VERSION ""

NS_ :

BS_:

BU_: ACM APIM APIM_CDC APIM_CIM APIM_CISM ARM DSP ESPM FCIMB GENERIC GWM HUD_ADV IPC MRCMB_RDAPM_HS3 RACM_RCIM TRM_ITRM TSTR WCM WCMB WCMC

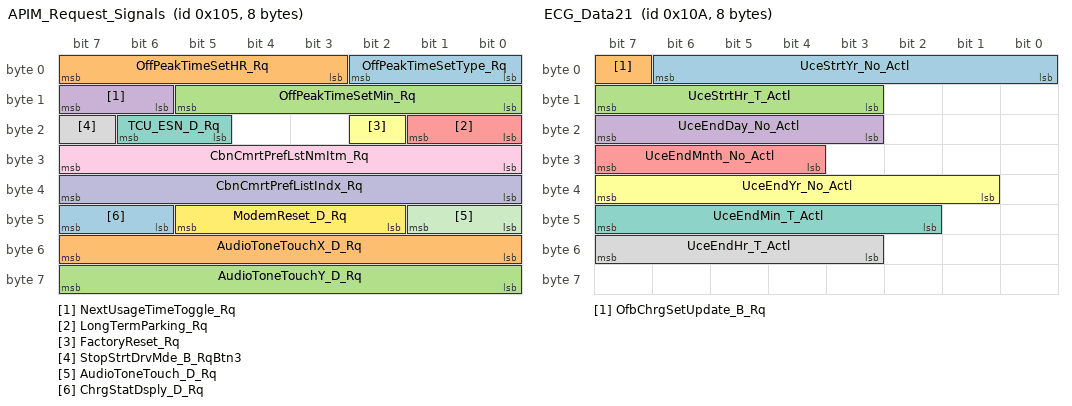
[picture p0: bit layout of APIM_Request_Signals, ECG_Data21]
BO_ 261 APIM_Request_Signals: 8 APIM_CDC
 SG_ OffPeakTimeSetType_Rq : 2|3@0+ (1,0) [0|7] "SED"  GWM
 SG_ OffPeakTimeSetHR_Rq : 7|5@0+ (1,0) [0|31] "unitless"  GWM
 SG_ OffPeakTimeSetMin_Rq : 13|6@0+ (1,0) [0|63] "unitless"  GWM
 SG_ NextUsageTimeToggle_Rq : 15|2@0+ (1,0) [0|3] "SED"  GWM
 SG_ LongTermParking_Rq : 17|2@0+ (1,0) [0|3] "SED"  GWM
 SG_ FactoryReset_Rq : 18|1@0+ (1,0) [0|1] "SED"  GWM
 SG_ TCU_ESN_D_Rq : 22|2@0+ (1,0) [0|3] "SED"  GWM
 SG_ StopStrtDrvMde_B_RqBtn3 : 23|1@0+ (1,0) [0|1] "SED"  GWM
 SG_ CbnCmrtPrefLstNmItm_Rq : 31|8@0+ (1,0) [0|255] "unitless"  GWM
 SG_ CbnCmrtPrefListIndx_Rq : 39|8@0+ (1,0) [0|255] "unitless"  GWM
 SG_ AudioToneTouch_D_Rq : 41|2@0+ (1,0) [0|3] "SED"  DSP,GWM
 SG_ ModemReset_D_Rq : 45|4@0+ (1,0) [0|15] "SED"  GWM
 SG_ ChrgStatDsply_D_Rq : 47|2@0+ (1,0) [0|3] "SED"  GWM
 SG_ AudioToneTouchX_D_Rq : 55|8@0+ (1,0) [0|255] "SED"  DSP,GWM
 SG_ AudioToneTouchY_D_Rq : 63|8@0+ (1,0) [0|255] "SED"  DSP,GWM

BO_ 262 APIM_Send_Signals_23: 8 APIM
 SG_ OnbChrgGlblAcMx_I_Rq : 7|8@0+ (1,0) [0|255] "ampere"  GWM
 SG_ OnbChrgSetUpdate_B_Rq : 8|1@0+ (1,0) [0|1] "SED"  GWM
 SG_ OnbChrgGlblDcMx_Pw_Rq : 15|7@0+ (5,0) [0|635] "kilowatt"  GWM
 SG_ OnbChrgSocAcMx_Pc_Rq : 23|7@0+ (1,0) [0|127] "percent"  GWM
 SG_ OnbChrgSocDcMx_Pc_Rq : 31|7@0+ (1,0) [0|127] "percent"  GWM

BO_ 266 ECG_Data21: 8 GWM
 SG_ UceStrtYr_No_Actl : 6|7@0+ (1,2017) [2017|2144] "year"  APIM
 SG_ OfbChrgSetUpdate_B_Rq : 7|1@0+ (1,0) [0|1] "SED"  APIM
 SG_ UceStrtHr_T_Actl : 15|5@0+ (1,0) [0|31] "hour"  APIM
 SG_ UceEndDay_No_Actl : 23|5@0+ (1,1) [1|32] "day"  APIM
 SG_ UceEndMnth_No_Actl : 31|4@0+ (1,1) [1|16] "month"  APIM
 SG_ UceEndYr_No_Actl : 39|7@0+ (1,2017) [2017|2144] "year"  APIM
 SG_ UceEndMin_T_Actl : 47|6@0+ (1,0) [0|63] "minute"  APIM
 SG_ UceEndHr_T_Actl : 55|5@0+ (1,0) [0|31] "hour"  APIM

BO_ 267 IntelPwrData2_HS3: 8 GWM
 SG_ BattChrgIn_E_Actl : 7|12@0+ (50,0) [0|204750] "watt*hour" Vector__XXX
 SG_ BattChrgOut_E_Actl : 11|12@0+ (50,0) [0|204750] "watt*hour" Vector__XXX
 SG_ UceDchrg_E_Actl : 31|12@0+ (50,0) [0|204750] "watt*hour" Vector__XXX
 SG_ GridSrvc02_D_Stat : 35|4@0+ (1,0) [0|15] "SED"  APIM
 SG_ IpwEnbl_B_Stat : 40|1@0+ (1,0) [0|1] "SED"  APIM
 SG_ IpwSocMn_Pc_Actl : 47|7@0+ (1,0) [0|127] "percent" Vector__XXX

BO_ 270 ECG_IntelPwrData6: 8 GWM
 SG_ UceStrtDay_No_Actl : 7|5@0+ (1,1) [1|32] "day"  APIM
 SG_ UceStrtMin_T_Actl : 15|6@0+ (1,0) [0|63] "minute"  APIM
 SG_ UceStrtMnth_No_Actl : 23|4@0+ (1,1) [1|16] "month"  APIM

BO_ 282 ECG_Data15_HS3: 8 GWM
 SG_ HudPersFeat_No_Rq : 7|16@0+ (1,0) [0|65535] "unitless"  HUD_ADV
 SG_ HudPersFeatVal_No_Rq : 23|16@0+ (1,0) [0|65535] "unitless"  HUD_ADV
 SG_ HudPersSrvc_D_Rq : 36|3@0+ (1,0) [0|7] "SED"  HUD_ADV
 SG_ HudPersIndx_No_Rq : 39|3@0+ (1,0) [0|7] "SED"  HUD_ADV
 SG_ HudPersSrvcId_No_Rq : 47|3@0+ (1,0) [0|7] "unitless"  HUD_ADV

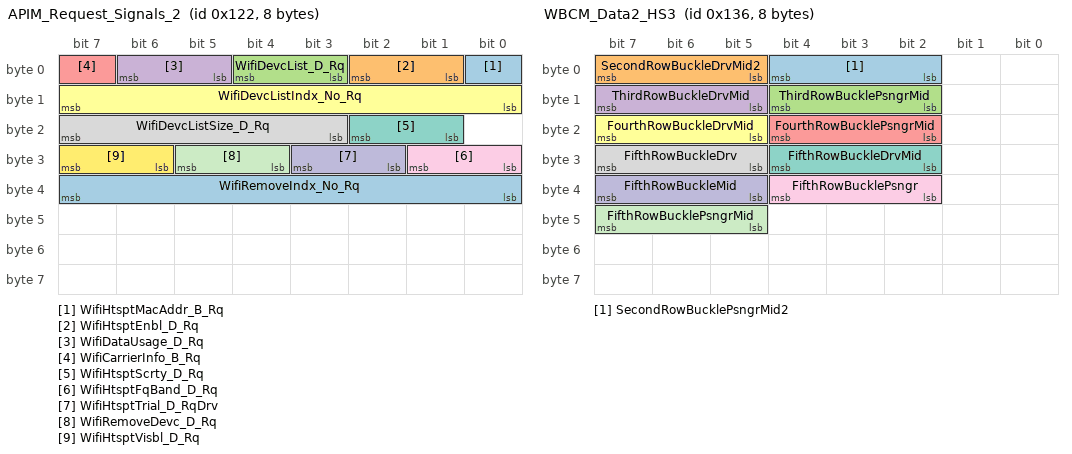
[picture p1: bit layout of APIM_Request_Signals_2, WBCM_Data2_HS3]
BO_ 290 APIM_Request_Signals_2: 8 APIM_CDC
 SG_ WifiHtsptMacAddr_B_Rq : 0|1@0+ (1,0) [0|1] "SED"  GWM
 SG_ WifiHtsptEnbl_D_Rq : 2|2@0+ (1,0) [0|3] "SED"  GWM
 SG_ WifiDevcList_D_Rq : 4|2@0+ (1,0) [0|3] "SED"  GWM
 SG_ WifiDataUsage_D_Rq : 6|2@0+ (1,0) [0|3] "SED"  GWM
 SG_ WifiCarrierInfo_B_Rq : 7|1@0+ (1,0) [0|1] "SED"  GWM
 SG_ WifiDevcListIndx_No_Rq : 15|8@0+ (1,0) [0|255] "unitless"  GWM
 SG_ WifiHtsptScrty_D_Rq : 18|2@0+ (1,0) [0|3] "SED"  GWM
 SG_ WifiDevcListSize_D_Rq : 23|5@0+ (1,0) [0|31] "unitless"  GWM
 SG_ WifiHtsptFqBand_D_Rq : 25|2@0+ (1,0) [0|3] "SED"  GWM
 SG_ WifiHtsptTrial_D_RqDrv : 27|2@0+ (1,0) [0|3] "SED"  GWM
 SG_ WifiRemoveDevc_D_Rq : 29|2@0+ (1,0) [0|3] "SED"  GWM
 SG_ WifiHtsptVisbl_D_Rq : 31|2@0+ (1,0) [0|3] "SED"  GWM
 SG_ WifiRemoveIndx_No_Rq : 39|8@0+ (1,0) [0|255] "unitless"  GWM

BO_ 291 HEC_Response_Signals: 8 IPC
 SG_ LangUpdate_Rsp : 7|2@0+ (1,0) [0|3] "SED"  APIM,APIM_CISM

BO_ 293 ClmtCtrlSeatSet_Stat_v2_HS3: 8 GWM
 SG_ ClmtCtrlSeat_SetStat_Dvr : 7|8@0+ (1,0) [0|254] "SED" Vector__XXX
 SG_ ClmtCtrlSeat_SetStat_Psgr : 15|8@0+ (1,0) [0|254] "SED" Vector__XXX
 SG_ PdlAutoSav_D_Stat : 19|2@0+ (1,0) [0|3] "SED"  APIM_CDC,APIM_CIM
 SG_ SeatAutoSavDrv_D_Stat : 21|2@0+ (1,0) [0|3] "SED"  APIM_CDC,APIM_CIM
 SG_ SteAutoSav_D_Stat : 23|2@0+ (1,0) [0|3] "SED"  APIM_CDC,APIM_CIM

BO_ 298 SDARS_Status_Msg_3: 8 APIM_CDC
 SG_ SdarsSrvcId_No2_Actl2 : 7|16@0+ (1,0) [0|65535] "Unitless"  ACM,IPC,RACM_RCIM

BO_ 300 Av_VdsPrimData_HS3: 8 GWM
 SG_ VdsSftyDrv_D_Rq : 15|2@0+ (1,0) [0|3] "SED"  APIM_CDC
 SG_ PwTest_B_Rdy : 63|1@0+ (1,0) [0|1] "SED" Vector__XXX

BO_ 303 Body_Info_16_HS3: 8 GWM
 SG_ CanMsg12F_No_Crc : 7|8@0+ (1,0) [0|255] "Unitless"  APIM_CDC,APIM_CIM,IPC
 SG_ CanMsg12F_No_Cnt : 11|4@0+ (1,0) [0|15] "Unitless"  APIM_CDC,APIM_CIM,IPC
 SG_ CanMsg12F_UNUSED_1bit_1 : 12|1@0+ (1,0) [1|1] "unitless"  APIM_CDC,APIM_CIM,IPC
 SG_ DrStatHood_D2_Actl : 15|3@0+ (1,0) [0|7] "SED"  APIM_CDC,APIM_CIM,IPC
 SG_ CanMsg12F_UNUSED_2bit_1 : 17|2@0+ (1,0) [3|3] "unitless"  APIM_CDC,APIM_CIM,IPC
 SG_ CanMsg12F_UNUSED_3bit_1 : 20|3@0+ (1,0) [7|7] "unitless"  APIM_CDC,APIM_CIM,IPC
 SG_ DrChildLckPw_No_Actl : 23|3@0+ (1,0) [0|7] "unitless"  APIM_CDC,APIM_CIM,IPC
 SG_ DrTgateAjar_D_Stat : 25|2@0+ (1,0) [0|3] "SED"  IPC
 SG_ DrSwtchExtFr_No_Actl : 28|3@0+ (1,0) [0|7] "unitless" Vector__XXX
 SG_ DrSwtchExtFl_No_Actl : 31|3@0+ (1,0) [0|7] "unitless" Vector__XXX
 SG_ CanMsg12F_UNUSED_2bit_2 : 33|2@0+ (1,0) [3|3] "unitless"  APIM_CDC,APIM_CIM,IPC
 SG_ DrSwtchExtRr_No_Actl : 36|3@0+ (1,0) [0|7] "unitless" Vector__XXX
 SG_ DrSwtchExtRl_No_Actl : 39|3@0+ (1,0) [0|7] "unitless" Vector__XXX
 SG_ CanMsg12F_UNUSED_2bit_3 : 41|2@0+ (1,0) [3|3] "unitless"  APIM_CDC,APIM_CIM,IPC
 SG_ DrSwtchInnrFr_No_Actl : 44|3@0+ (1,0) [0|7] "unitless" Vector__XXX
 SG_ DrSwtchInnrFl_No_Actl : 47|3@0+ (1,0) [0|7] "unitless" Vector__XXX
 SG_ CanMsg12F_UNUSED_2bit_4 : 49|2@0+ (1,0) [3|3] "unitless"  APIM_CDC,APIM_CIM,IPC
 SG_ DrSwtchInnrRr_No_Actl : 52|3@0+ (1,0) [0|7] "unitless" Vector__XXX
 SG_ DrSwtchInnrRl_No_Actl : 55|3@0+ (1,0) [0|7] "unitless" Vector__XXX
 SG_ CanMsg12F_UNUSED_8bit_1 : 63|8@0+ (1,0) [255|255] "unitless"  APIM_CDC,APIM_CIM,IPC

BO_ 307 Av_BrkPrimData_01_HS3: 8 GWM
 SG_ BrkVlePrim_No_Cs : 7|8@0+ (1,0) [0|255] "unitless" Vector__XXX
 SG_ BrkVlePrim_No_Cnt : 11|4@0+ (1,0) [0|15] "unitless" Vector__XXX
 SG_ BrkAbsPrim_B_Falt : 16|1@0+ (1,0) [0|1] "SED" Vector__XXX
 SG_ BrkDfaltPrim_B_Stat : 17|1@0+ (1,0) [0|1] "SED" Vector__XXX
 SG_ BrkEbdPrim_B_Falt : 18|1@0+ (1,0) [0|1] "SED" Vector__XXX
 SG_ BrkEpbPrim_B_Falt : 19|1@0+ (1,0) [0|1] "SED" Vector__XXX
 SG_ BrkRedndncyPrim_B_Falt : 20|1@0+ (1,0) [0|1] "SED" Vector__XXX
 SG_ BrkStabCtlPrim_B_Falt : 21|1@0+ (1,0) [0|1] "SED" Vector__XXX
 SG_ BrkTracCtlPrim_B_Falt : 22|1@0+ (1,0) [0|1] "SED" Vector__XXX
 SG_ AvmcPrim_No_Cs : 31|8@0+ (1,0) [0|255] "unitless" Vector__XXX
 SG_ AvmcPrim_No_Cnt : 35|4@0+ (1,0) [0|15] "unitless" Vector__XXX
 SG_ AvMtnCtlPrim_D_Stat : 38|3@0+ (1,0) [0|7] "SED"  APIM_CDC
 SG_ PrkPrim_B_Stat : 40|1@0+ (1,0) [0|1] "SED"  APIM_CDC
 SG_ MobcVLimPrim_D_Stat : 42|2@0+ (1,0) [0|3] "SED"  APIM_CDC
 SG_ LongCtlSrcPrim_D_Actl : 44|2@0+ (1,0) [0|3] "SED" Vector__XXX
 SG_ GearLvrPrim_D_Rq : 47|3@0+ (1,0) [0|7] "SED" Vector__XXX
 SG_ PrplWhlTotPrim1_Tq_Rq : 55|16@0+ (4,-131072) [-131072|131068] "Nm" Vector__XXX

BO_ 310 WBCM_Data2_HS3: 8 GWM
 SG_ SecondRowBucklePsngrMid2 : 4|3@0+ (1,0) [0|7] "SED"  APIM_CDC,APIM_CIM,IPC
 SG_ SecondRowBuckleDrvMid2 : 7|3@0+ (1,0) [0|7] "SED"  APIM_CDC,APIM_CIM,IPC
 SG_ ThirdRowBucklePsngrMid : 12|3@0+ (1,0) [0|7] "SED"  APIM_CDC,APIM_CIM,IPC
 SG_ ThirdRowBuckleDrvMid : 15|3@0+ (1,0) [0|7] "SED"  APIM_CDC,APIM_CIM,IPC
 SG_ FourthRowBucklePsngrMid : 20|3@0+ (1,0) [0|7] "SED"  APIM_CDC,APIM_CIM,IPC
 SG_ FourthRowBuckleDrvMid : 23|3@0+ (1,0) [0|7] "SED"  APIM_CDC,APIM_CIM,IPC
 SG_ FifthRowBuckleDrvMid : 28|3@0+ (1,0) [0|7] "SED"  APIM_CDC,APIM_CIM,IPC
 SG_ FifthRowBuckleDrv : 31|3@0+ (1,0) [0|7] "SED"  APIM_CDC,APIM_CIM,IPC
 SG_ FifthRowBucklePsngr : 36|3@0+ (1,0) [0|7] "SED"  APIM_CDC,APIM_CIM,IPC
 SG_ FifthRowBuckleMid : 39|3@0+ (1,0) [0|7] "SED"  APIM_CDC,APIM_CIM,IPC
 SG_ FifthRowBucklePsngrMid : 47|3@0+ (1,0) [0|7] "SED"  APIM_CDC,APIM_CIM,IPC

BO_ 317 APIM_Send_Signals_22: 8 APIM_CIM
 SG_ VehPtch_An_Actl : 7|8@0+ (1,-90) [-90|165] "degrees"  GWM

BO_ 330 TransData_3_HS3: 8 GWM
 SG_ TrnFaltOpenClu_B_Stat : 5|1@0+ (1,0) [0|1] "SED" Vector__XXX
 SG_ TrnAout_W_ActlUnfilt : 22|15@0+ (0.1,0) [0|3276.7] "rad/s"  ACM,APIM_CDC,APIM_CIM,APIM_CISM

BO_ 331 HEV_Powertrain_Data5_HS3: 8 GWM
 SG_ TrnAout2ActlUflt_No_Cs : 7|8@0+ (1,0) [0|255] "unitless" Vector__XXX
 SG_ TrnAout2ActUflt_No_Cnt : 15|4@0+ (1,0) [0|15] "unitless" Vector__XXX
 SG_ TrnAout2_W_ActlUnfilt : 23|16@0+ (0.1,-3276.5) [-3276.5|3277] "rad/s"  ACM,APIM_CDC,APIM_CIM,APIM_CISM
 SG_ HtrnAin_N_RqMnPrtct : 36|13@0+ (2,0) [0|16382] "RPM" Vector__XXX
 SG_ CmbbEngTqMn_B_ActlHtrn : 37|1@0+ (1,0) [0|1] "SED" Vector__XXX
 SG_ CmbbDeny_B_ActlHtrn : 38|1@0+ (1,0) [0|1] "SED" Vector__XXX

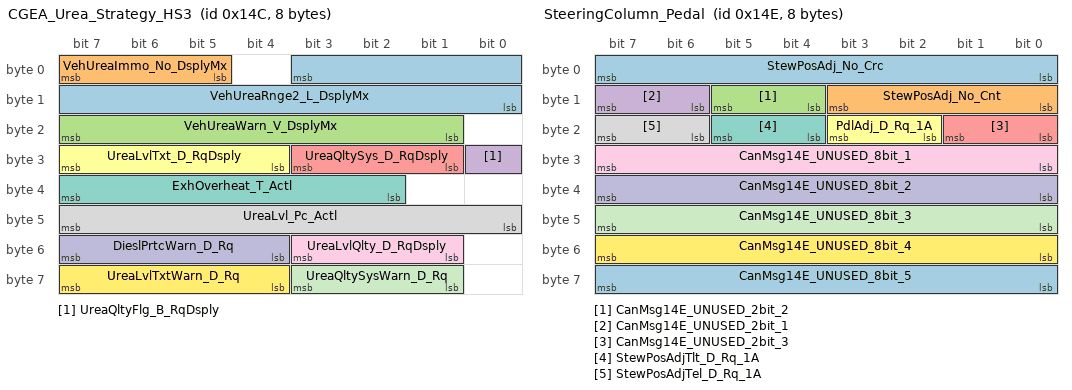
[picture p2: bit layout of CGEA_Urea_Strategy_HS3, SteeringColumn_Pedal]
BO_ 332 CGEA_Urea_Strategy_HS3: 8 GWM
 SG_ VehUreaRnge2_L_DsplyMx : 3|12@0+ (1,0) [0|4095] "kilometer"  APIM_CDC,APIM_CIM,APIM_CISM,IPC
 SG_ VehUreaImmo_No_DsplyMx : 7|3@0+ (1,0) [0|7] "Counts"  APIM_CDC,APIM_CIM,IPC
 SG_ VehUreaWarn_V_DsplyMx : 23|7@0+ (1,0) [0|127] "km/h"  APIM_CDC,APIM_CIM,APIM_CISM,IPC
 SG_ UreaQltyFlg_B_RqDsply : 24|1@0+ (1,0) [0|1] "SED"  APIM_CDC,APIM_CIM,APIM_CISM,IPC
 SG_ UreaQltySys_D_RqDsply : 27|3@0+ (1,0) [0|7] "SED"  APIM_CDC,APIM_CIM,APIM_CISM,IPC
 SG_ UreaLvlTxt_D_RqDsply : 31|4@0+ (1,0) [0|15] "SED"  APIM_CDC,APIM_CIM,APIM_CISM,IPC
 SG_ ExhOverheat_T_Actl : 39|6@0+ (1,0) [0|63] "minute"  APIM_CDC,APIM_CIM,IPC
 SG_ UreaLvl_Pc_Actl : 47|8@0+ (0.4,0) [0|102] "percent"  APIM_CDC,APIM_CIM,APIM_CISM,IPC
 SG_ UreaLvlQlty_D_RqDsply : 51|3@0+ (1,0) [0|7] "SED"  APIM_CDC,APIM_CIM,APIM_CISM,IPC
 SG_ DieslPrtcWarn_D_Rq : 55|4@0+ (1,0) [0|15] "SED"  APIM_CDC,APIM_CIM,IPC
 SG_ UreaQltySysWarn_D_Rq : 59|3@0+ (1,0) [0|7] "SED"  APIM_CDC,APIM_CIM,APIM_CISM,IPC
 SG_ UreaLvlTxtWarn_D_Rq : 63|4@0+ (1,0) [0|15] "SED"  APIM_CDC,APIM_CIM,APIM_CISM,IPC

BO_ 333 HEV_Powertrain_Data11_HS3: 8 GWM
 SG_ VehElAvgTrip1_Eff2_Dsply : 7|11@0+ (1,-200) [-200|1847] "watt*hour/km"  APIM,IPC
 SG_ VehElAvgTrip2_Eff2_Dsply : 12|11@0+ (1,-200) [-200|1847] "watt*hour/km"  APIM,IPC
 SG_ VehElEffTrip_No2_Dsply : 17|11@0+ (1,-200) [-200|1847] "watt*hour/km"  APIM,IPC
 SG_ VehElEffAvg_No2_Dsply : 38|11@0+ (1,-200) [-200|1847] "watt*hour/km"  APIM,IPC

BO_ 334 SteeringColumn_Pedal: 8 APIM_CDC
 SG_ StewPosAdj_No_Crc : 7|8@0+ (1,0) [0|255] "unitless"  GWM
 SG_ StewPosAdj_No_Cnt : 11|4@0+ (1,0) [0|15] "unitless"  GWM
 SG_ CanMsg14E_UNUSED_2bit_2 : 13|2@0+ (1,0) [3|3] "unitless"  GWM
 SG_ CanMsg14E_UNUSED_2bit_1 : 15|2@0+ (1,0) [3|3] "unitless"  GWM
 SG_ CanMsg14E_UNUSED_2bit_3 : 17|2@0+ (1,0) [3|3] "unitless"  GWM
 SG_ PdlAdj_D_Rq_1A : 19|2@0+ (1,0) [0|3] "SED"  GWM
 SG_ StewPosAdjTlt_D_Rq_1A : 21|2@0+ (1,0) [0|3] "SED"  GWM
 SG_ StewPosAdjTel_D_Rq_1A : 23|2@0+ (1,0) [0|3] "SED"  GWM
 SG_ CanMsg14E_UNUSED_8bit_1 : 31|8@0+ (1,0) [255|255] "unitless"  GWM
 SG_ CanMsg14E_UNUSED_8bit_2 : 39|8@0+ (1,0) [255|255] "unitless"  GWM
 SG_ CanMsg14E_UNUSED_8bit_3 : 47|8@0+ (1,0) [255|255] "unitless"  GWM
 SG_ CanMsg14E_UNUSED_8bit_4 : 55|8@0+ (1,0) [255|255] "unitless"  GWM
 SG_ CanMsg14E_UNUSED_8bit_5 : 63|8@0+ (1,0) [255|255] "unitless"  GWM

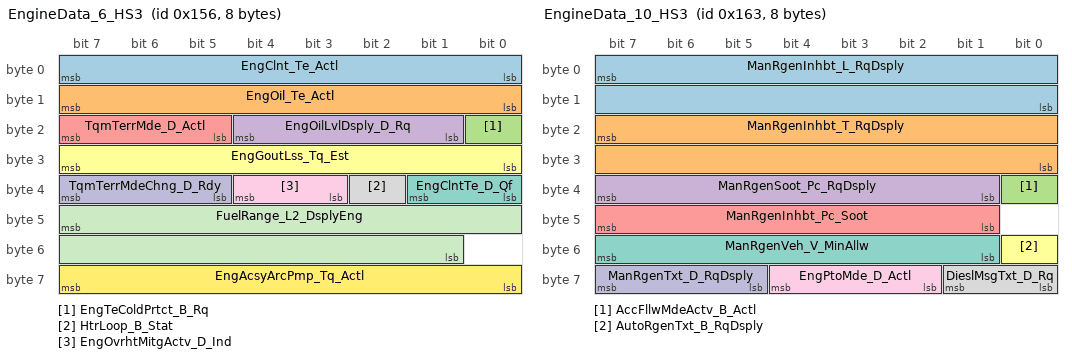
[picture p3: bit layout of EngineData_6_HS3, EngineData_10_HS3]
BO_ 342 EngineData_6_HS3: 8 GWM
 SG_ EngClnt_Te_Actl : 7|8@0+ (1,-60) [-60|195] "degC"  APIM,APIM_CDC,APIM_CIM,APIM_CISM,IPC
 SG_ EngOil_Te_Actl : 15|8@0+ (1,-60) [-60|195] "degC"  APIM,APIM_CDC,APIM_CIM,APIM_CISM,IPC
 SG_ EngTeColdPrtct_B_Rq : 16|1@0+ (1,0) [0|1] "SED"  APIM_CDC,APIM_CIM,IPC
 SG_ EngOilLvlDsply_D_Rq : 20|4@0+ (1,0) [0|15] "SED"  APIM_CDC,APIM_CIM,IPC
 SG_ TqmTerrMde_D_Actl : 23|3@0+ (1,0) [0|7] "SED"  IPC
 SG_ EngGoutLss_Tq_Est : 31|8@0+ (1,0) [0|255] "Nm"  IPC
 SG_ EngClntTe_D_Qf : 33|2@0+ (1,0) [0|3] "SED"  APIM_CDC,APIM_CIM,IPC
 SG_ HtrLoop_B_Stat : 34|1@0+ (1,0) [0|1] "SED"  IPC
 SG_ EngOvrhtMitgActv_D_Ind : 36|2@0+ (1,0) [0|3] "SED"  APIM_CDC,APIM_CIM,IPC
 SG_ TqmTerrMdeChng_D_Rdy : 39|3@0+ (1,0) [0|7] "SED"  IPC
 SG_ FuelRange_L2_DsplyEng : 47|15@0+ (0.1,0) [0|3276.7] "kilometer"  APIM_CDC,APIM_CIM,IPC
 SG_ EngAcsyArcPmp_Tq_Actl : 63|8@0+ (0.5,0) [0|127.5] "Nm"  IPC

BO_ 355 EngineData_10_HS3: 8 GWM
 SG_ ManRgenInhbt_L_RqDsply : 7|16@0+ (1,0) [0|65535] "kilometer"  APIM_CDC,APIM_CIM,APIM_CISM,IPC
 SG_ ManRgenInhbt_T_RqDsply : 23|16@0+ (1,0) [0|65535] "minute"  APIM_CDC,APIM_CIM,APIM_CISM,IPC
 SG_ AccFllwMdeActv_B_Actl : 32|1@0+ (1,0) [0|1] "SED"  GENERIC
 SG_ ManRgenSoot_Pc_RqDsply : 39|7@0+ (1,0) [0|127] "%"  APIM_CDC,APIM_CIM,APIM_CISM,IPC
 SG_ ManRgenInhbt_Pc_Soot : 47|7@0+ (1,0) [0|127] "%"  APIM_CDC,APIM_CIM,APIM_CISM,IPC
 SG_ AutoRgenTxt_B_RqDsply : 48|1@0+ (1,0) [0|1] "SED"  APIM_CDC,APIM_CIM,IPC
 SG_ ManRgenVeh_V_MinAllw : 55|7@0+ (1,0) [0|127] "kilometer/hour"  APIM_CDC,APIM_CIM,APIM_CISM,IPC
 SG_ DieslMsgTxt_D_Rq : 57|2@0+ (1,0) [0|3] "SED"  APIM_CDC,APIM_CIM,IPC
 SG_ EngPtoMde_D_Actl : 60|3@0+ (1,0) [0|7] "SED"  IPC
 SG_ ManRgenTxt_D_RqDsply : 63|3@0+ (1,0) [0|7] "SED"  APIM_CDC,APIM_CIM,APIM_CISM,IPC

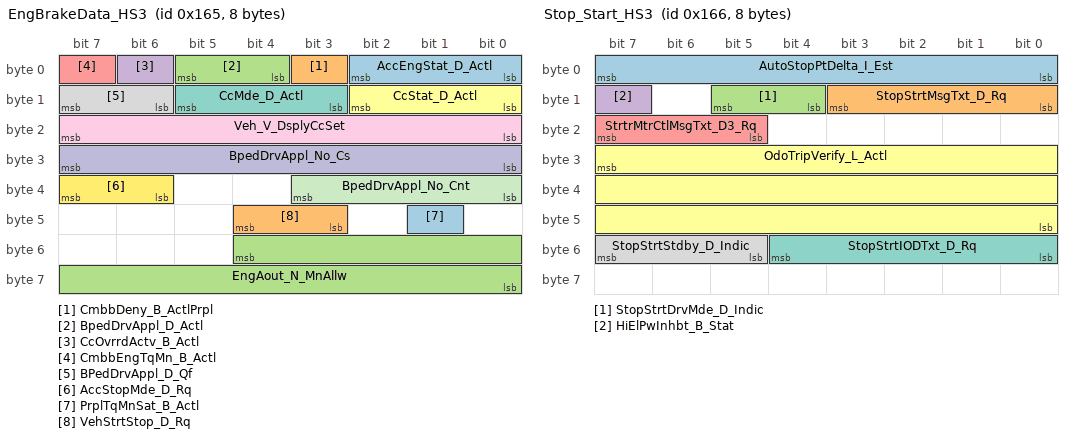
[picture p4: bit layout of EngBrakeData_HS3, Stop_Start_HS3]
BO_ 357 EngBrakeData_HS3: 8 GWM
 SG_ AccEngStat_D_Actl : 2|3@0+ (1,0) [0|7] "SED" Vector__XXX
 SG_ CmbbDeny_B_ActlPrpl : 3|1@0+ (1,0) [0|1] "SED" Vector__XXX
 SG_ BpedDrvAppl_D_Actl : 5|2@0+ (1,0) [0|3] "SED"  APIM,APIM_CDC,APIM_CIM,APIM_CISM,IPC,TRM_ITRM
 SG_ CcOvrrdActv_B_Actl : 6|1@0+ (1,0) [0|1] "SED"  APIM_CDC,APIM_CIM,HUD_ADV,IPC
 SG_ CmbbEngTqMn_B_Actl : 7|1@0+ (1,0) [0|1] "SED" Vector__XXX
 SG_ CcStat_D_Actl : 10|3@0+ (1,0) [0|7] "SED"  APIM_CDC,APIM_CIM,HUD_ADV,IPC
 SG_ CcMde_D_Actl : 13|3@0+ (1,0) [0|7] "SED" Vector__XXX
 SG_ BPedDrvAppl_D_Qf : 15|2@0+ (1,0) [0|3] "SED" Vector__XXX
 SG_ Veh_V_DsplyCcSet : 23|8@0+ (1,0) [0|255] "unitless"  APIM_CDC,APIM_CIM,HUD_ADV,IPC
 SG_ BpedDrvAppl_No_Cs : 31|8@0+ (1,0) [0|255] "unitless" Vector__XXX
 SG_ BpedDrvAppl_No_Cnt : 35|4@0+ (1,0) [0|15] "unitless" Vector__XXX
 SG_ AccStopMde_D_Rq : 39|2@0+ (1,0) [0|3] "SED" Vector__XXX
 SG_ PrplTqMnSat_B_Actl : 41|1@0+ (1,0) [0|1] "SED" Vector__XXX
 SG_ VehStrtStop_D_Rq : 44|2@0+ (1,0) [0|3] "SED" Vector__XXX
 SG_ EngAout_N_MnAllw : 52|13@0+ (2,0) [0|16382] "rpm" Vector__XXX

BO_ 358 Stop_Start_HS3: 8 GWM
 SG_ AutoStopPtDelta_I_Est : 7|8@0+ (1,-127) [-127|128] "Amps"  GENERIC
 SG_ StopStrtMsgTxt_D_Rq : 11|4@0+ (1,0) [0|15] "SED"  APIM_CDC,APIM_CIM,IPC
 SG_ StopStrtDrvMde_D_Indic : 13|2@0+ (1,0) [0|3] "SED"  APIM,APIM_CDC,APIM_CIM,APIM_CISM,IPC
 SG_ HiElPwInhbt_B_Stat : 15|1@0+ (1,0) [0|1] "SED"  GENERIC
 SG_ StrtrMtrCtlMsgTxt_D3_Rq : 23|3@0+ (1,0) [0|7] "SED"  APIM,APIM_CDC,APIM_CIM
 SG_ OdoTripVerify_L_Actl : 31|24@0+ (0.1,0) [0|1677721.5] "km"  APIM_CDC,APIM_CIM,IPC
 SG_ StopStrtIODTxt_D_Rq : 52|5@0+ (1,0) [0|31] "SED"  APIM_CDC,APIM_CIM,APIM_CISM,IPC
 SG_ StopStrtStdby_D_Indic : 55|3@0+ (1,0) [0|7] "SED"  APIM_CDC,APIM_CIM,APIM_CISM,IPC

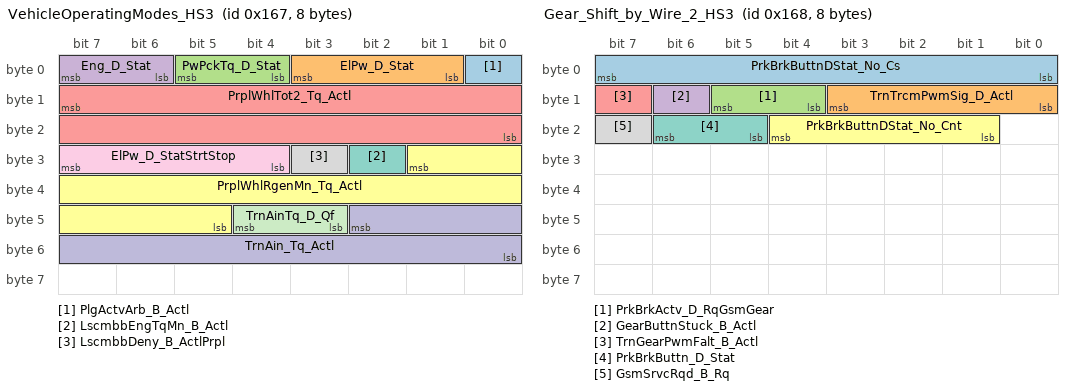
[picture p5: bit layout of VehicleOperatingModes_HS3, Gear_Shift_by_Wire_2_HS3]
BO_ 359 VehicleOperatingModes_HS3: 8 GWM
 SG_ PlgActvArb_B_Actl : 0|1@0+ (1,0) [0|1] "SED"  APIM_CDC,IPC
 SG_ ElPw_D_Stat : 3|3@0+ (1,0) [0|7] "SED"  ACM,APIM,APIM_CDC,APIM_CIM,APIM_CISM,DSP,IPC,RACM_RCIM,TRM_ITRM
 SG_ PwPckTq_D_Stat : 5|2@0+ (1,0) [0|3] "SED"  ACM,APIM,APIM_CDC,APIM_CIM,APIM_CISM,DSP,IPC,RACM_RCIM,TRM_ITRM,WCM,WCMB,WCMC
 SG_ Eng_D_Stat : 7|2@0+ (1,0) [0|3] "SED"  ACM,APIM,APIM_CDC,APIM_CIM,APIM_CISM,DSP,RACM_RCIM,TRM_ITRM,WCM,WCMB,WCMC
 SG_ PrplWhlTot2_Tq_Actl : 15|16@0+ (4,-131072) [-131072|131068] "Nm"  APIM,APIM_CDC,APIM_CIM,APIM_CISM,IPC
 SG_ PrplWhlRgenMn_Tq_Actl : 25|13@0+ (4,-16380) [-16380|16384] "Nm"  GENERIC
 SG_ LscmbbEngTqMn_B_Actl : 26|1@0+ (1,0) [0|1] "SED"  GENERIC
 SG_ LscmbbDeny_B_ActlPrpl : 27|1@0+ (1,0) [0|1] "SED"  GENERIC
 SG_ ElPw_D_StatStrtStop : 31|4@0+ (1,0) [0|15] "SED"  GENERIC
 SG_ TrnAin_Tq_Actl : 42|11@0+ (1,-500) [-500|1547] "Nm"  ACM,APIM,APIM_CDC,APIM_CIM,APIM_CISM,IPC
 SG_ TrnAinTq_D_Qf : 44|2@0+ (1,0) [0|3] "SED"  APIM_CIM,ACM,APIM_CDC,APIM_CISM

BO_ 360 Gear_Shift_by_Wire_2_HS3: 8 GWM
 SG_ PrkBrkButtnDStat_No_Cs : 7|8@0+ (1,0) [0|255] "unitless" Vector__XXX
 SG_ TrnTrcmPwmSig_D_Actl : 11|4@0+ (1,0) [0|15] "SED"  GENERIC
 SG_ PrkBrkActv_D_RqGsmGear : 13|2@0+ (1,0) [0|3] "SED" Vector__XXX
 SG_ GearButtnStuck_B_Actl : 14|1@0+ (1,0) [0|1] "SED"  GENERIC
 SG_ TrnGearPwmFalt_B_Actl : 15|1@0+ (1,0) [0|1] "SED"  GENERIC
 SG_ PrkBrkButtnDStat_No_Cnt : 20|4@0+ (1,0) [0|15] "unitless" Vector__XXX
 SG_ PrkBrkButtn_D_Stat : 22|2@0+ (1,0) [0|3] "SED" Vector__XXX
 SG_ GsmSrvcRqd_B_Rq : 23|1@0+ (1,0) [0|1] "SED"  APIM_CDC,APIM_CIM,IPC

BO_ 366 Av_RDAPM_Data4: 8 MRCMB_RDAPM_HS3
 SG_ AprTvfTripId1_No_Actl : 7|64@0+ (1,0) [0|1.84467440737096E+019] "unitless"  GWM

BO_ 367 Av_ECGtoDAP_HS3: 8 GWM
 SG_ AuthctnInfoId_No_Actl : 7|32@0+ (1,0) [0|4294967295] "unitless"  MRCMB_RDAPM_HS3
 SG_ AuthctnInfo_D_Stat : 33|2@0+ (1,0) [0|3] "SED"  MRCMB_RDAPM_HS3
 SG_ AuthctnInfoIndx_No_Actl : 39|6@0+ (1,0) [0|63] "unitless"  MRCMB_RDAPM_HS3
 SG_ AuthctnStat_D_Stat : 44|2@0+ (1,0) [0|3] "SED"  MRCMB_RDAPM_HS3
 SG_ AuthctnInfoLoc_D_Stat : 47|3@0+ (1,0) [0|7] "SED"  MRCMB_RDAPM_HS3
 SG_ AuthctnStatChnl_D_Stat : 51|4@0+ (1,0) [0|15] "SED"  MRCMB_RDAPM_HS3
 SG_ AuthctnStatRtry_No_Actl : 55|4@0+ (1,0) [0|15] "unitless"  MRCMB_RDAPM_HS3
 SG_ AuthctnStatId_No_Actl : 63|32@0+ (1,0) [0|4294967295] "unitless"  MRCMB_RDAPM_HS3
 SG_ ApnlPsswrdId_No_Actl : 95|32@0+ (1,0) [0|4294967295] "unitless"  MRCMB_RDAPM_HS3
 SG_ ApnlPsswrdType_D_Stat : 121|4@0+ (1,0) [0|15] "SED"  MRCMB_RDAPM_HS3
 SG_ AuthctnStatIndx_No_Actl : 127|6@0+ (1,0) [0|63] "unitless"  MRCMB_RDAPM_HS3
 SG_ ApnlPsswrdIndx_No_Actl : 133|6@0+ (1,0) [0|63] "unitless"  MRCMB_RDAPM_HS3
 SG_ HashId_No_Actl : 143|32@0+ (1,0) [0|4294967295] "unitless"  MRCMB_RDAPM_HS3
 SG_ HashIndx_D_Stat : 169|2@0+ (1,0) [0|3] "SED"  MRCMB_RDAPM_HS3
 SG_ HashIndx_No_Actl : 175|6@0+ (1,0) [0|63] "unitless"  MRCMB_RDAPM_HS3
 SG_ HashSalt1_No_Res : 183|64@0+ (1,0) [0|1.84467440737096E+019] "unitless"  MRCMB_RDAPM_HS3
 SG_ HashSalt2_No_Res : 247|64@0+ (1,0) [0|1.84467440737096E+019] "unitless"  MRCMB_RDAPM_HS3
 SG_ HashNonce1_No_Res : 311|64@0+ (1,0) [0|1.84467440737096E+019] "unitless"  MRCMB_RDAPM_HS3
 SG_ HashNonce2_No_Res : 375|64@0+ (1,0) [0|1.84467440737096E+019] "unitless"  MRCMB_RDAPM_HS3

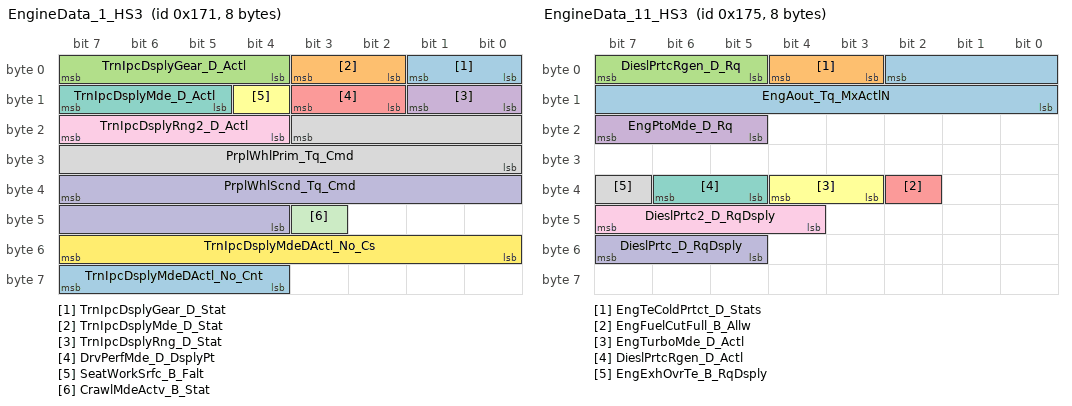
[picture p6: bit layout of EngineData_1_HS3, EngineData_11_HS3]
BO_ 369 EngineData_1_HS3: 8 GWM
 SG_ TrnIpcDsplyGear_D_Stat : 1|2@0+ (1,0) [0|3] "SED"  APIM_CDC,APIM_CIM,HUD_ADV,IPC
 SG_ TrnIpcDsplyMde_D_Stat : 3|2@0+ (1,0) [0|3] "SED"  APIM_CDC,APIM_CIM,HUD_ADV,IPC
 SG_ TrnIpcDsplyGear_D_Actl : 7|4@0+ (1,0) [0|15] "SED"  APIM,APIM_CDC,APIM_CIM,APIM_CISM,HUD_ADV,IPC
 SG_ TrnIpcDsplyRng_D_Stat : 9|2@0+ (1,0) [0|3] "SED"  APIM_CDC,APIM_CIM,IPC
 SG_ DrvPerfMde_D_DsplyPt : 11|2@0+ (1,0) [0|3] "SED"  GENERIC
 SG_ SeatWorkSrfc_B_Falt : 12|1@0+ (1,0) [0|1] "SED"  APIM_CDC,APIM_CIM,IPC
 SG_ TrnIpcDsplyMde_D_Actl : 15|3@0+ (1,0) [0|7] "SED"  APIM_CDC,APIM_CIM,APIM_CISM,HUD_ADV,IPC
 SG_ PrplWhlPrim_Tq_Cmd : 19|12@0+ (8,-16380) [-16380|16380] "Nm"  GENERIC
 SG_ TrnIpcDsplyRng2_D_Actl : 23|4@0+ (1,0) [0|15] "SED"  APIM_CDC,APIM_CIM,IPC
 SG_ PrplWhlScnd_Tq_Cmd : 39|12@0+ (8,-16380) [-16380|16380] "Nm"  GENERIC
 SG_ CrawlMdeActv_B_Stat : 43|1@0+ (1,0) [0|1] "SED"  APIM_CDC,APIM_CIM,IPC
 SG_ TrnIpcDsplyMdeDActl_No_Cs : 55|8@0+ (1,0) [0|255] "Unitless"  APIM_CDC,APIM_CIM,IPC
 SG_ TrnIpcDsplyMdeDActl_No_Cnt : 63|4@0+ (1,0) [0|15] "Unitless"  APIM_CDC,APIM_CIM,IPC

BO_ 373 EngineData_11_HS3: 8 GWM
 SG_ EngAout_Tq_MxActlN : 2|11@0+ (1,-500) [-500|1547] "Nm" Vector__XXX
 SG_ EngTeColdPrtct_D_Stats : 4|2@0+ (1,0) [0|3] "SED"  APIM_CDC,APIM_CIM,IPC
 SG_ DieslPrtcRgen_D_Rq : 7|3@0+ (1,0) [0|7] "SED"  APIM_CDC,APIM_CIM,APIM_CISM,IPC
 SG_ EngPtoMde_D_Rq : 23|3@0+ (1,0) [0|7] "SED"  IPC
 SG_ EngFuelCutFull_B_Allw : 34|1@0+ (1,0) [0|1] "SED"  GENERIC
 SG_ EngTurboMde_D_Actl : 36|2@0+ (1,0) [0|3] "SED"  IPC
 SG_ DieslPrtcRgen_D_Actl : 38|2@0+ (1,0) [0|3] "SED"  IPC
 SG_ EngExhOvrTe_B_RqDsply : 39|1@0+ (1,0) [0|1] "SED"  APIM_CDC,APIM_CIM,IPC
 SG_ DieslPrtc2_D_RqDsply : 47|4@0+ (1,0) [0|15] "SED"  APIM_CDC,APIM_CIM,APIM_CISM,IPC
 SG_ DieslPrtc_D_RqDsply : 55|3@0+ (1,0) [0|7] "SED"  APIM_CDC,APIM_CIM,APIM_CISM,IPC

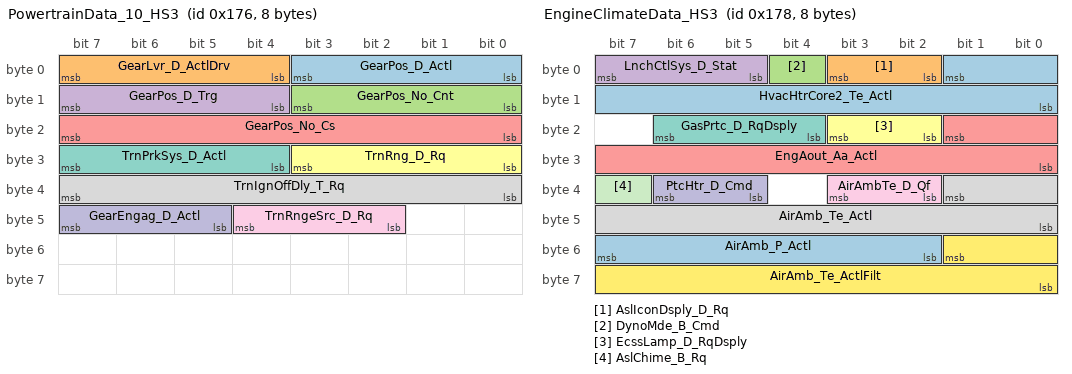
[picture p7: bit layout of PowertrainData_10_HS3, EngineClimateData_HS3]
BO_ 374 PowertrainData_10_HS3: 8 GWM
 SG_ GearPos_D_Actl : 3|4@0+ (1,0) [0|15] "SED"  APIM,APIM_CDC,APIM_CIM,APIM_CISM
 SG_ GearLvr_D_ActlDrv : 7|4@0+ (1,0) [0|15] "SED" Vector__XXX
 SG_ GearPos_No_Cnt : 11|4@0+ (1,0) [0|15] "unitless" Vector__XXX
 SG_ GearPos_D_Trg : 15|4@0+ (1,0) [0|15] "SED"  APIM,APIM_CDC,APIM_CIM,APIM_CISM
 SG_ GearPos_No_Cs : 23|8@0+ (1,0) [0|255] "unitless" Vector__XXX
 SG_ TrnRng_D_Rq : 27|4@0+ (1,0) [0|15] "SED"  APIM,APIM_CDC,APIM_CIM,APIM_CISM
 SG_ TrnPrkSys_D_Actl : 31|4@0+ (1,0) [0|15] "SED"  APIM,APIM_CDC
 SG_ TrnIgnOffDly_T_Rq : 39|8@0+ (4,0) [0|1020] "ms" Vector__XXX
 SG_ TrnRngeSrc_D_Rq : 44|3@0+ (1,0) [0|7] "SED" Vector__XXX
 SG_ GearEngag_D_Actl : 47|3@0+ (1,0) [0|7] "SED"  APIM_CDC,APIM_CIM,IPC

BO_ 376 EngineClimateData_HS3: 8 GWM
 SG_ HvacHtrCore2_Te_Actl : 1|10@0+ (0.25,-50) [-50|205.75] "degC"  APIM_CDC,APIM_CIM,IPC
 SG_ AslIconDsply_D_Rq : 3|2@0+ (1,0) [0|3] "SED"  APIM,APIM_CDC,APIM_CIM,APIM_CISM,IPC
 SG_ DynoMde_B_Cmd : 4|1@0+ (1,0) [0|1] "SED"  GENERIC
 SG_ LnchCtlSys_D_Stat : 7|3@0+ (1,0) [0|7] "SED"  APIM_CDC,APIM_CIM,IPC
 SG_ EngAout_Aa_Actl : 17|10@0+ (0.05,-25.6) [-25.6|25.55] "rpm/ms"  GENERIC
 SG_ EcssLamp_D_RqDsply : 19|2@0+ (1,0) [0|3] "SED"  APIM_CDC,APIM_CIM,IPC
 SG_ GasPrtc_D_RqDsply : 22|3@0+ (1,0) [0|7] "SED"  APIM_CDC,APIM_CIM,IPC
 SG_ AirAmb_Te_Actl : 33|10@0+ (0.25,-128) [-128|127.75] "degC"  APIM_CDC,APIM_CIM,IPC
 SG_ AirAmbTe_D_Qf : 35|2@0+ (1,0) [0|3] "SED"  APIM_CDC,APIM_CIM,IPC
 SG_ PtcHtr_D_Cmd : 38|2@0+ (1,0) [0|3] "SED"  GENERIC
 SG_ AslChime_B_Rq : 39|1@0+ (1,0) [0|1] "SED"  APIM_CDC,APIM_CIM,IPC
 SG_ AirAmb_Te_ActlFilt : 49|10@0+ (0.25,-128) [-128|127.75] "degC"  IPC
 SG_ AirAmb_P_Actl : 55|6@0+ (10,500) [500|1130] "mbar"  APIM,APIM_CDC,APIM_CIM,APIM_CISM,IPC

BO_ 377 EngineData_7_HS3: 8 GWM
 SG_ EngAout_Tq_Actl : 2|11@0+ (1,-500) [-500|1547] "Nm"  ACM,APIM,APIM_CDC,APIM_CIM,APIM_CISM
 SG_ EngAoutTqActl_D_Qf : 4|2@0+ (1,0) [0|3] "SED" Vector__XXX
 SG_ TrnManShif_D_IndDrv : 7|3@0+ (1,0) [0|7] "unitless"  APIM_CDC,APIM_CIM,HUD_ADV,IPC
 SG_ EngTqSlwDly_T_Est : 18|11@0+ (1,0) [0|2047] "ms"  IPC
 SG_ EngSrvcRqd_B_Rq : 19|1@0+ (1,0) [0|1] "SED"  APIM_CDC,APIM_CIM,IPC
 SG_ TrnKickDown_B_RqDrv : 20|1@0+ (1,0) [0|1] "SED"  IPC
 SG_ EngDecelFuelCut_B_Allw : 21|1@0+ (1,0) [0|1] "SED"  IPC
 SG_ EngFuelCutFull_B_Inhbt : 22|1@0+ (1,0) [0|1] "SED"  IPC
 SG_ HvacAirFullOut_B_Rq : 23|1@0+ (1,0) [0|1] "SED"  GENERIC
 SG_ FuelFillInlet_B_Dsply : 32|1@0+ (1,0) [0|1] "SED"  APIM_CDC,APIM_CIM,IPC
 SG_ EngOilLife_Pc_Actl : 39|7@0+ (1,0) [0|100] "percent"  APIM,APIM_CDC,APIM_CIM,APIM_CISM,IPC
 SG_ OdoCount : 47|8@0+ (0.2,0) [0|51] "Meters"  APIM,APIM_CDC,APIM_CIM,APIM_CISM,IPC
 SG_ FuelFlw_Vl_Dsply : 49|10@0+ (25,0) [0|25575] "Micro_Liter"  APIM,APIM_CDC,APIM_CIM,APIM_CISM,IPC
 SG_ FuelFilterLamp_B_Dsply : 50|1@0+ (1,0) [0|1] "SED"  APIM_CDC,APIM_CIM,IPC
 SG_ AirCondClutch_B_Stats : 51|1@0+ (1,0) [0|1] "SED"  IPC,WCM,WCMB,WCMC
 SG_ TrnManShifGear_D_IndDrv : 54|3@0+ (1,0) [0|7] "SED"  APIM_CDC,APIM_CIM,HUD_ADV,IPC
 SG_ AirCondRec_B_Rq : 55|1@0+ (1,0) [0|1] "SED"  IPC

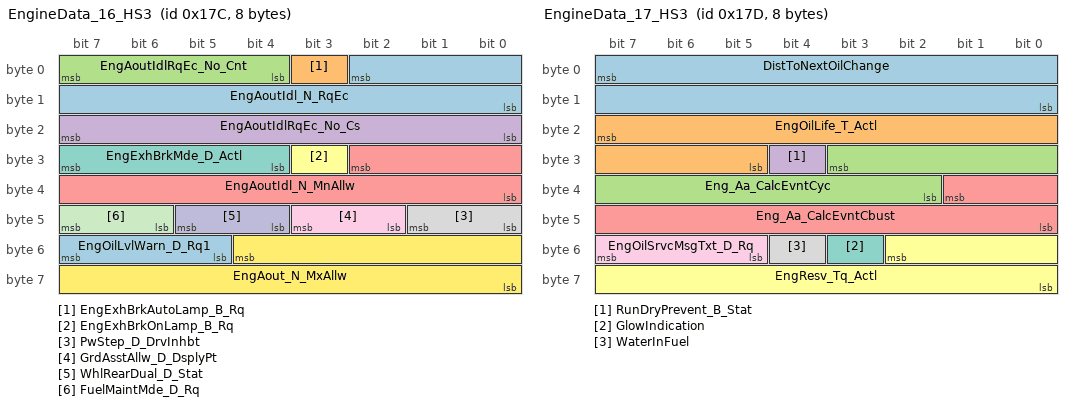
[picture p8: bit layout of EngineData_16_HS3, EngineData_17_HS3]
BO_ 380 EngineData_16_HS3: 8 GWM
 SG_ EngAoutIdl_N_RqEc : 2|11@0+ (2,0) [0|4094] "rpm"  IPC
 SG_ EngExhBrkAutoLamp_B_Rq : 3|1@0+ (1,0) [0|1] "SED"  APIM_CDC,APIM_CIM,IPC
 SG_ EngAoutIdlRqEc_No_Cnt : 7|4@0+ (1,0) [0|15] "Unitless"  GENERIC
 SG_ EngAoutIdlRqEc_No_Cs : 23|8@0+ (1,0) [0|255] "Unitless"  GENERIC
 SG_ EngAoutIdl_N_MnAllw : 26|11@0+ (2,0) [0|4094] "rpm"  IPC
 SG_ EngExhBrkOnLamp_B_Rq : 27|1@0+ (1,0) [0|1] "SED"  APIM_CDC,APIM_CIM,IPC
 SG_ EngExhBrkMde_D_Actl : 31|4@0+ (1,0) [0|15] "SED"  APIM_CDC,APIM_CIM,IPC
 SG_ PwStep_D_DrvInhbt : 41|2@0+ (1,0) [0|3] "SED" Vector__XXX
 SG_ GrdAsstAllw_D_DsplyPt : 43|2@0+ (1,0) [0|3] "SED"  APIM_CDC,APIM_CIM,IPC
 SG_ WhlRearDual_D_Stat : 45|2@0+ (1,0) [0|3] "SED"  GENERIC
 SG_ FuelMaintMde_D_Rq : 47|2@0+ (1,0) [0|3] "SED"  GENERIC
 SG_ EngAout_N_MxAllw : 52|13@0+ (2,0) [0|16382] "rpm"  IPC
 SG_ EngOilLvlWarn_D_Rq1 : 55|3@0+ (1,0) [0|7] "SED"  APIM_CDC,APIM_CIM,IPC

BO_ 381 EngineData_17_HS3: 8 GWM
 SG_ DistToNextOilChange : 7|16@0+ (1,0) [0|65535] "unitless"  APIM_CDC,APIM_CIM,IPC
 SG_ EngOilLife_T_Actl : 23|11@0+ (1,0) [0|2047] "day"  APIM_CDC,APIM_CIM,IPC
 SG_ Eng_Aa_CalcEvntCyc : 27|10@0+ (0.05,-25.6) [-25.6|25.55] "rpm/ms"  IPC
 SG_ RunDryPrevent_B_Stat : 28|1@0+ (1,0) [0|1] "SED"  APIM_CDC,APIM_CIM,APIM_CISM,IPC
 SG_ Eng_Aa_CalcEvntCbust : 33|10@0+ (0.05,-25.6) [-25.6|25.55] "rpm/ms"  IPC
 SG_ EngResv_Tq_Actl : 50|11@0+ (1,-500) [-500|1547] "Nm"  IPC
 SG_ GlowIndication : 51|1@0+ (1,0) [0|1] "SED"  APIM_CDC,APIM_CIM,IPC
 SG_ WaterInFuel : 52|1@0+ (1,0) [0|1] "SED"  APIM_CDC,APIM_CIM,IPC
 SG_ EngOilSrvcMsgTxt_D_Rq : 55|3@0+ (1,0) [0|7] "SED"  APIM_CDC,APIM_CIM,APIM_CISM,IPC

BO_ 382 EngineData_Gas_HS3: 8 GWM
 SG_ EngInnrClnt_Te_Actl : 7|7@0+ (1,50) [50|177] "degC"  APIM,APIM_CDC,APIM_CIM,IPC
 SG_ EngMnfldChrg_Te_Actl : 15|7@0+ (1,-20) [-20|107] "degC"  APIM,APIM_CDC,APIM_CIM,IPC
 SG_ DcacOut1_Pw2_Dsply : 23|13@0+ (1,0) [0|8191] "watts"  APIM,APIM_CDC,APIM_CIM,APIM_CISM
 SG_ EngIdlShutDown_D2_Type : 26|2@0+ (1,0) [0|3] "SED"  APIM,APIM_CDC,APIM_CIM,APIM_CISM,IPC
 SG_ DcacOut2_Pw2_Dsply : 39|13@0+ (1,0) [0|8191] "watts"  APIM,APIM_CDC,APIM_CIM,APIM_CISM
 SG_ DcacOut_E_Tot : 55|16@0+ (20,0) [0|1310700] "watt*hour"  APIM,APIM_CDC,APIM_CIM,APIM_CISM

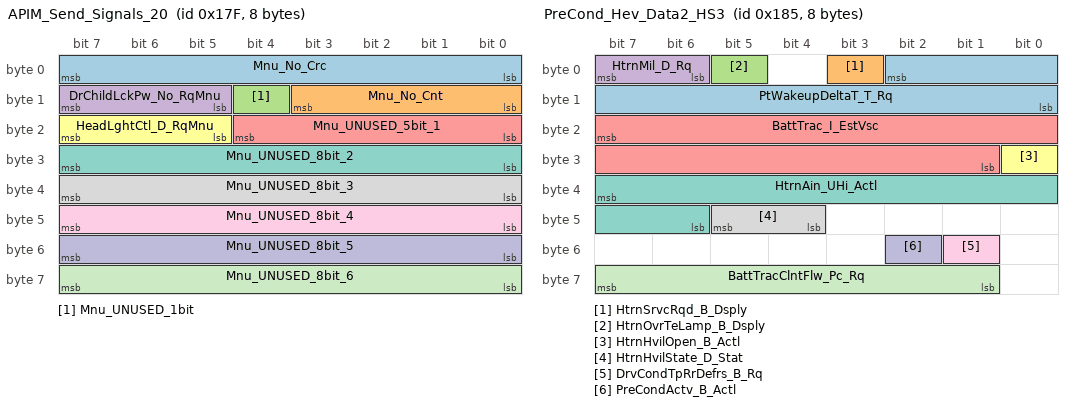
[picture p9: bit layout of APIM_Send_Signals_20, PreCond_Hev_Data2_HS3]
BO_ 383 APIM_Send_Signals_20: 8 APIM_CIM
 SG_ Mnu_No_Crc : 7|8@0+ (1,0) [0|255] "unitless"  GWM
 SG_ Mnu_No_Cnt : 11|4@0+ (1,0) [0|15] "unitless"  GWM
 SG_ Mnu_UNUSED_1bit : 12|1@0+ (1,0) [1|1] "unitless"  GWM
 SG_ DrChildLckPw_No_RqMnu : 15|3@0+ (1,0) [0|7] "unitless"  GWM
 SG_ Mnu_UNUSED_5bit_1 : 20|5@0+ (1,0) [31|31] "unitless"  GWM
 SG_ HeadLghtCtl_D_RqMnu : 23|3@0+ (1,0) [0|7] "SED"  GWM
 SG_ Mnu_UNUSED_8bit_2 : 31|8@0+ (1,0) [255|255] "unitless"  GWM
 SG_ Mnu_UNUSED_8bit_3 : 39|8@0+ (1,0) [255|255] "unitless"  GWM
 SG_ Mnu_UNUSED_8bit_4 : 47|8@0+ (1,0) [255|255] "unitless"  GWM
 SG_ Mnu_UNUSED_8bit_5 : 55|8@0+ (1,0) [255|255] "unitless"  GWM
 SG_ Mnu_UNUSED_8bit_6 : 63|8@0+ (1,0) [255|255] "unitless"  GWM

BO_ 385 ChargeSettings_3_HS3: 8 GWM
 SG_ ChrgGlblAc_I_Mx : 7|8@0+ (1,0) [0|255] "ampere"  APIM,IPC
 SG_ ChrgGlblDc_Pw_Mx : 15|7@0+ (5,0) [0|635] "kilowatt"  APIM,IPC
 SG_ ChrgGlblSocAc_Pc_Mx : 23|7@0+ (1,0) [0|127] "percent"  APIM,IPC
 SG_ ChrgGlblSocDc_Pc_Mx : 31|7@0+ (1,0) [0|127] "percent"  APIM,IPC
 SG_ ChrgrInMx_Pw_Rq : 39|13@0+ (50,0) [0|409550] "watt" Vector__XXX

BO_ 386 HEV_Powertrain_Data12_HS3: 8 GWM
 SG_ Chrg_I_Dsply : 7|9@0+ (1,0) [0|511] "ampere"  APIM,APIM_CDC,APIM_CIM,IPC
 SG_ Chrg_Pw_Dsply : 14|13@0+ (50,0) [0|409550] "watts"  APIM,APIM_CDC,APIM_CIM,IPC
 SG_ Chrg_U_Dsply : 17|10@0+ (1,0) [0|1023] "volt"  APIM,APIM_CDC,APIM_CIM,IPC
 SG_ Chrg_V_Dsply : 39|18@0+ (0.01,0) [0|2621.43] "kilometers/hour"  APIM,APIM_CDC,IPC

BO_ 387 ChargeSettings_2_HS3: 8 GWM
 SG_ ChrgGlblRcmd_I_Dsply : 7|8@0+ (1,0) [0|255] "ampere"  APIM
 SG_ AcMx_I_Dsply : 15|8@0+ (1,0) [0|255] "ampere"  APIM
 SG_ ChrgGlblAcRcmd_Pc_Dspl : 23|7@0+ (1,0) [0|127] "percent"  APIM,IPC
 SG_ ChrgGlblDcRcmd_Pc_Dspl : 31|7@0+ (1,0) [0|127] "percent"  APIM
 SG_ ChrgGlblRcmd_Pw_Dsply : 39|7@0+ (5,0) [0|635] "kilowatt"  APIM
 SG_ DcMx_Pw_Dsply : 47|7@0+ (5,0) [0|635] "kilowatt"  APIM
 SG_ ChrgGlblId_No_Actl : 55|3@0+ (1,0) [0|7] "unitless"  APIM

BO_ 389 PreCond_Hev_Data2_HS3: 8 GWM
 SG_ PtWakeupDeltaT_T_Rq : 2|11@0+ (1,0) [0|2047] "minute" Vector__XXX
 SG_ HtrnSrvcRqd_B_Dsply : 3|1@0+ (1,0) [0|1] "SED"  APIM_CDC,APIM_CIM,APIM_CISM,IPC
 SG_ HtrnOvrTeLamp_B_Dsply : 5|1@0+ (1,0) [0|1] "SED"  APIM_CDC,APIM_CIM,APIM_CISM,IPC
 SG_ HtrnMil_D_Rq : 7|2@0+ (1,0) [0|3] "SED" Vector__XXX
 SG_ BattTrac_I_EstVsc : 23|15@0+ (0.05,-750) [-750|888.35] "Amps" Vector__XXX
 SG_ HtrnHvilOpen_B_Actl : 24|1@0+ (1,0) [0|1] "SED" Vector__XXX
 SG_ HtrnAin_UHi_Actl : 39|10@0+ (0.5,0) [0|511.5] "volt" Vector__XXX
 SG_ HtrnHvilState_D_Stat : 45|2@0+ (1,0) [0|3] "SED" Vector__XXX
 SG_ DrvCondTpRrDefrs_B_Rq : 49|1@0+ (1,0) [0|1] "SED" Vector__XXX
 SG_ PreCondActv_B_Actl : 50|1@0+ (1,0) [0|1] "SED" Vector__XXX
 SG_ BattTracClntFlw_Pc_Rq : 63|7@0+ (1,0) [0|127] "percent" Vector__XXX

BO_ 391 ACU_Request_Signals_3: 8 APIM_CIM
 SG_ ACU_CtrlChimeChan_Rq : 7|2@0+ (1,0) [0|3] "SED"  DSP

BO_ 394 ACCDATA_3_HS3: 8 GWM
 SG_ AccStopMde_B_Dsply : 0|1@0+ (1,0) [0|1] "SED"  APIM_CDC,APIM_CIM,HUD_ADV,IPC
 SG_ HaDsply_No_Cnt : 4|4@0+ (1,0) [0|15] "unitless"  APIM_CDC,APIM_CIM,IPC
 SG_ FcwMsgTxt_D_Rq : 7|3@0+ (1,0) [0|7] "SED"  APIM_CDC,APIM_CIM,IPC
 SG_ FcwAudioWarn_B_Rq : 8|1@0+ (1,0) [0|1] "SED"  APIM_CDC,APIM_CIM,IPC
 SG_ CmbbPostEvntRl_B_Dsply : 9|1@0+ (1,0) [0|1] "SED"  IPC
 SG_ FcwDeny_B_Dsply : 10|1@0+ (1,0) [0|1] "SED"  APIM_CDC,APIM_CIM,IPC
 SG_ CadsAlignIncplt_B_Actl : 11|1@0+ (1,0) [0|1] "SED"  APIM_CDC,APIM_CIM,IPC
 SG_ PcaVisblWarnRr_B_Rq : 12|1@0+ (1,0) [0|1] "SED"  IPC
 SG_ FcwMemStat_B_Actl : 13|1@0+ (1,0) [0|1] "SED"  APIM_CDC,APIM_CIM,IPC
 SG_ PcaVisblWarnRl_B_Rq : 14|1@0+ (1,0) [0|1] "SED"  IPC
 SG_ CmbbPostEvnt_B_Dsply : 15|1@0+ (1,0) [0|1] "SED"  APIM_CDC,APIM_CIM,IPC
 SG_ AccFllwMde_B_Dsply : 17|1@0+ (1,0) [0|1] "SED"  APIM_CDC,APIM_CIM,HUD_ADV,IPC
 SG_ FcwMemSens_D_Actl : 20|2@0+ (1,0) [0|3] "SED"  APIM_CDC,APIM_CIM,IPC
 SG_ PcaAudioWarnRear_B_Rq : 21|1@0+ (1,0) [0|1] "SED"  IPC
 SG_ CadsRadrBlck_B_Actl : 22|1@0+ (1,0) [0|1] "SED"  APIM_CDC,APIM_CIM,IPC
 SG_ CmbbPostEvntRr_B_Dsply : 23|1@0+ (1,0) [0|1] "SED"  IPC
 SG_ AccTrgDist2_D_Dsply : 27|4@0+ (1,0) [0|15] "SED"  APIM_CDC,APIM_CIM,HUD_ADV,IPC
 SG_ AccMsgTxt_D2_Rq : 31|4@0+ (1,0) [0|15] "SED"  APIM_CDC,APIM_CIM,HUD_ADV,IPC
 SG_ AccTGap_D_Dsply : 34|3@0+ (1,0) [0|7] "SED"  APIM_CDC,APIM_CIM,HUD_ADV,IPC
 SG_ AccTGap_B_Dsply : 35|1@0+ (1,0) [0|1] "SED"  APIM_CDC,APIM_CIM,HUD_ADV,IPC
 SG_ AccMemEnbl_B_RqDrv : 36|1@0+ (1,0) [0|1] "SED"  APIM_CDC,APIM_CIM,HUD_ADV,IPC
 SG_ AccWarn_D_Dsply : 39|2@0+ (1,0) [0|3] "SED"  APIM_CDC,APIM_CIM,HUD_ADV,IPC
 SG_ AccStopStat_D_Dsply : 41|2@0+ (1,0) [0|3] "SED"  APIM_CDC,APIM_CIM,HUD_ADV,IPC
 SG_ Tja_D_Stat : 44|3@0+ (1,0) [0|7] "SED"  APIM,APIM_CDC,APIM_CIM,HUD_ADV,IPC
 SG_ IaccLamp_D_Rq : 46|2@0+ (1,0) [0|3] "SED"  APIM,APIM_CDC,APIM_CIM,APIM_CISM,HUD_ADV,IPC
 SG_ FcwVisblWarn_B_Rq : 47|1@0+ (1,0) [0|1] "SED"  APIM_CDC,APIM_CIM,HUD_ADV,IPC
 SG_ TjaWarn_D_Rq : 50|3@0+ (1,0) [0|7] "SED"  APIM_CDC,APIM_CIM,HUD_ADV,IPC
 SG_ TjaMsgTxt_D_Dsply : 53|3@0+ (1,0) [0|7] "SED"  APIM_CDC,APIM_CIM,HUD_ADV,IPC
 SG_ AccStopRes_B_Dsply : 54|1@0+ (1,0) [0|1] "SED"  APIM_CDC,APIM_CIM,HUD_ADV,IPC
 SG_ HaDsply_No_Cs : 63|8@0+ (1,0) [0|255] "unitless"  APIM_CDC,APIM_CIM,IPC

BO_ 395 HeadUpDisplayReq: 8 APIM_CDC
 SG_ HudLed8On_B_Rq : 0|1@0+ (1,0) [0|1] "SED"  GWM
 SG_ HudLed7On_B_Rq : 1|1@0+ (1,0) [0|1] "SED"  GWM
 SG_ HudLed6On_B_Rq : 2|1@0+ (1,0) [0|1] "SED"  GWM
 SG_ HudLed5On_B_Rq : 3|1@0+ (1,0) [0|1] "SED"  GWM
 SG_ HudLed4On_B_Rq : 4|1@0+ (1,0) [0|1] "SED"  GWM
 SG_ HudLed3On_B_Rq : 5|1@0+ (1,0) [0|1] "SED"  GWM
 SG_ HudLed2On_B_Rq : 6|1@0+ (1,0) [0|1] "SED"  GWM
 SG_ HudLed1On_B_Rq : 7|1@0+ (1,0) [0|1] "SED"  GWM
 SG_ HudLed16On_B_Rq : 8|1@0+ (1,0) [0|1] "SED"  GWM
 SG_ HudLed15On_B_Rq : 9|1@0+ (1,0) [0|1] "SED"  GWM
 SG_ HudLed14On_B_Rq : 10|1@0+ (1,0) [0|1] "SED"  GWM
 SG_ HudLed13On_B_Rq : 11|1@0+ (1,0) [0|1] "SED"  GWM
 SG_ HudLed12On_B_Rq : 12|1@0+ (1,0) [0|1] "SED"  GWM
 SG_ HudLed11On_B_Rq : 13|1@0+ (1,0) [0|1] "SED"  GWM
 SG_ HudLed10On_B_Rq : 14|1@0+ (1,0) [0|1] "SED"  GWM
 SG_ HudLed9On_B_Rq : 15|1@0+ (1,0) [0|1] "SED"  GWM
 SG_ HudLedIntns_Pc_Rq : 22|7@0+ (1,0) [0|127] "percent"  GWM
 SG_ HudLed17On_B_Rq : 23|1@0+ (1,0) [0|1] "SED"  GWM
 SG_ HudShifPoint_N_Rq : 29|6@0+ (100,2000) [2000|8300] "rpm"  GWM,HUD_ADV
 SG_ HudLedMde_D_Rq : 31|2@0+ (1,0) [0|3] "SED"  GWM
 SG_ SelDrvMdeCnfm_D_Stat : 35|2@0+ (1,0) [0|3] "SED"  GWM
 SG_ HudMde_D_Rq : 38|3@0+ (1,0) [0|7] "SED"  GWM,HUD_ADV
 SG_ HudLed18On_B_Rq : 39|1@0+ (1,0) [0|1] "SED"  GWM

BO_ 400 HEC_Request_Signals: 8 APIM_CDC
 SG_ Mc_PerTUPresetArea_Rq : 7|4@0+ (1,0) [0|15] "SED"  ACM,APIM,APIM_CISM,GWM
 SG_ Mc_PerTUStartIndex2_Rq : 15|8@0+ (1,0) [0|255] "unitless"  ACM,APIM,APIM_CISM,GWM
 SG_ Mc_PerTUNbrOfPresets_Rq : 31|5@0+ (1,0) [0|31] "SED"  ACM,APIM,APIM_CISM,GWM
 SG_ Mc_SetCurrntStatFreq_Rq : 42|11@0+ (1,0) [0|1557] "unitless"  ACM,APIM_CISM,GWM
 SG_ Mc_SetCurrStatMCCh_Rq : 45|3@0+ (1,0) [0|7] "SED"  ACM,APIM_CISM,GWM
 SG_ Mc_SetCurrentStatOp_Rq : 47|2@0+ (1,0) [0|3] "SED"  ACM,APIM_CISM,GWM

BO_ 401 MFD_Request_Signals4: 8 APIM_CDC
 SG_ Disp_VehUntTripCoUsrSel : 3|2@0+ (1,0) [0|3] "SED"  GWM,IPC
 SG_ Disp_VehUnitTempUsrSel : 5|2@0+ (1,0) [0|3] "SED"  GWM,IPC
 SG_ Bezel_Beeps_Rq : 7|2@0+ (1,0) [0|3] "SED"  FCIMB,GWM
 SG_ Disp_LangSel_Rq : 15|5@0+ (1,0) [0|31] "SED"  GWM,IPC
 SG_ Disp_LangSel2_Rq : 23|7@0+ (1,0) [0|127] "SED"  IPC

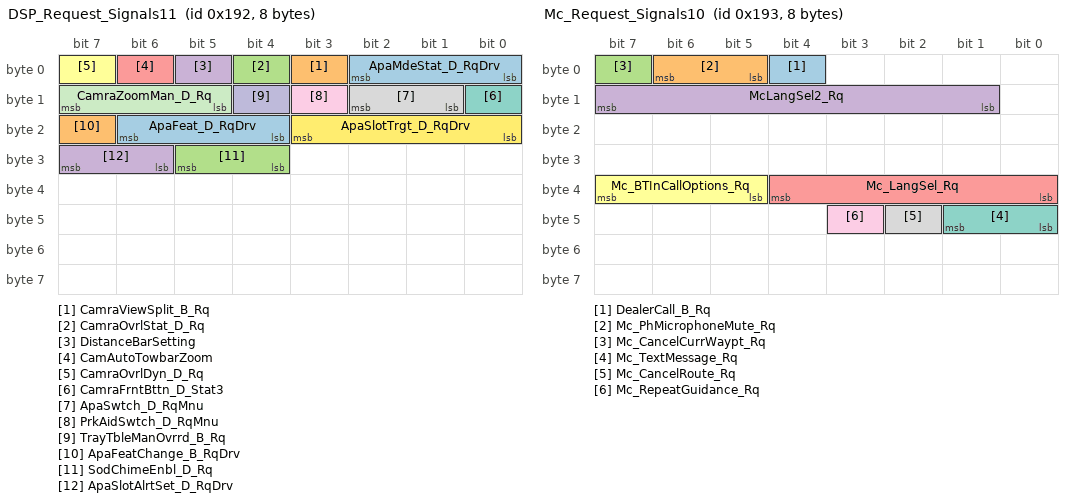
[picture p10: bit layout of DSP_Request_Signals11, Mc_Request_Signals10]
BO_ 402 DSP_Request_Signals11: 8 APIM_CDC
 SG_ ApaMdeStat_D_RqDrv : 2|3@0+ (1,0) [0|7] "SED"  GWM
 SG_ CamraViewSplit_B_Rq : 3|1@0+ (1,0) [0|1] "SED"  GWM
 SG_ CamraOvrlStat_D_Rq : 4|1@0+ (1,0) [0|1] "SED"  GWM,IPC
 SG_ DistanceBarSetting : 5|1@0+ (1,0) [0|1] "SED"  GWM
 SG_ CamAutoTowbarZoom : 6|1@0+ (1,0) [0|1] "SED"  GWM,IPC
 SG_ CamraOvrlDyn_D_Rq : 7|1@0+ (1,0) [0|1] "SED"  GWM,IPC
 SG_ CamraFrntBttn_D_Stat3 : 8|1@0+ (1,0) [0|1] "SED"  GWM
 SG_ ApaSwtch_D_RqMnu : 10|2@0+ (1,0) [0|3] "SED"  GWM
 SG_ PrkAidSwtch_D_RqMnu : 11|1@0+ (1,0) [0|1] "SED"  GWM
 SG_ TrayTbleManOvrrd_B_Rq : 12|1@0+ (1,0) [0|1] "SED"  GWM
 SG_ CamraZoomMan_D_Rq : 15|3@0+ (1,0) [0|7] "SED"  GWM
 SG_ ApaSlotTrgt_D_RqDrv : 19|4@0+ (1,0) [0|15] "SED"  GWM
 SG_ ApaFeat_D_RqDrv : 22|3@0+ (1,0) [0|7] "SED"  GWM
 SG_ ApaFeatChange_B_RqDrv : 23|1@0+ (1,0) [0|1] "SED"  GWM
 SG_ SodChimeEnbl_D_Rq : 29|2@0+ (1,0) [0|3] "SED"  GWM
 SG_ ApaSlotAlrtSet_D_RqDrv : 31|2@0+ (1,0) [0|3] "SED"  GWM

BO_ 403 Mc_Request_Signals10: 8 APIM_CDC
 SG_ DealerCall_B_Rq : 4|1@0+ (1,0) [0|1] "SED"  APIM,APIM_CISM,GWM
 SG_ Mc_PhMicrophoneMute_Rq : 6|2@0+ (1,0) [0|3] "SED"  APIM,APIM_CISM,GWM
 SG_ Mc_CancelCurrWaypt_Rq : 7|1@0+ (1,0) [0|1] "SED"  APIM,APIM_CISM,GWM
 SG_ McLangSel2_Rq : 15|7@0+ (1,0) [0|127] "SED"  APIM,APIM_CISM,GWM
 SG_ Mc_LangSel_Rq : 36|5@0+ (1,0) [0|31] "SED"  APIM,APIM_CISM,GWM
 SG_ Mc_BTInCallOptions_Rq : 39|3@0+ (1,0) [0|7] "SED"  APIM,APIM_CISM,GWM
 SG_ Mc_TextMessage_Rq : 41|2@0+ (1,0) [0|3] "SED"  APIM,APIM_CISM,GWM
 SG_ Mc_CancelRoute_Rq : 42|1@0+ (1,0) [0|1] "SED"  APIM,APIM_CISM,GWM
 SG_ Mc_RepeatGuidance_Rq : 43|1@0+ (1,0) [0|1] "SED"  APIM,APIM_CISM,GWM

BO_ 404 Dsp_Response_Signals: 8 APIM_CIM
 SG_ Dsp_LangUpdate_Rsp : 7|2@0+ (1,0) [0|3] "SED"  GWM,IPC

BO_ 405 LBClient1_Request_Signals: 8 APIM_CDC
 SG_ LBC1_ActiveListID : 7|16@0+ (1,0) [0|65535] "unitless"  ACM,APIM,APIM_CISM,GWM
 SG_ LBC1_ItemIndex : 23|16@0+ (1,0) [0|65535] "unitless"  ACM,APIM,APIM_CISM,GWM
 SG_ LBC1_NbrOfItems : 37|6@0+ (1,0) [0|63] "unitless"  ACM,APIM,APIM_CISM,GWM
 SG_ LBC1_Opcode : 39|2@0+ (1,0) [0|3] "SED"  ACM,APIM,APIM_CISM,GWM
 SG_ LBC1_SetListServ : 47|8@0+ (1,0) [0|255] "unitless"  ACM,APIM,APIM_CISM,GWM
 SG_ LBC1_StartItemInd : 55|16@0+ (1,0) [0|65535] "unitless"  ACM,APIM,APIM_CISM,GWM

BO_ 410 Mc_Send_Signals_3: 8 APIM_CDC
 SG_ DoNotDisturbOveride_St : 26|2@0+ (1,0) [0|3] "SED"  APIM,APIM_CISM,GWM
 SG_ MyKey_e911Override_St : 39|2@0+ (1,0) [0|3] "SED"  APIM,APIM_CISM,GWM

BO_ 412 LBClient2_Request_Signals: 8 APIM_CDC
 SG_ LBC2_ActiveListID : 7|16@0+ (1,0) [0|65535] "unitless"  ACM
 SG_ LBC2_ItemIndex : 23|16@0+ (1,0) [0|65535] "unitless"  ACM
 SG_ LBC2_NbrOfItems : 37|6@0+ (1,0) [0|63] "unitless"  ACM
 SG_ LBC2_Opcode : 39|2@0+ (1,0) [0|3] "SED"  ACM
 SG_ LBC2_SetListServ : 47|8@0+ (1,0) [0|255] "unitless"  ACM
 SG_ LBC2_StartItemInd : 55|16@0+ (1,0) [0|65535] "unitless"  ACM

BO_ 413 LBS1_Indication_Signals: 8 APIM_CDC
 SG_ LBS1_ListServer : 7|8@0+ (1,0) [0|255] "unitless"  IPC,RACM_RCIM
 SG_ LBS1_ListID : 15|16@0+ (1,0) [0|65535] "unitless"  IPC,RACM_RCIM
 SG_ LBS1_ParentID : 31|16@0+ (1,0) [0|65535] "unitless"  IPC,RACM_RCIM
 SG_ LBS1_EntryIndex : 47|16@0+ (1,0) [0|65535] "unitless"  IPC,RACM_RCIM
 SG_ LBS1_ListStatus : 57|2@0+ (1,0) [0|3] "SED"  IPC,RACM_RCIM

BO_ 414 LBS2_Indication_Signals: 8 APIM_CIM
 SG_ LBS2_ListServer : 7|8@0+ (1,0) [0|255] "unitless"  APIM,APIM_CDC,IPC,RACM_RCIM
 SG_ LBS2_ListID : 15|16@0+ (1,0) [0|65535] "unitless"  APIM,APIM_CDC,IPC,RACM_RCIM
 SG_ LBS2_ParentID : 31|16@0+ (1,0) [0|65535] "unitless"  APIM,APIM_CDC,IPC,RACM_RCIM
 SG_ LBS2_EntryIndex : 47|16@0+ (1,0) [0|65535] "unitless"  APIM,APIM_CDC,IPC,RACM_RCIM
 SG_ LBS2_ListStatus : 57|2@0+ (1,0) [0|3] "SED"  APIM,APIM_CDC,IPC,RACM_RCIM

BO_ 415 LBClient3_Request_Signals: 8 RACM_RCIM
 SG_ LBC3_ActiveListID : 7|16@0+ (1,0) [0|65535] "unitless"  ACM,APIM,APIM_CDC,APIM_CIM,APIM_CISM
 SG_ LBC3_ItemIndex : 23|16@0+ (1,0) [0|65535] "unitless"  ACM,APIM,APIM_CDC,APIM_CIM,APIM_CISM
 SG_ LBC3_NbrOfItems : 37|6@0+ (1,0) [0|63] "unitless"  ACM,APIM,APIM_CDC,APIM_CIM,APIM_CISM
 SG_ LBC3_Opcode : 39|2@0+ (1,0) [0|3] "SED"  ACM,APIM,APIM_CDC,APIM_CIM,APIM_CISM
 SG_ LBC3_SetListServ : 47|8@0+ (1,0) [0|255] "unitless"  ACM,APIM,APIM_CDC,APIM_CIM,APIM_CISM
 SG_ LBC3_StartItemInd : 55|16@0+ (1,0) [0|65535] "unitless"  ACM,APIM,APIM_CDC,APIM_CIM,APIM_CISM

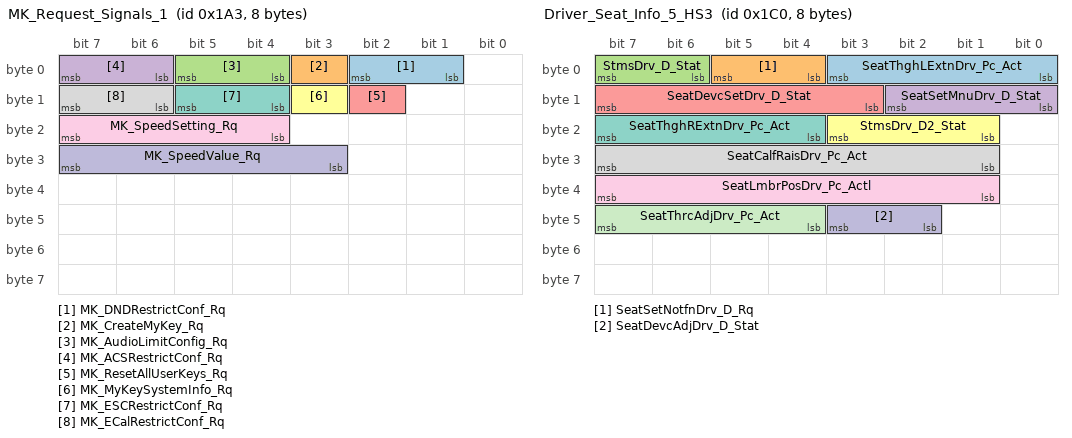
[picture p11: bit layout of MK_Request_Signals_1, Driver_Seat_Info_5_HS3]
BO_ 419 MK_Request_Signals_1: 8 APIM
 SG_ MK_DNDRestrictConf_Rq : 2|2@0+ (1,0) [0|3] "SED"  IPC
 SG_ MK_CreateMyKey_Rq : 3|1@0+ (1,0) [0|1] "SED"  IPC
 SG_ MK_AudioLimitConfig_Rq : 5|2@0+ (1,0) [0|3] "SED"  IPC
 SG_ MK_ACSRestrictConf_Rq : 7|2@0+ (1,0) [0|3] "SED"  IPC
 SG_ MK_ResetAllUserKeys_Rq : 10|1@0+ (1,0) [0|1] "SED"  IPC
 SG_ MK_MyKeySystemInfo_Rq : 11|1@0+ (1,0) [0|1] "SED"  IPC
 SG_ MK_ESCRestrictConf_Rq : 13|2@0+ (1,0) [0|3] "SED"  IPC
 SG_ MK_ECalRestrictConf_Rq : 15|2@0+ (1,0) [0|3] "SED"  IPC
 SG_ MK_SpeedSetting_Rq : 23|4@0+ (1,0) [0|15] "SED"  IPC
 SG_ MK_SpeedValue_Rq : 31|5@0+ (1,0) [0|31] "SED"  IPC

BO_ 422 MK_Response_Signals_1: 8 IPC
 SG_ MK_UserMyKeyCount_Rsp : 4|4@0+ (1,0) [0|15] "SED"  APIM,APIM_CISM,GWM
 SG_ MK_CreateMyKey_Rsp : 7|3@0+ (1,0) [0|7] "SED"  APIM,APIM_CISM,GWM
 SG_ MK_AdminMyKeyCount_Rsp : 15|4@0+ (1,0) [0|15] "SED"  APIM,APIM_CISM,GWM
 SG_ MK_MyKeyDrivenKm_Rsp : 43|20@0+ (1,0) [0|1048575] "km"  APIM,APIM_CISM,GWM

BO_ 436 Av_RDAPM_Data3_1: 8 MRCMB_RDAPM_HS3
 SG_ AprReas_No_Actl : 7|64@0+ (1,0) [0|1.84467440737096E+019] "unitless"  GWM

BO_ 437 Av_RDAPM_Data4_1: 8 MRCMB_RDAPM_HS3
 SG_ AprTvfTripId2_No_Actl : 7|64@0+ (1,0) [0|1.84467440737096E+019] "unitless"  GWM

BO_ 438 Av_RDAPMtoECG_1: 8 MRCMB_RDAPM_HS3
 SG_ AprPsswrd1_No_Rq : 7|64@0+ (1,0) [0|1.84467440737096E+019] "unitless"  GWM

BO_ 439 Av_RDAPMtoECG_2: 8 MRCMB_RDAPM_HS3
 SG_ AprPsswrd2_No_Rq : 7|64@0+ (1,0) [0|1.84467440737096E+019] "unitless"  GWM

BO_ 440 Av_RDAPMtoECG_3: 8 MRCMB_RDAPM_HS3
 SG_ AprPsswrd3_No_Rq : 7|64@0+ (1,0) [0|1.84467440737096E+019] "unitless"  GWM

BO_ 441 Av_RDAPMtoECG_4: 8 MRCMB_RDAPM_HS3
 SG_ AprPsswrd4_No_Rq : 7|64@0+ (1,0) [0|1.84467440737096E+019] "unitless"  GWM

BO_ 448 Driver_Seat_Info_5_HS3: 8 GWM
 SG_ SeatThghLExtnDrv_Pc_Act : 3|4@0+ (10,0) [0|150] "percent"  APIM,APIM_CDC,APIM_CIM
 SG_ SeatSetNotfnDrv_D_Rq : 5|2@0+ (1,0) [0|3] "SED"  APIM_CDC,APIM_CIM
 SG_ StmsDrv_D_Stat : 7|2@0+ (1,0) [0|3] "SED"  APIM,APIM_CDC,APIM_CIM
 SG_ SeatSetMnuDrv_D_Stat : 10|3@0+ (1,0) [0|7] "SED"  APIM_CDC,APIM_CIM
 SG_ SeatDevcSetDrv_D_Stat : 15|5@0+ (1,0) [0|31] "SED"  APIM_CDC,APIM_CIM
 SG_ StmsDrv_D2_Stat : 19|3@0+ (1,0) [0|7] "SED"  APIM_CDC,APIM_CIM
 SG_ SeatThghRExtnDrv_Pc_Act : 23|4@0+ (10,0) [0|150] "percent"  APIM,APIM_CDC,APIM_CIM
 SG_ SeatCalfRaisDrv_Pc_Act : 31|7@0+ (1,0) [0|127] "percent"  APIM,APIM_CDC,APIM_CIM
 SG_ SeatLmbrPosDrv_Pc_Actl : 39|7@0+ (1,0) [0|127] "percent"  APIM,APIM_CDC,APIM_CIM
 SG_ SeatDevcAdjDrv_D_Stat : 43|2@0+ (1,0) [0|3] "SED"  APIM_CDC,APIM_CIM
 SG_ SeatThrcAdjDrv_Pc_Act : 47|4@0+ (10,0) [0|150] "percent"  APIM,APIM_CDC,APIM_CIM

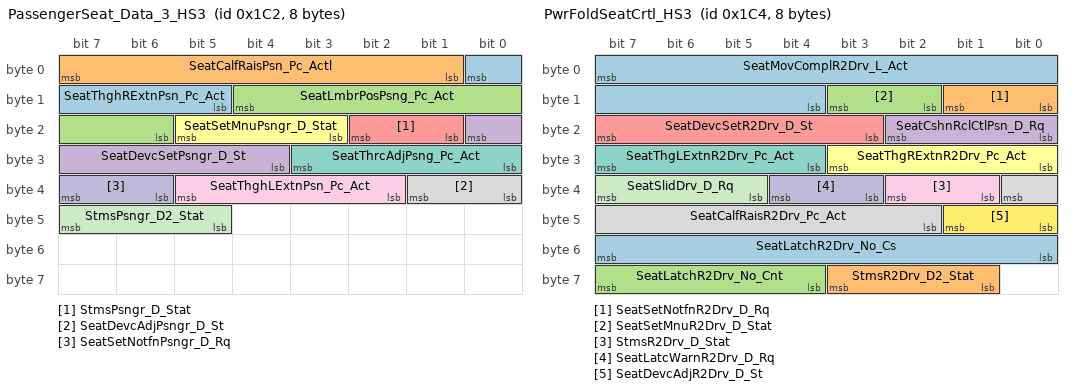
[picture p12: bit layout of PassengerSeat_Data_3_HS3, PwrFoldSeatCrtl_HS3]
BO_ 450 PassengerSeat_Data_3_HS3: 8 GWM
 SG_ SeatThghRExtnPsn_Pc_Act : 0|4@0+ (10,0) [0|150] "%"  APIM,APIM_CDC,APIM_CIM
 SG_ SeatCalfRaisPsn_Pc_Actl : 7|7@0+ (1,0) [0|127] "%"  APIM,APIM_CDC,APIM_CIM
 SG_ SeatLmbrPosPsng_Pc_Act : 12|7@0+ (1,0) [0|127] "%"  APIM,APIM_CDC,APIM_CIM
 SG_ SeatDevcSetPsngr_D_St : 16|5@0+ (1,0) [0|31] "Unitless"  APIM_CDC,APIM_CIM
 SG_ StmsPsngr_D_Stat : 18|2@0+ (1,0) [0|3] "Unitless"  APIM,APIM_CDC,APIM_CIM
 SG_ SeatSetMnuPsngr_D_Stat : 21|3@0+ (1,0) [0|7] "Unitless"  APIM_CDC,APIM_CIM
 SG_ SeatThrcAdjPsng_Pc_Act : 27|4@0+ (10,0) [0|150] "%"  APIM,APIM_CDC,APIM_CIM
 SG_ SeatDevcAdjPsngr_D_St : 33|2@0+ (1,0) [0|3] "SED"  APIM_CDC,APIM_CIM
 SG_ SeatThghLExtnPsn_Pc_Act : 37|4@0+ (10,0) [0|150] "%"  APIM,APIM_CDC,APIM_CIM
 SG_ SeatSetNotfnPsngr_D_Rq : 39|2@0+ (1,0) [0|3] "Unitless"  APIM_CDC,APIM_CIM
 SG_ StmsPsngr_D2_Stat : 47|3@0+ (1,0) [0|7] "SED"  APIM_CDC,APIM_CIM

BO_ 452 PwrFoldSeatCrtl_HS3: 8 GWM
 SG_ SeatMovComplR2Drv_L_Act : 7|12@0+ (1,0) [0|4095] "millimeter" Vector__XXX
 SG_ SeatSetNotfnR2Drv_D_Rq : 9|2@0+ (1,0) [0|3] "SED"  RACM_RCIM
 SG_ SeatSetMnuR2Drv_D_Stat : 11|2@0+ (1,0) [0|3] "SED"  RACM_RCIM
 SG_ SeatCshnRclCtlPsn_D_Rq : 18|3@0+ (1,0) [0|7] "SED"  GWM
 SG_ SeatDevcSetR2Drv_D_St : 23|5@0+ (1,0) [0|31] "SED"  RACM_RCIM
 SG_ SeatThgRExtnR2Drv_Pc_Act : 27|4@0+ (10,0) [0|140] "percent"  RACM_RCIM
 SG_ SeatThgLExtnR2Drv_Pc_Act : 31|4@0+ (10,0) [0|140] "percent"  RACM_RCIM
 SG_ SeatCalfRaisR2Drv_Pc_Act : 32|7@0+ (1,0) [0|125] "percent"  RACM_RCIM
 SG_ StmsR2Drv_D_Stat : 34|2@0+ (1,0) [0|7] "SED"  RACM_RCIM
 SG_ SeatLatcWarnR2Drv_D_Rq : 36|2@0+ (1,0) [0|3] "SED"  APIM_CDC,APIM_CIM,IPC
 SG_ SeatSlidDrv_D_Rq : 39|3@0+ (1,0) [0|7] "SED"  APIM_CDC,APIM_CIM,GWM
 SG_ SeatDevcAdjR2Drv_D_St : 41|2@0+ (1,0) [0|3] "SED"  RACM_RCIM
 SG_ SeatLatchR2Drv_No_Cs : 55|8@0+ (1,0) [0|255] "unitless"  APIM_CDC,APIM_CIM,IPC
 SG_ StmsR2Drv_D2_Stat : 59|3@0+ (1,0) [0|7] "SED"  RACM_RCIM
 SG_ SeatLatchR2Drv_No_Cnt : 63|4@0+ (1,0) [0|15] "unitless"  APIM_CDC,APIM_CIM,IPC

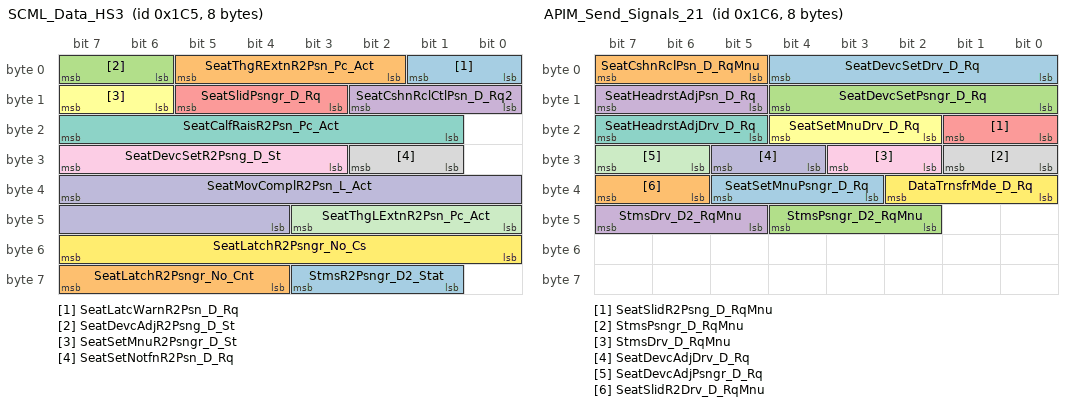
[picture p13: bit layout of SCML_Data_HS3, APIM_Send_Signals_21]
BO_ 453 SCML_Data_HS3: 8 GWM
 SG_ SeatLatcWarnR2Psn_D_Rq : 1|2@0+ (1,0) [0|3] "SED"  APIM_CDC,APIM_CIM,IPC
 SG_ SeatThgRExtnR2Psn_Pc_Act : 5|4@0+ (10,0) [0|150] "percent"  RACM_RCIM
 SG_ SeatDevcAdjR2Psng_D_St : 7|2@0+ (1,0) [0|3] "SED"  RACM_RCIM
 SG_ SeatCshnRclCtlPsn_D_Rq2 : 10|3@0+ (1,0) [0|7] "SED" Vector__XXX
 SG_ SeatSlidPsngr_D_Rq : 13|3@0+ (1,0) [0|7] "SED"  APIM_CDC,APIM_CIM
 SG_ SeatSetMnuR2Psngr_D_St : 15|2@0+ (1,0) [0|3] "SED"  RACM_RCIM
 SG_ SeatCalfRaisR2Psn_Pc_Act : 23|7@0+ (1,0) [0|127] "percent"  RACM_RCIM
 SG_ SeatSetNotfnR2Psn_D_Rq : 26|2@0+ (1,0) [0|3] "SED"  RACM_RCIM
 SG_ SeatDevcSetR2Psng_D_St : 31|5@0+ (1,0) [0|31] "SED"  RACM_RCIM
 SG_ SeatMovComplR2Psn_L_Act : 39|12@0+ (1,0) [0|4095] "millimeter" Vector__XXX
 SG_ SeatThgLExtnR2Psn_Pc_Act : 43|4@0+ (10,0) [0|150] "percent"  RACM_RCIM
 SG_ SeatLatchR2Psngr_No_Cs : 55|8@0+ (1,0) [0|255] "unitless"  APIM_CDC,APIM_CIM,IPC
 SG_ StmsR2Psngr_D2_Stat : 59|3@0+ (1,0) [0|7] "SED"  RACM_RCIM
 SG_ SeatLatchR2Psngr_No_Cnt : 63|4@0+ (1,0) [0|15] "unitless"  APIM_CDC,APIM_CIM,IPC

BO_ 454 APIM_Send_Signals_21: 8 APIM_CDC
 SG_ SeatDevcSetDrv_D_Rq : 4|5@0+ (1,0) [0|31] "SED"  GWM
 SG_ SeatCshnRclPsn_D_RqMnu : 7|3@0+ (1,0) [0|7] "SED"  GWM
 SG_ SeatDevcSetPsngr_D_Rq : 12|5@0+ (1,0) [0|31] "SED"  GWM
 SG_ SeatHeadrstAdjPsn_D_Rq : 15|3@0+ (1,0) [0|7] "SED"  GWM
 SG_ SeatSlidR2Psng_D_RqMnu : 17|2@0+ (1,0) [0|3] "SED"  GWM
 SG_ SeatSetMnuDrv_D_Rq : 20|3@0+ (1,0) [0|7] "SED"  GWM
 SG_ SeatHeadrstAdjDrv_D_Rq : 23|3@0+ (1,0) [0|7] "SED"  GWM
 SG_ StmsPsngr_D_RqMnu : 25|2@0+ (1,0) [0|3] "SED"  GWM
 SG_ StmsDrv_D_RqMnu : 27|2@0+ (1,0) [0|3] "SED"  GWM
 SG_ SeatDevcAdjDrv_D_Rq : 29|2@0+ (1,0) [0|3] "SED"  GWM
 SG_ SeatDevcAdjPsngr_D_Rq : 31|2@0+ (1,0) [0|3] "SED"  GWM
 SG_ DataTrnsfrMde_D_Rq : 34|3@0+ (1,0) [0|7] "SED"  GWM
 SG_ SeatSetMnuPsngr_D_Rq : 37|3@0+ (1,0) [0|7] "SED"  GWM
 SG_ SeatSlidR2Drv_D_RqMnu : 39|2@0+ (1,0) [0|3] "SED"  GWM
 SG_ StmsPsngr_D2_RqMnu : 44|3@0+ (1,0) [0|7] "SED"  GWM
 SG_ StmsDrv_D2_RqMnu : 47|3@0+ (1,0) [0|7] "SED"  GWM

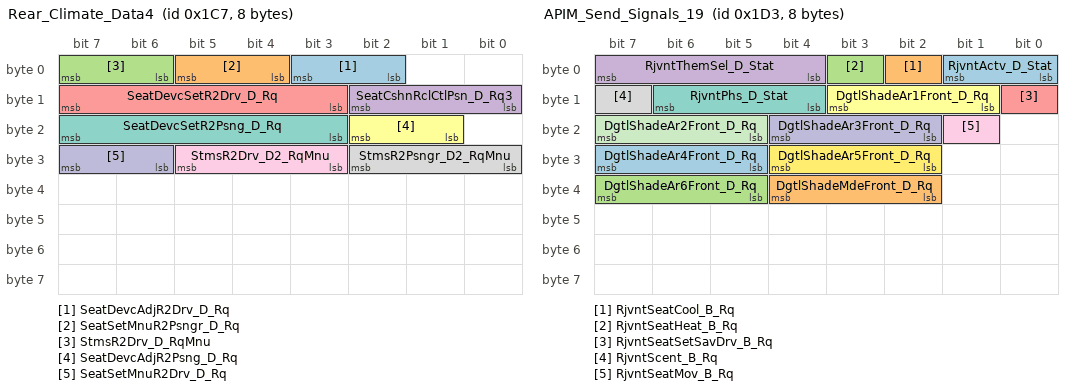
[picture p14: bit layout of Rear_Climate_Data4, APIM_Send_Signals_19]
BO_ 455 Rear_Climate_Data4: 8 RACM_RCIM
 SG_ SeatDevcAdjR2Drv_D_Rq : 3|2@0+ (1,0) [0|3] "SED"  GWM
 SG_ SeatSetMnuR2Psngr_D_Rq : 5|2@0+ (1,0) [0|3] "SED"  GWM
 SG_ StmsR2Drv_D_RqMnu : 7|2@0+ (1,0) [0|3] "SED"  GWM
 SG_ SeatCshnRclCtlPsn_D_Rq3 : 10|3@0+ (1,0) [0|7] "SED"  GWM
 SG_ SeatDevcSetR2Drv_D_Rq : 15|5@0+ (1,0) [0|31] "SED"  GWM
 SG_ SeatDevcAdjR2Psng_D_Rq : 18|2@0+ (1,0) [0|3] "SED"  GWM
 SG_ SeatDevcSetR2Psng_D_Rq : 23|5@0+ (1,0) [0|31] "SED"  GWM
 SG_ StmsR2Psngr_D2_RqMnu : 26|3@0+ (1,0) [0|7] "SED"  GWM
 SG_ StmsR2Drv_D2_RqMnu : 29|3@0+ (1,0) [0|7] "SED"  GWM
 SG_ SeatSetMnuR2Drv_D_Rq : 31|2@0+ (1,0) [0|3] "SED"  GWM

BO_ 462 Av_RDAPMtoECG: 8 MRCMB_RDAPM_HS3
 SG_ AprIndx_No_Rq : 5|6@0+ (1,0) [0|63] "unitless"  GWM
 SG_ AprIdUnlck_B_Stat : 6|1@0+ (1,0) [0|1] "SED"  GWM
 SG_ AprAuthntctn_B_Rq : 7|1@0+ (1,0) [0|1] "SED"  GWM
 SG_ AprPsswrdBackup_B_Rq : 14|4@0+ (1,0) [0|15] "SED"  GWM
 SG_ AprInfo_B_Rq : 15|1@0+ (1,0) [0|1] "SED"  GWM

BO_ 464 ACU_Request_Signals_2: 8 ACM
 SG_ SDARS_DirectChannel_Rq : 9|10@0+ (1,0) [0|1023] "unitless"  APIM,APIM_CDC
 SG_ SdarsSampleRate_D_Rq : 31|2@0+ (1,0) [0|3] "SED"  APIM,APIM_CDC
 SG_ SdarsDirctChnl_No2_Rq : 39|16@0+ (1,0) [0|65535] "Unitless"  APIM

BO_ 467 APIM_Send_Signals_19: 8 APIM_CDC
 SG_ RjvntActv_D_Stat : 1|2@0+ (1,0) [0|3] "SED"  GWM
 SG_ RjvntSeatCool_B_Rq : 2|1@0+ (1,0) [0|1] "SED"  GWM
 SG_ RjvntSeatHeat_B_Rq : 3|1@0+ (1,0) [0|1] "SED"  GWM
 SG_ RjvntThemSel_D_Stat : 7|4@0+ (1,0) [0|15] "SED"  GWM
 SG_ RjvntSeatSetSavDrv_B_Rq : 8|1@0+ (1,0) [0|1] "SED"  GWM
 SG_ DgtlShadeAr1Front_D_Rq : 11|3@0+ (1,0) [0|7] "SED"  GWM
 SG_ RjvntPhs_D_Stat : 14|3@0+ (1,0) [0|7] "SED"  GWM
 SG_ RjvntScent_B_Rq : 15|1@0+ (1,0) [0|1] "SED"  GWM
 SG_ RjvntSeatMov_B_Rq : 17|1@0+ (1,0) [0|1] "SED"  GWM
 SG_ DgtlShadeAr3Front_D_Rq : 20|3@0+ (1,0) [0|7] "SED"  GWM
 SG_ DgtlShadeAr2Front_D_Rq : 23|3@0+ (1,0) [0|7] "SED"  GWM
 SG_ DgtlShadeAr5Front_D_Rq : 28|3@0+ (1,0) [0|7] "SED"  GWM
 SG_ DgtlShadeAr4Front_D_Rq : 31|3@0+ (1,0) [0|7] "SED"  GWM
 SG_ DgtlShadeMdeFront_D_Rq : 36|3@0+ (1,0) [0|7] "SED"  GWM
 SG_ DgtlShadeAr6Front_D_Rq : 39|3@0+ (1,0) [0|7] "SED"  GWM

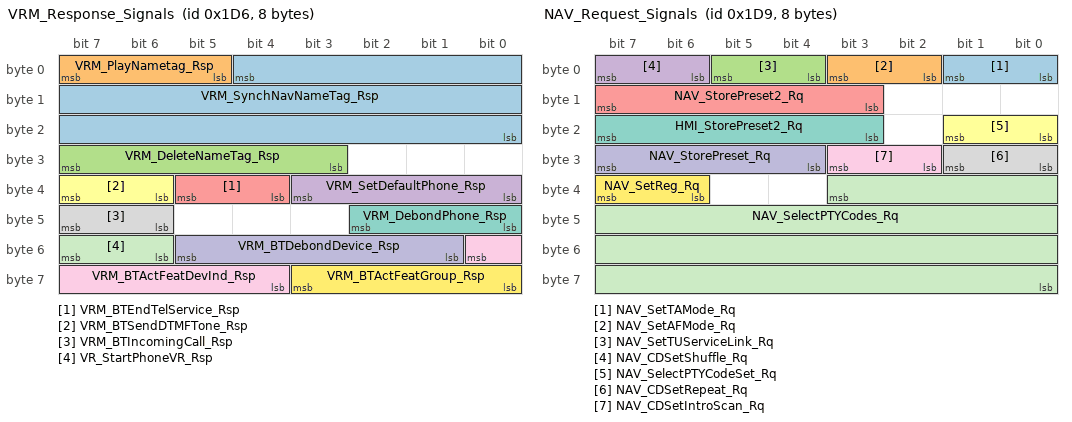
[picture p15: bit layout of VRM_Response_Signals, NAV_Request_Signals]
BO_ 470 VRM_Response_Signals: 8 APIM_CDC
 SG_ VRM_SynchNavNameTag_Rsp : 4|21@0+ (1,0) [0|2097151] "unitless" Vector__XXX
 SG_ VRM_PlayNametag_Rsp : 7|3@0+ (1,0) [0|7] "SED" Vector__XXX
 SG_ VRM_DeleteNameTag_Rsp : 31|5@0+ (1,0) [0|31] "SED" Vector__XXX
 SG_ VRM_SetDefaultPhone_Rsp : 35|4@0+ (1,0) [0|15] "SED" Vector__XXX
 SG_ VRM_BTEndTelService_Rsp : 37|2@0+ (1,0) [0|3] "SED"  HUD_ADV,IPC
 SG_ VRM_BTSendDTMFTone_Rsp : 39|2@0+ (1,0) [0|3] "SED" Vector__XXX
 SG_ VRM_DebondPhone_Rsp : 42|3@0+ (1,0) [0|7] "SED" Vector__XXX
 SG_ VRM_BTIncomingCall_Rsp : 47|2@0+ (1,0) [0|3] "SED"  HUD_ADV,IPC
 SG_ VRM_BTActFeatDevInd_Rsp : 48|5@0+ (1,0) [0|31] "SED" Vector__XXX
 SG_ VRM_BTDebondDevice_Rsp : 53|5@0+ (1,0) [0|31] "SED" Vector__XXX
 SG_ VR_StartPhoneVR_Rsp : 55|2@0+ (1,0) [0|3] "SED" Vector__XXX
 SG_ VRM_BTActFeatGroup_Rsp : 59|4@0+ (1,0) [0|15] "SED" Vector__XXX

BO_ 471 Av_PartName_1: 8 GWM
 SG_ ApnlNameTxt09_No_Actl : 7|8@0+ (1,0) [0|255] "unitless"  MRCMB_RDAPM_HS3
 SG_ ApnlNameTxt10_No_Actl : 15|8@0+ (1,0) [0|255] "unitless"  MRCMB_RDAPM_HS3
 SG_ ApnlNameTxt11_No_Actl : 23|8@0+ (1,0) [0|255] "unitless"  MRCMB_RDAPM_HS3
 SG_ ApnlNameTxt12_No_Actl : 31|8@0+ (1,0) [0|255] "unitless"  MRCMB_RDAPM_HS3
 SG_ ApnlNameTxt13_No_Actl : 39|8@0+ (1,0) [0|255] "unitless"  MRCMB_RDAPM_HS3
 SG_ ApnlNameTxt14_No_Actl : 47|8@0+ (1,0) [0|255] "unitless"  MRCMB_RDAPM_HS3
 SG_ ApnlNameTxt15_No_Actl : 55|8@0+ (1,0) [0|255] "unitless"  MRCMB_RDAPM_HS3
 SG_ ApnlNameTxt16_No_Actl : 63|8@0+ (1,0) [0|255] "unitless"  MRCMB_RDAPM_HS3

BO_ 472 Av_PartName_2: 8 GWM
 SG_ ApnlNameTxt17_No_Actl : 7|8@0+ (1,0) [0|255] "unitless"  MRCMB_RDAPM_HS3
 SG_ ApnlNameTxt18_No_Actl : 15|8@0+ (1,0) [0|255] "unitless"  MRCMB_RDAPM_HS3

BO_ 473 NAV_Request_Signals: 8 APIM_CDC
 SG_ NAV_SetTAMode_Rq : 1|2@0+ (1,0) [0|3] "SED"  ACM
 SG_ NAV_SetAFMode_Rq : 3|2@0+ (1,0) [0|3] "SED"  ACM,GENERIC
 SG_ NAV_SetTUServiceLink_Rq : 5|2@0+ (1,0) [0|3] "SED"  ACM
 SG_ NAV_CDSetShuffle_Rq : 7|2@0+ (1,0) [0|3] "SED"  ACM
 SG_ NAV_StorePreset2_Rq : 15|5@0+ (1,0) [0|31] "SED"  ACM
 SG_ NAV_SelectPTYCodeSet_Rq : 17|2@0+ (1,0) [0|3] "SED"  ACM
 SG_ HMI_StorePreset2_Rq : 23|5@0+ (1,0) [0|31] "SED"  ACM
 SG_ NAV_CDSetRepeat_Rq : 25|2@0+ (1,0) [0|3] "SED"  ACM
 SG_ NAV_CDSetIntroScan_Rq : 27|2@0+ (1,0) [0|3] "SED"  ACM
 SG_ NAV_StorePreset_Rq : 31|4@0+ (1,0) [0|15] "SED"  ACM,GENERIC
 SG_ NAV_SelectPTYCodes_Rq : 35|28@0+ (1,0) [0|268435455] "unitless"  ACM
 SG_ NAV_SetReg_Rq : 39|2@0+ (1,0) [0|3] "SED"  ACM

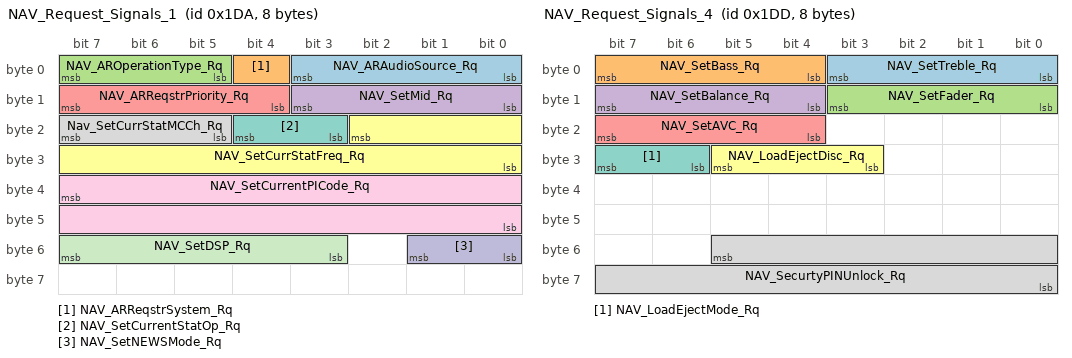
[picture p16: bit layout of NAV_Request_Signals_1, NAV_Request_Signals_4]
BO_ 474 NAV_Request_Signals_1: 8 APIM_CDC
 SG_ NAV_ARAudioSource_Rq : 3|4@0+ (1,0) [0|15] "SED"  ACM,DSP
 SG_ NAV_ARReqstrSystem_Rq : 4|1@0+ (1,0) [0|1] "SED"  ACM,DSP
 SG_ NAV_AROperationType_Rq : 7|3@0+ (1,0) [0|7] "SED"  ACM,DSP
 SG_ NAV_SetMid_Rq : 11|4@0+ (1,-7) [-7|8] "SED"  ACM,DSP
 SG_ NAV_ARReqstrPriority_Rq : 15|4@0+ (1,0) [0|15] "SED"  ACM,DSP
 SG_ NAV_SetCurrStatFreq_Rq : 18|11@0+ (1,0) [0|1557] "unitless"  ACM
 SG_ NAV_SetCurrentStatOp_Rq : 20|2@0+ (1,0) [0|3] "SED"  ACM
 SG_ Nav_SetCurrStatMCCh_Rq : 23|3@0+ (1,0) [0|7] "SED"  ACM
 SG_ NAV_SetCurrentPICode_Rq : 39|16@0+ (1,0) [0|65535] "unitless"  ACM
 SG_ NAV_SetNEWSMode_Rq : 49|2@0+ (1,0) [0|3] "SED"  ACM
 SG_ NAV_SetDSP_Rq : 55|5@0+ (1,0) [0|31] "SED"  ACM,DSP

BO_ 476 NAV_Request_Signals_3: 8 APIM_CDC
 SG_ NAV_SkipCatalouge_Rq : 7|2@0+ (1,0) [0|3] "SED"  ACM
 SG_ NAV_SetDSPProgram_Rq : 13|3@0+ (1,0) [0|7] "SED"  ACM
 SG_ NAV_SetOperationMode_Rq : 26|3@0+ (1,0) [0|7] "SED"  ACM
 SG_ Nav_SetAudioMixRatio_Rq : 31|5@0+ (1,0) [0|31] "decibel"  ACM

BO_ 477 NAV_Request_Signals_4: 8 APIM_CDC
 SG_ NAV_SetTreble_Rq : 3|4@0+ (1,-7) [-7|8] "SED"  ACM,DSP
 SG_ NAV_SetBass_Rq : 7|4@0+ (1,-7) [-7|8] "SED"  ACM,DSP
 SG_ NAV_SetFader_Rq : 11|4@0+ (1,-7) [-7|8] "SED"  ACM,DSP
 SG_ NAV_SetBalance_Rq : 15|4@0+ (1,-7) [-7|8] "SED"  ACM,DSP
 SG_ NAV_SetAVC_Rq : 23|4@0+ (1,0) [0|15] "SED"  ACM,DSP
 SG_ NAV_LoadEjectDisc_Rq : 29|3@0+ (1,0) [0|7] "SED"  ACM
 SG_ NAV_LoadEjectMode_Rq : 31|2@0+ (1,0) [0|3] "SED"  ACM
 SG_ NAV_SecurtyPINUnlock_Rq : 53|14@0+ (1,0) [0|16383] "unitless"  ACM

BO_ 478 Av_LDAPM_Data3_1: 8 GWM
 SG_ AplReas_No_Actl : 7|64@0+ (1,0) [0|1.84467440737096E+019] "unitless"  GENERIC

BO_ 479 DISP_Request_Sig: 8 APIM_CDC
 SG_ DISP_SetVolume_Rq : 5|6@0+ (1,-30) [-30|33] "steps"  ACM,DSP,GWM
 SG_ DISP_SetVol_Level_Rq : 13|6@0+ (1,0) [0|63] "unitless"  ACM,DSP,GWM
 SG_ DISP_SetVol_Source_Rq : 19|4@0+ (1,0) [0|15] "SED"  ACM,DSP,GWM,IPC
 SG_ DISP_Setshaker_Rq : 21|2@0+ (1,0) [0|3] "SED"  ACM,DSP,GWM

BO_ 481 AVPIM_MRC_Msg_1_HS3: 8 GWM
 SG_ PsDataPrim_No_Cs : 7|8@0+ (1,0) [0|255] "unitless" Vector__XXX
 SG_ PsDataPrim_No_Cnt : 11|4@0+ (1,0) [0|15] "unitless" Vector__XXX
 SG_ PsPrim_D_Stat : 15|4@0+ (1,0) [0|15] "SED"  APIM_CDC
 SG_ PsDiagPrim_B_Falt : 16|1@0+ (1,0) [0|1] "SED" Vector__XXX
 SG_ PsCpbltyPrim_B_Stat : 17|1@0+ (1,0) [0|7] "SED" Vector__XXX
 SG_ PsMainPrim_B_Falt : 18|1@0+ (1,0) [0|1] "SED" Vector__XXX
 SG_ PsSftyPrim_B_Falt : 19|1@0+ (1,0) [0|1] "SED" Vector__XXX
 SG_ PsShedPrim_B_Rq : 20|1@0+ (1,0) [0|1] "SED" Vector__XXX
 SG_ TurnLghtSwtch_D_Stat4 : 22|2@0+ (1,0) [0|3] "SED" Vector__XXX
 SG_ PsSftyPrim_B_Stat : 23|1@0+ (1,0) [0|1] "SED" Vector__XXX
 SG_ PsDataScnd_No_Cs : 31|8@0+ (1,0) [0|255] "unitless" Vector__XXX
 SG_ PsDataScnd_No_Cnt : 35|4@0+ (1,0) [0|15] "unitless" Vector__XXX
 SG_ PsScnd_D_Stat : 39|4@0+ (1,0) [0|15] "SED"  APIM_CDC
 SG_ PsCpbltyScnd_B_Stat : 40|1@0+ (1,0) [0|7] "SED" Vector__XXX
 SG_ PsDiagScnd_B_Falt : 41|1@0+ (1,0) [0|1] "SED" Vector__XXX
 SG_ PsMainScnd_B_Falt : 42|1@0+ (1,0) [0|1] "SED" Vector__XXX
 SG_ PsSftyScnd_B_Falt : 43|1@0+ (1,0) [0|1] "SED" Vector__XXX
 SG_ PsShedScnd_B_Rq : 44|1@0+ (1,0) [0|1] "SED" Vector__XXX
 SG_ AvTrgtPreAuthrz_B_Stat : 45|1@0+ (1,0) [0|1] "SED" Vector__XXX
 SG_ CakActvtn_D_Rq : 47|2@0+ (1,0) [0|3] "SED" Vector__XXX
 SG_ AdsIntfc_No_Cs : 55|8@0+ (1,0) [0|255] "unitless" Vector__XXX
 SG_ AdsIntfc_No_Cnt : 59|4@0+ (1,0) [0|15] "unitless" Vector__XXX
 SG_ PesSwtchA_D_Stat : 61|2@0+ (1,0) [0|3] "SED" Vector__XXX
 SG_ DrStatAllSides_D_Actl : 63|2@0+ (1,0) [0|3] "SED" Vector__XXX
 SG_ VehOnOff_D_RqArb : 67|4@0+ (1,0) [0|15] "SED" Vector__XXX
 SG_ StopExcptnl_D_Rq : 70|3@0+ (1,0) [0|7] "SED" Vector__XXX
 SG_ PsMainPrim_B_Stat : 71|1@0+ (1,0) [0|1] "SED" Vector__XXX
 SG_ DcdcUHiPrim_I_Actl : 79|8@0+ (0.1,0) [0|25.5] "ampere" Vector__XXX
 SG_ DcdcULoPrim_U_Actl : 87|8@0+ (0.1,0) [0|25.5] "volt" Vector__XXX
 SG_ PsULoPrim_I_Actl : 95|8@0+ (1,0) [0|255] "ampere" Vector__XXX
 SG_ PsULoPrim_I_Mx : 103|8@0+ (1,0) [0|255] "ampere" Vector__XXX
 SG_ DcdcUHiPrim_U_Actl : 111|10@0+ (0.5,0) [0|511.5] "volt" Vector__XXX
 SG_ PsULoOvrTeScnd_B_Stat : 112|1@0+ (1,0) [0|1] "SED" Vector__XXX
 SG_ PsULoOnScnd_B_Stat : 113|1@0+ (1,0) [0|1] "SED" Vector__XXX
 SG_ PsULoDcnntScnd_B_Stat : 114|1@0+ (1,0) [0|1] "SED" Vector__XXX
 SG_ PsULoOvrTePrim_B_Stat : 115|1@0+ (1,0) [0|1] "SED" Vector__XXX
 SG_ PsULoOnPrim_B_Stat : 116|1@0+ (1,0) [0|1] "SED" Vector__XXX
 SG_ PsULoDcnntPrim_B_Stat : 117|1@0+ (1,0) [0|1] "SED" Vector__XXX
 SG_ DcdcUHiScnd_I_Actl : 127|8@0+ (0.1,0) [0|25.5] "ampere" Vector__XXX
 SG_ DcdcULoScnd_U_Actl : 135|8@0+ (0.1,0) [0|25.5] "volt" Vector__XXX
 SG_ PsULoScnd_I_Actl : 143|8@0+ (1,0) [0|255] "ampere" Vector__XXX
 SG_ PsULoScnd_I_Mx : 151|8@0+ (1,0) [0|255] "ampere" Vector__XXX
 SG_ DcdcUHiScnd_U_Actl : 159|10@0+ (0.5,0) [0|511.5] "volt" Vector__XXX
 SG_ CakActvtnIndx_No_Rq : 165|6@0+ (1,0) [0|63] "unitless" Vector__XXX
 SG_ CoolFanDcdc_D_RqScnd : 169|2@0+ (1,0) [0|3] "SED" Vector__XXX
 SG_ DcdcClntFlw_D_RqScnd : 171|2@0+ (1,0) [0|3] "SED" Vector__XXX
 SG_ CoolFanDcdc_D_RqPrim : 173|2@0+ (1,0) [0|3] "SED" Vector__XXX
 SG_ DcdcClntFlw_D_RqPrim : 175|2@0+ (1,0) [0|3] "SED" Vector__XXX
 SG_ CldRecvry_B_Rq : 176|1@0+ (1,0) [0|1] "SED" Vector__XXX
 SG_ TvfSndShrt_D_Rq : 180|4@0+ (1,0) [0|15] "SED"  APIM_CDC
 SG_ ScanInProgress_B_Stat : 181|1@0+ (1,0) [0|1] "SED"  APIM,APIM_CDC
 SG_ AvDcdcWake_B_Rq : 182|1@0+ (1,0) [0|1] "SED" Vector__XXX
 SG_ VdsScndWake_B_Rq : 183|1@0+ (1,0) [0|1] "SED" Vector__XXX
 SG_ FmesSndShrt_D_Rq : 188|5@0+ (1,0) [0|63] "SED"  APIM
 SG_ VdsPrimWake_B_Rq : 189|1@0+ (1,0) [0|1] "SED" Vector__XXX
 SG_ RefuelCtlPw_B_Rq : 190|1@0+ (1,0) [0|1] "SED" Vector__XXX
 SG_ DataCtlPw_B_Rq : 191|1@0+ (1,0) [0|1] "SED" Vector__XXX
 SG_ VehOnOff_D_Stat : 195|4@0+ (1,0) [0|15] "SED" Vector__XXX
 SG_ PostCtlPw_B_Rq : 196|1@0+ (1,0) [0|1] "SED" Vector__XXX
 SG_ AVPIM_PwrOFF_B_Rq : 197|1@0+ (1,0) [0|1] "SED" Vector__XXX
 SG_ AvDcdcIntgtyChk_B_Stat : 198|1@0+ (1,0) [0|1] "SED" Vector__XXX
 SG_ PesSwtchB_D_Stat : 207|2@0+ (1,0) [0|3] "SED" Vector__XXX

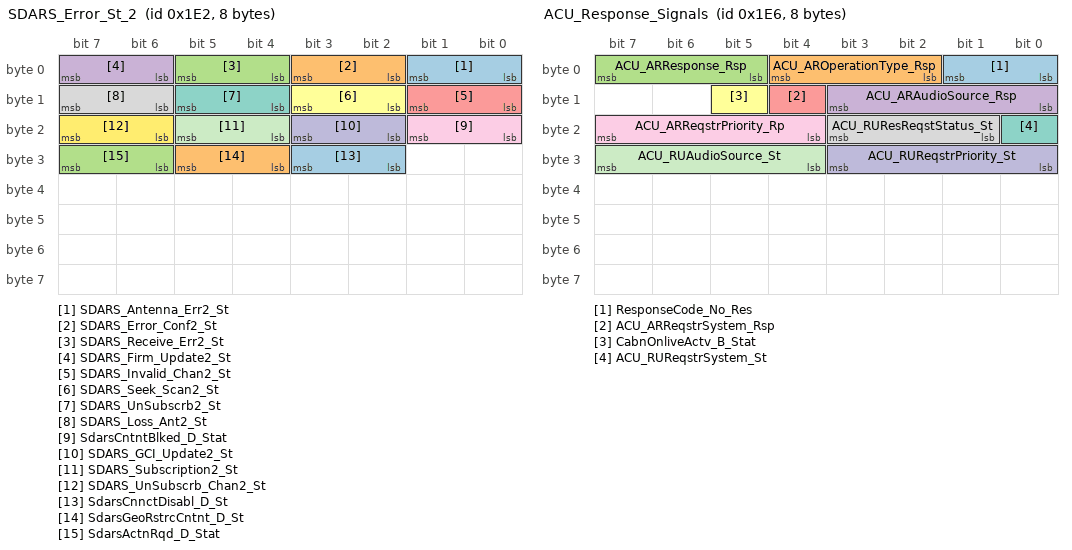
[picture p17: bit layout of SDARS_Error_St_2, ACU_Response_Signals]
BO_ 482 SDARS_Error_St_2: 8 APIM_CDC
 SG_ SDARS_Antenna_Err2_St : 1|2@0+ (1,0) [0|3] "SED"  IPC,RACM_RCIM
 SG_ SDARS_Error_Conf2_St : 3|2@0+ (1,0) [0|3] "SED"  IPC,RACM_RCIM
 SG_ SDARS_Receive_Err2_St : 5|2@0+ (1,0) [0|3] "SED"  IPC,RACM_RCIM
 SG_ SDARS_Firm_Update2_St : 7|2@0+ (1,0) [0|3] "SED"  IPC,RACM_RCIM
 SG_ SDARS_Invalid_Chan2_St : 9|2@0+ (1,0) [0|3] "SED"  IPC,RACM_RCIM
 SG_ SDARS_Seek_Scan2_St : 11|2@0+ (1,0) [0|3] "SED"  IPC,RACM_RCIM
 SG_ SDARS_UnSubscrb2_St : 13|2@0+ (1,0) [0|3] "SED"  IPC,RACM_RCIM
 SG_ SDARS_Loss_Ant2_St : 15|2@0+ (1,0) [0|3] "SED"  IPC,RACM_RCIM
 SG_ SdarsCntntBlked_D_Stat : 17|2@0+ (1,0) [0|3] "SED"  RACM_RCIM
 SG_ SDARS_GCI_Update2_St : 19|2@0+ (1,0) [0|3] "SED"  IPC,RACM_RCIM
 SG_ SDARS_Subscription2_St : 21|2@0+ (1,0) [0|3] "SED"  IPC,RACM_RCIM
 SG_ SDARS_UnSubscrb_Chan2_St : 23|2@0+ (1,0) [0|3] "SED"  IPC,RACM_RCIM
 SG_ SdarsCnnctDisabl_D_St : 27|2@0+ (1,0) [0|3] "SED"  RACM_RCIM
 SG_ SdarsGeoRstrcCntnt_D_St : 29|2@0+ (1,0) [0|3] "SED"  RACM_RCIM
 SG_ SdarsActnRqd_D_Stat : 31|2@0+ (1,0) [0|3] "SED"  RACM_RCIM

BO_ 486 ACU_Response_Signals: 8 APIM_CIM
 SG_ ResponseCode_No_Res : 1|2@0+ (1,0) [0|3] "SED"  APIM,APIM_CDC
 SG_ ACU_AROperationType_Rsp : 4|3@0+ (1,0) [0|7] "SED"  APIM,APIM_CDC,DSP,GWM,IPC
 SG_ ACU_ARResponse_Rsp : 7|3@0+ (1,0) [0|6] "SED"  APIM,APIM_CDC,DSP,GWM,IPC
 SG_ ACU_ARAudioSource_Rsp : 11|4@0+ (1,0) [0|15] "SED"  APIM,APIM_CDC,DSP,GWM,IPC
 SG_ ACU_ARReqstrSystem_Rsp : 12|1@0+ (1,0) [0|1] "SED"  APIM,APIM_CDC,DSP,GWM,IPC
 SG_ CabnOnliveActv_B_Stat : 13|1@0+ (1,0) [0|1] "SED"  DSP,GWM
 SG_ ACU_RUReqstrSystem_St : 16|1@0+ (1,0) [0|1] "SED"  APIM,APIM_CDC,DSP,GWM,HUD_ADV,IPC,RACM_RCIM,WCM,WCMB,WCMC
 SG_ ACU_RUResReqstStatus_St : 19|3@0+ (1,0) [0|7] "SED"  APIM,APIM_CDC,DSP,GWM,HUD_ADV,IPC,RACM_RCIM,WCM,WCMB,WCMC
 SG_ ACU_ARReqstrPriority_Rp : 23|4@0+ (1,0) [0|15] "SED"  APIM,APIM_CDC,DSP,GWM,IPC
 SG_ ACU_RUReqstrPriority_St : 27|4@0+ (1,0) [0|15] "SED"  APIM,APIM_CDC,DSP,GWM,HUD_ADV,IPC,RACM_RCIM,WCM,WCMB,WCMC
 SG_ ACU_RUAudioSource_St : 31|4@0+ (1,0) [0|15] "SED"  APIM,APIM_CDC,DSP,GWM,HUD_ADV,IPC,RACM_RCIM,WCM,WCMB,WCMC

BO_ 487 ACU_Request_Signals: 8 APIM_CISM
 SG_ Aioc_SetExtSrcOutpMd_Rq : 31|4@0+ (1,0) [0|15] "SED"  GENERIC

BO_ 488 ARM_Data: 8 ARM
 SG_ AugRealtyMdule_B_Rq : 7|1@0+ (1,0) [0|1] "SED"  GWM

BO_ 489 ACU_Send_Signals_1: 8 APIM_CIM
 SG_ ACU_CurrentPSName_St : 7|64@0+ (1,0) [0|1.84467440737096E+019] "unitless"  APIM,APIM_CDC,GWM,IPC,RACM_RCIM

BO_ 490 HMI_Request_Signals_2: 8 APIM_CDC
 SG_ HMI_SetCompression_Rq : 9|2@0+ (1,0) [0|3] "SED"  ACM
 SG_ HMI_SkipTrack_Rq : 35|2@0+ (1,0) [0|3] "SED"  ACM

BO_ 493 Dsp_Request_Signals_10: 8 APIM_CDC
 SG_ Dsp_StationList_Rq : 7|4@0+ (1,0) [0|15] "SED"  ACM
 SG_ Dsp_AFJump_Rq : 9|2@0+ (1,0) [0|3] "SED"  ACM
 SG_ Dsp_RefreshFlag : 10|1@0+ (1,0) [0|1] "SED"  ACM
 SG_ Dsp_ListSize_Rq : 15|5@0+ (1,0) [0|31] "SED"  ACM
 SG_ Dsp_StartIndex3_Rq : 23|8@0+ (1,0) [0|255] "unitless"  ACM
 SG_ Dsp_PTYCode_Rq : 31|5@0+ (1,0) [0|31] "SED"  ACM
 SG_ Dsp_StatLiScanCancel_Rq : 39|1@0+ (1,0) [0|1] "SED"  ACM

BO_ 494 HEC_Request_Signals_6: 8 APIM_CDC
 SG_ HEC_TUPresetArea_Rq : 3|4@0+ (1,0) [0|15] "SED"  ACM,APIM_CISM
 SG_ HEC_SetCurrTUBand_Rq : 7|4@0+ (1,0) [0|15] "SED"  ACM,APIM_CISM
 SG_ HEC_TUStartIndex2_Rq : 15|8@0+ (1,0) [0|255] "unitless"  ACM,APIM_CISM
 SG_ HEC_TUNbrOfPresets_Rq : 23|5@0+ (1,0) [0|30] "unitless"  ACM,APIM_CISM
 SG_ Mc_SetCurrPreset2_Rq : 31|5@0+ (1,0) [0|30] "SED"  ACM,APIM_CISM

BO_ 497 Mc_Request_Signals11: 8 IPC
 SG_ McEvntNotfnMsgId_No_Rq : 2|11@0+ (1,0) [0|2047] "unitless"  APIM,APIM_CISM
 SG_ McEvntNotfnChoice_D_Rq : 5|3@0+ (1,0) [0|7] "SED"  APIM,APIM_CISM
 SG_ McEvntNotfnMsgId_D_Rq : 7|2@0+ (1,0) [0|3] "SED"  APIM,APIM_CISM
 SG_ McEvntNotfnData1_D_Rq : 23|16@0+ (1,0) [0|65535] "unitless"  APIM,APIM_CISM
 SG_ McEvntNotfnData2_D_Rq : 39|16@0+ (1,0) [0|65535] "unitless"  APIM,APIM_CISM
 SG_ McEvntNotfnData3_D_Rq : 55|16@0+ (1,0) [0|65535] "unitless"  APIM,APIM_CISM

BO_ 498 HEC_Request_Signals_3: 8 APIM_CDC
 SG_ HEC_ARAudioSource_Rq : 3|4@0+ (1,0) [0|15] "SED"  ACM,APIM_CISM
 SG_ HEC_ARReqstrSystem_Rq : 4|1@0+ (1,0) [0|1] "SED"  ACM,APIM_CISM
 SG_ HEC_AROperationType_Rq : 7|3@0+ (1,0) [0|7] "SED"  ACM,APIM_CISM
 SG_ HEC_ARReqstrPriority_Rq : 11|4@0+ (1,0) [0|15] "SED"  ACM,APIM_CISM

BO_ 500 DSP_Request_Signals_1: 8 APIM_CDC
 SG_ Dsp_GetCDTOCDData_Rq : 0|2@0+ (1,0) [0|3] "SED"  ACM
 SG_ Dsp_AudioSourceSel_Rq : 3|3@0+ (1,0) [0|7] "SED"  ACM
 SG_ Dsp_CutItem_Rq : 9|2@0+ (1,0) [0|3] "SED"  ACM
 SG_ Dsp_ItemNameLength_Rq : 14|5@0+ (1,0) [0|20] "SED"  ACM
 SG_ Dsp_FolderNumber_Rq : 23|16@0+ (1,0) [0|65535] "unitless"  ACM
 SG_ Dsp_SourceSetTrack_Rq : 39|32@0+ (1,0) [0|4294967295] "unitless"  ACM

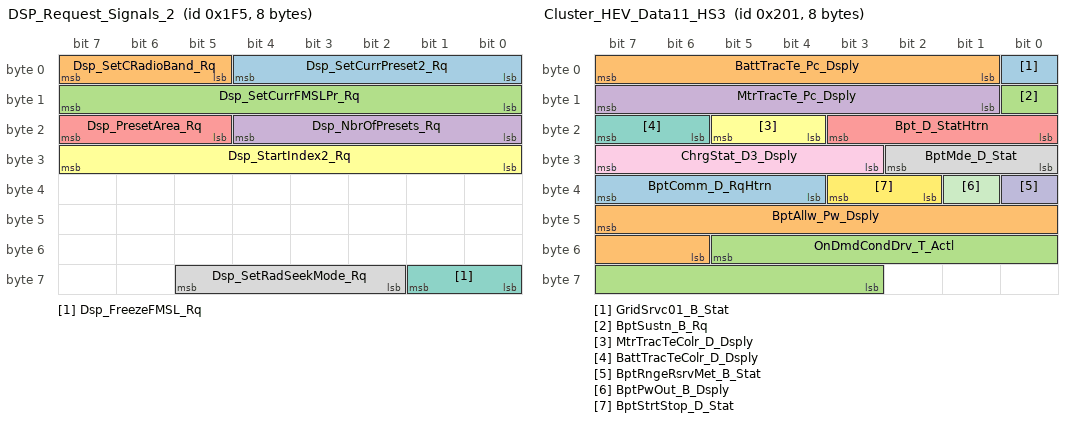
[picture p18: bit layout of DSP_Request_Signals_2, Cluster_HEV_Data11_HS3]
BO_ 501 DSP_Request_Signals_2: 8 APIM_CDC
 SG_ Dsp_SetCurrPreset2_Rq : 4|5@0+ (1,0) [0|30] "SED"  ACM
 SG_ Dsp_SetCRadioBand_Rq : 7|3@0+ (1,0) [0|7] "SED"  ACM
 SG_ Dsp_SetCurrFMSLPr_Rq : 15|8@0+ (1,0) [0|254] "unitless"  ACM
 SG_ Dsp_NbrOfPresets_Rq : 20|5@0+ (1,0) [0|30] "unitless"  ACM
 SG_ Dsp_PresetArea_Rq : 23|3@0+ (1,0) [0|7] "SED"  ACM
 SG_ Dsp_StartIndex2_Rq : 31|8@0+ (1,0) [0|255] "unitless"  ACM
 SG_ Dsp_FreezeFMSL_Rq : 57|2@0+ (1,0) [0|3] "SED"  ACM
 SG_ Dsp_SetRadSeekMode_Rq : 61|4@0+ (1,0) [0|15] "SED"  ACM

BO_ 502 DSP_Request_Signals_3: 8 APIM_CDC
 SG_ Dsp_ItemNameLength2_Rq : 5|5@0+ (1,0) [0|20] "SED"  ACM
 SG_ Dsp_FolderContent_Rq : 7|2@0+ (1,0) [0|3] "SED"  ACM
 SG_ Dsp_CutItem2_Rq : 9|2@0+ (1,0) [0|3] "SED"  ACM
 SG_ Dsp_NbrOfItems2_Rq : 14|5@0+ (1,0) [0|20] "SED"  ACM
 SG_ Dsp_FolderNumber2_Rq : 23|16@0+ (1,0) [0|65535] "unitless"  ACM
 SG_ Dsp_StartItemIndexRq : 39|16@0+ (1,0) [0|65535] "unitless"  ACM
 SG_ Dsp_AudioSourceSel2_Rq : 55|3@0+ (1,0) [0|7] "SED"  ACM

BO_ 503 DSP_Request_Signals_4: 8 APIM_CDC
 SG_ Dsp_FolderNumber3_Rq : 7|16@0+ (1,0) [0|65535] "unitless"  ACM
 SG_ Dsp_ItemIndex_Rq : 23|16@0+ (1,0) [0|65535] "unitless"  ACM
 SG_ Dsp_PlayFrstTrInFldr_Rq : 39|16@0+ (1,0) [0|65535] "unitless"  ACM
 SG_ Dsp_AudioSourceSel3_Rq : 55|3@0+ (1,0) [0|7] "SED"  ACM

BO_ 504 Mc_Request_Signals: 8 APIM_CDC
 SG_ Mc_AudioSourceSel_Rq : 3|3@0+ (1,0) [0|7] "SED"  ACM,APIM_CISM,GWM
 SG_ Mc_CutItem_Rq : 9|2@0+ (1,0) [0|3] "SED"  ACM,APIM_CISM,GWM
 SG_ Mc_ItemNameLength_Rq : 14|5@0+ (1,0) [0|20] "SED"  ACM,APIM_CISM,GWM
 SG_ Mc_FolderNumber_Rq : 23|16@0+ (1,0) [0|65535] "unitless"  ACM,APIM_CISM,GWM
 SG_ Mc_SourceSetTrack_Rq : 39|32@0+ (1,0) [0|4294967295] "unitless"  ACM,APIM_CISM,GWM

BO_ 505 Mc_Request_Signals_2: 8 APIM_CDC
 SG_ Mc_ItemNameLength2_Rq : 5|5@0+ (1,0) [0|20] "SED"  ACM,APIM_CISM,GWM
 SG_ Mc_FolderContent_Rq : 7|2@0+ (1,0) [0|3] "SED"  ACM,APIM_CISM,GWM
 SG_ Mc_CutItem2_Rq : 9|2@0+ (1,0) [0|3] "SED"  ACM,APIM_CISM,GWM
 SG_ Mc_NbrOfItems2_Rq : 14|5@0+ (1,0) [0|20] "SED"  ACM,APIM_CISM,GWM
 SG_ Mc_FolderNumber2_Rq : 23|16@0+ (1,0) [0|65535] "unitless"  ACM,APIM_CISM,GWM
 SG_ Mc_StartItemIndexRq : 39|16@0+ (1,0) [0|65535] "unitless"  ACM,APIM_CISM,GWM
 SG_ Mc_AudioSourceSel2_Rq : 55|3@0+ (1,0) [0|7] "SED"  ACM,APIM_CISM,GWM

BO_ 506 Mc_Request_Signals_3: 8 APIM_CDC
 SG_ Mc_FolderNumber3_Rq : 7|16@0+ (1,0) [0|65535] "unitless"  ACM,APIM_CISM,GWM
 SG_ Mc_ItemIndex_Rq : 23|16@0+ (1,0) [0|65535] "unitless"  ACM,APIM_CISM,GWM
 SG_ Mc_PlayFrstTrInFldr_Rq : 39|16@0+ (1,0) [0|65535] "unitless"  ACM,APIM_CISM,GWM
 SG_ Mc_AudioSourceSel3_Rq : 55|3@0+ (1,0) [0|7] "SED"  ACM,APIM_CISM,GWM

BO_ 507 Mc_Request_Signals_4: 8 APIM_CDC
 SG_ Mc_DB1SetTrkSetFilt1_Rq : 7|16@0+ (1,0) [0|65535] "unitless"  ACM,APIM_CISM,GWM
 SG_ Mc_DB1SetTrkSetFilt2_Rq : 23|16@0+ (1,0) [0|65535] "unitless"  ACM,APIM_CISM,GWM
 SG_ Mc_DB1SetTrkSetFilt3_Rq : 33|10@0+ (1,0) [0|1023] "unitless"  ACM,APIM_CISM,GWM
 SG_ Mc_DB1SetTrkSetConf_Rq : 38|5@0+ (1,0) [0|31] "SED"  ACM,APIM_CISM,GWM
 SG_ Mc_DB1SetTrkItmIndex_Rq : 55|16@0+ (1,0) [0|65535] "unitless"  ACM,APIM_CISM,GWM

BO_ 508 Mc_Request_Signals_5: 8 APIM_CDC
 SG_ Mc_DB1GetInfSetFilt1_Rq : 7|16@0+ (1,0) [0|65535] "unitless"  ACM,APIM_CISM,GWM
 SG_ Mc_DB1GetInfSetFilt2_Rq : 23|16@0+ (1,0) [0|65535] "unitless"  ACM,APIM_CISM,GWM
 SG_ Mc_DB1GetInfSetFilt3_Rq : 33|10@0+ (1,0) [0|1023] "unitless"  ACM,APIM_CISM,GWM
 SG_ Mc_DB1GetInfSetConf_Rq : 38|5@0+ (1,0) [0|31] "SED"  ACM,APIM_CISM,GWM
 SG_ Mc_DB1GtInfNbrOfItms_Rq : 39|1@0+ (1,0) [0|1] "SED"  ACM,APIM_CISM,GWM
 SG_ Mc_DB1GetInfStartInd_Rq : 55|16@0+ (1,0) [0|65535] "unitless"  ACM,APIM_CISM,GWM

BO_ 509 Cluster_Info_2: 8 IPC
 SG_ TrakAppl_D_Stat : 7|3@0+ (1,0) [0|7] "SED"  APIM,APIM_CISM,GWM

BO_ 511 DSP_Request_Signals_8: 8 APIM_CDC
 SG_ Dsp_TUPresetArea_Rq : 3|4@0+ (1,0) [0|15] "SED"  ACM
 SG_ Dsp_SetCurrTUBand_Rq : 7|4@0+ (1,0) [0|15] "SED"  ACM
 SG_ Dsp_TUStartIndex2_Rq : 15|8@0+ (1,0) [0|255] "unitless"  ACM
 SG_ SdarsAudioRtng_D_Rq : 18|2@0+ (1,0) [0|3] "SED"  ACM
 SG_ Dsp_TUNbrOfPresets_Rq : 23|5@0+ (1,0) [0|30] "SED"  ACM
 SG_ Dsp_SetCurrTUPreset_Rq : 31|5@0+ (1,0) [0|31] "SED"  ACM

BO_ 512 TorqueDataEngFlags_HS3: 8 GWM
 SG_ EngAout_Tq_MxMxN : 2|11@0+ (1,-500) [-500|1547] "Nm" Vector__XXX
 SG_ PrplWhlTot_Tq_LimMn : 23|16@0+ (4,-131072) [-131072|131068] "Nm" Vector__XXX
 SG_ PrplWhlTot_Tq_Rq : 39|16@0+ (4,-131072) [-131072|131068] "Nm" Vector__XXX
 SG_ PrplWhlTotTqRq_No_Cnt : 51|4@0+ (1,0) [0|15] "unitless" Vector__XXX
 SG_ PtDrvMde_D_Stat : 55|4@0+ (1,0) [0|15] "SED"  ACM,APIM_CDC,APIM_CIM,APIM_CISM,IPC
 SG_ PrplWhlTotTqRq_No_Cs : 63|8@0+ (1,0) [0|255] "unitless" Vector__XXX

BO_ 513 Cluster_HEV_Data11_HS3: 8 GWM
 SG_ GridSrvc01_B_Stat : 0|1@0+ (1,0) [0|1] "SED"  APIM,APIM_CDC,APIM_CIM,APIM_CISM
 SG_ BattTracTe_Pc_Dsply : 7|7@0+ (1,0) [0|127] "percent"  APIM_CDC,APIM_CIM,IPC
 SG_ BptSustn_B_Rq : 8|1@0+ (1,0) [0|1] "SED"  APIM,APIM_CDC,APIM_CIM,APIM_CISM
 SG_ MtrTracTe_Pc_Dsply : 15|7@0+ (1,0) [0|127] "percent"  APIM_CDC,APIM_CIM,IPC
 SG_ Bpt_D_StatHtrn : 19|4@0+ (1,0) [0|15] "SED"  APIM,APIM_CDC,APIM_CIM,APIM_CISM
 SG_ MtrTracTeColr_D_Dsply : 21|2@0+ (1,0) [0|3] "SED"  APIM_CDC,APIM_CIM,IPC
 SG_ BattTracTeColr_D_Dsply : 23|2@0+ (1,0) [0|3] "SED"  APIM_CDC,APIM_CIM,IPC
 SG_ BptMde_D_Stat : 26|3@0+ (1,0) [0|7] "SED"  APIM,APIM_CDC,APIM_CIM,APIM_CISM
 SG_ ChrgStat_D3_Dsply : 31|5@0+ (1,0) [0|31] "SED"  APIM,APIM_CDC,APIM_CIM,APIM_CISM,IPC
 SG_ BptRngeRsrvMet_B_Stat : 32|1@0+ (1,0) [0|1] "SED"  APIM,APIM_CDC,APIM_CIM,APIM_CISM
 SG_ BptPwOut_B_Dsply : 33|1@0+ (1,0) [0|1] "SED"  APIM,APIM_CDC,APIM_CIM,APIM_CISM
 SG_ BptStrtStop_D_Stat : 35|2@0+ (1,0) [0|3] "SED"  APIM,APIM_CDC,APIM_CIM,APIM_CISM
 SG_ BptComm_D_RqHtrn : 39|4@0+ (1,0) [0|15] "SED"  APIM,APIM_CDC,APIM_CIM,APIM_CISM
 SG_ BptAllw_Pw_Dsply : 47|10@0+ (0.1,0) [0|102.3] "kilowatt"  APIM,APIM_CDC,APIM_CIM,APIM_CISM
 SG_ OnDmdCondDrv_T_Actl : 53|11@0+ (1,0) [0|2047] "minute" Vector__XXX

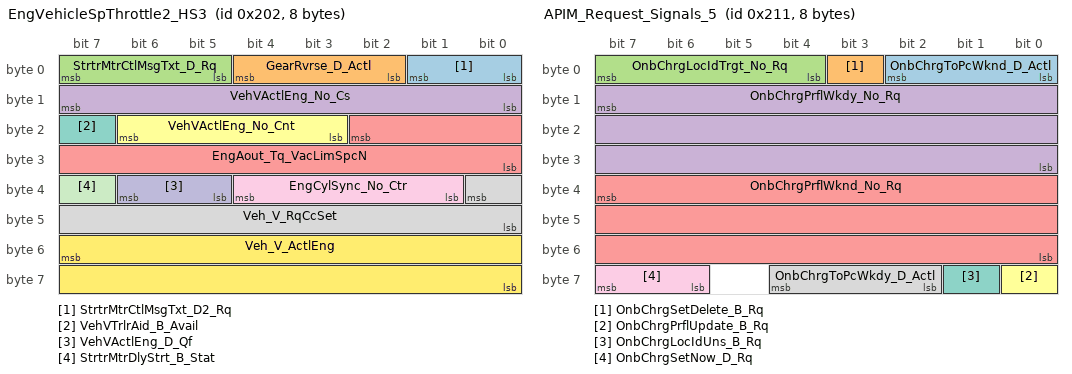
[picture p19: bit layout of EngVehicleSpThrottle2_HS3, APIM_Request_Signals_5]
BO_ 514 EngVehicleSpThrottle2_HS3: 8 GWM
 SG_ StrtrMtrCtlMsgTxt_D2_Rq : 1|2@0+ (1,0) [0|3] "SED"  APIM_CDC,APIM_CIM,IPC
 SG_ GearRvrse_D_Actl : 4|3@0+ (1,0) [0|7] "SED"  APIM,APIM_CDC,APIM_CIM,APIM_CISM,HUD_ADV,IPC,TRM_ITRM
 SG_ StrtrMtrCtlMsgTxt_D_Rq : 7|3@0+ (1,0) [0|7] "SED"  APIM_CDC,APIM_CIM,IPC
 SG_ VehVActlEng_No_Cs : 15|8@0+ (1,0) [0|255] "unitless"  GENERIC
 SG_ EngAout_Tq_VacLimSpcN : 18|11@0+ (1,-500) [-500|1547] "Nm"  GENERIC
 SG_ VehVActlEng_No_Cnt : 22|4@0+ (1,0) [0|15] "Unitless"  GENERIC
 SG_ VehVTrlrAid_B_Avail : 23|1@0+ (1,0) [0|1] "SED"  GENERIC
 SG_ Veh_V_RqCcSet : 32|9@0+ (0.5,0) [0|255.5] "kph"  IPC
 SG_ EngCylSync_No_Ctr : 36|4@0+ (1,0) [0|15] "unitless"  GENERIC
 SG_ VehVActlEng_D_Qf : 38|2@0+ (1,0) [0|3] "SED"  ACM,APIM,APIM_CDC,APIM_CIM,APIM_CISM,DSP,IPC,WCM,WCMB,WCMC
 SG_ StrtrMtrDlyStrt_B_Stat : 39|1@0+ (1,0) [0|1] "SED"  GENERIC
 SG_ Veh_V_ActlEng : 55|16@0+ (0.01,0) [0|655.35] "kph"  ACM,APIM,APIM_CDC,APIM_CIM,APIM_CISM,DSP,IPC,TRM_ITRM,WCM,WCMB,WCMC

BO_ 515 PowertrainData_12_HS3: 8 GWM
 SG_ FuelLvlAct_Pc_DsplyEng : 5|10@0+ (0.108696,-5.217408) [-5.217408|105.9786] "percent"  APIM,APIM_CDC,APIM_CIM,APIM_CISM,IPC
 SG_ PtIgnSwtch_D_Stat : 7|2@0+ (1,0) [0|3] "SED" Vector__XXX
 SG_ FuelLvlPss_Pc_DsplyEng : 9|10@0+ (0.108696,-5.217408) [-5.217408|105.9786] "percent"  APIM,APIM_CDC,APIM_CIM,APIM_CISM,IPC
 SG_ ExtndPwDelvr_D_Stat : 11|2@0+ (1,0) [0|3] "SED" Vector__XXX

BO_ 516 EngVehicleSpThrottle_HS3: 8 GWM
 SG_ ApedPos_Pc_ActlArb : 1|10@0+ (0.1,0) [0|102.3] "%"  ACM,APIM,APIM_CDC,APIM_CIM,APIM_CISM
 SG_ ApedPosPcActl_No_Cnt : 5|4@0+ (1,0) [0|15] "unitless"  GENERIC
 SG_ ApedPosPcActl_D_Qf : 7|2@0+ (1,0) [0|3] "SED"  ACM,APIM,APIM_CDC,APIM_CIM,APIM_CISM
 SG_ ApedPos_PcRate_ActlArb : 23|8@0+ (0.04,-5) [-5|5.2] "%/ms"  ACM,APIM_CDC,APIM_CIM,APIM_CISM
 SG_ EngAout_N_Actl : 28|13@0+ (2,0) [0|16382] "rpm"  ACM,APIM,APIM_CDC,APIM_CIM,APIM_CISM,DSP,IPC
 SG_ EngAoutNActl_D_QF : 31|2@0+ (1,0) [0|3] "SED"  GENERIC
 SG_ ApedPosPcActl_No_Cs : 47|8@0+ (1,0) [0|255] "unitless"  GENERIC
 SG_ EngAout3_N_Actl : 55|16@0+ (0.25,0) [0|16383.75] "RPM"  GENERIC

BO_ 523 Engine_Data_18_HS3: 8 GWM
 SG_ EngAirFiltMsgTxt_D_Rq : 2|3@0+ (1,0) [0|7] "SED"  APIM_CDC,APIM_CIM,IPC
 SG_ UreaMnAdd_L_Actl : 7|5@0+ (1,0) [0|31] "litre"  APIM_CDC,APIM_CIM,APIM_CISM,IPC
 SG_ WaterInFuel_B_Falt : 8|1@0+ (1,0) [0|1] "SED"  APIM_CDC,APIM_CIM,APIM_CISM,IPC
 SG_ EngAirFiltLife_Pc_Actl : 15|7@0+ (1,0) [0|127] "percent"  APIM_CDC,APIM_CIM,IPC
 SG_ UreaMnAdd_L2_Actl : 23|8@0+ (0.1,0) [0|25.5] "litre"  APIM_CDC,APIM_CIM,APIM_CISM,IPC
 SG_ VehUreaRnge3_L_DsplyMx : 31|16@0+ (1,0) [0|65535] "unitless"  APIM_CDC,APIM_CIM,APIM_CISM,IPC
 SG_ UreaMxAdd_L2_Actl : 47|9@0+ (0.1,0) [0|51.1] "litre"  APIM_CDC,APIM_CIM,APIM_CISM,IPC

BO_ 528 Body_Info_17_HS3: 8 GWM
 SG_ TireFront_P_OffRoad1 : 7|8@0+ (1,0) [0|255] "pounds/inch^2"  APIM_CDC,IPC
 SG_ TireFront_P_OffRoad2 : 15|8@0+ (1,0) [0|255] "pounds/inch^2"  APIM_CDC,IPC
 SG_ TireRear_P_OffRoad1 : 23|8@0+ (1,0) [0|255] "pounds/inch^2"  APIM_CDC,IPC
 SG_ TireRear_P_OffRoad2 : 31|8@0+ (1,0) [0|255] "pounds/inch^2"  APIM_CDC,IPC
 SG_ HazrdLghtMde_D_Stat : 33|2@0+ (1,0) [0|3] "SED"  APIM,APIM_CDC,IPC
 SG_ WndwCabnMde_D_Stat : 35|2@0+ (1,0) [0|3] "SED"  APIM,APIM_CDC,IPC
 SG_ OffRoadMde_D_Stat : 38|3@0+ (1,0) [0|7] "SED"  APIM_CDC,IPC
 SG_ TireInflateMsgTxt_B_Rq : 39|1@0+ (1,0) [0|1] "SED"  APIM_CDC,IPC
 SG_ SilentMde_B_Stat : 40|1@0+ (1,0) [0|1] "SED" Vector__XXX
 SG_ VehNotConfgd_D_Rq : 42|2@0+ (1,0) [0|3] "SED" Vector__XXX
 SG_ CrashCrtsy_B_Rq : 43|1@0+ (1,0) [0|1] "SED" Vector__XXX
 SG_ DelvrAsstButtn_D_Stat : 45|2@0+ (1,0) [0|3] "SED"  APIM,APIM_CDC,IPC
 SG_ DelvrAsstLckMde_D_Stat : 47|2@0+ (1,0) [0|3] "SED"  APIM,APIM_CDC,IPC
 SG_ KeylessIdlSrc_D_Stat : 51|3@0+ (1,0) [0|7] "SED"  APIM,APIM_CDC,APIM_CIM,IPC
 SG_ KeylessIdl_D_Stat : 53|2@0+ (1,0) [0|3] "SED"  APIM,APIM_CDC,APIM_CIM,IPC
 SG_ PrmtrAlrmCrtsy_D_Rq : 55|2@0+ (1,0) [0|3] "SED" Vector__XXX
 SG_ BodyCtlFeatReset_D_St : 63|8@0+ (1,0) [0|255] "SED" Vector__XXX

BO_ 529 APIM_Request_Signals_5: 8 APIM_CDC
 SG_ OnbChrgToPcWknd_D_Actl : 2|3@0+ (1,0) [0|7] "percent"  GWM
 SG_ OnbChrgSetDelete_B_Rq : 3|1@0+ (1,0) [0|1] "SED"  GWM
 SG_ OnbChrgLocIdTrgt_No_Rq : 7|4@0+ (1,0) [0|15] "unitless"  GWM
 SG_ OnbChrgPrflWkdy_No_Rq : 15|24@0+ (1,0) [0|16777215] "unitless"  GWM
 SG_ OnbChrgPrflWknd_No_Rq : 39|24@0+ (1,0) [0|16777215] "unitless"  GWM
 SG_ OnbChrgPrflUpdate_B_Rq : 56|1@0+ (1,0) [0|1] "SED"  GWM
 SG_ OnbChrgLocIdUns_B_Rq : 57|1@0+ (1,0) [0|1] "SED"  GWM
 SG_ OnbChrgToPcWkdy_D_Actl : 60|3@0+ (1,0) [0|7] "percent"  GWM
 SG_ OnbChrgSetNow_D_Rq : 63|2@0+ (1,0) [0|3] "SED"  GWM

BO_ 530 APIM_Request_Signals_6: 8 APIM_CDC
 SG_ DabStationId_No_Rq : 7|16@0+ (1,0) [0|65535] "unitless"  ACM
 SG_ DabStationCodeId_No_Rq : 23|16@0+ (1,0) [0|65535] "unitless"  ACM
 SG_ PiCode_No_Rq : 39|16@0+ (1,0) [0|65535] "unitless"  ACM
 SG_ DabExtndCntryCode_No_Rq : 55|8@0+ (1,0) [0|255] "unitless"  ACM
 SG_ StationTypeSel_D_Rq : 61|2@0+ (1,0) [0|3] "SED"  ACM

BO_TX_BU_ 261 : ACM,APIM,APIM_CDC,APIM_CIM,APIM_CISM;
BO_TX_BU_ 290 : APIM,APIM_CDC,APIM_CIM,APIM_CISM;
BO_TX_BU_ 298 : APIM,APIM_CDC;
BO_TX_BU_ 317 : APIM_CIM,APIM_CISM;
BO_TX_BU_ 334 : APIM_CDC,APIM_CIM;
BO_TX_BU_ 383 : APIM_CDC,APIM_CIM;
BO_TX_BU_ 391 : ACM,APIM_CIM,APIM_CISM;
BO_TX_BU_ 395 : APIM_CDC,APIM_CIM,IPC;
BO_TX_BU_ 400 : APIM_CDC,IPC;
BO_TX_BU_ 401 : APIM,APIM_CDC,APIM_CIM,APIM_CISM;
BO_TX_BU_ 402 : APIM,APIM_CDC,APIM_CIM,APIM_CISM;
BO_TX_BU_ 403 : APIM_CDC,IPC;
BO_TX_BU_ 404 : APIM,APIM_CIM,APIM_CISM;
BO_TX_BU_ 405 : APIM_CDC,IPC;
BO_TX_BU_ 410 : APIM_CDC,IPC;
BO_TX_BU_ 412 : APIM,APIM_CDC;
BO_TX_BU_ 413 : APIM,APIM_CDC,APIM_CIM,APIM_CISM;
BO_TX_BU_ 414 : ACM,APIM,APIM_CIM,APIM_CISM;
BO_TX_BU_ 419 : APIM,APIM_CISM;
BO_TX_BU_ 454 : APIM_CDC,APIM_CIM;
BO_TX_BU_ 467 : APIM,APIM_CDC,APIM_CIM,APIM_CISM;
BO_TX_BU_ 470 : APIM,APIM_CDC,APIM_CIM,APIM_CISM;
BO_TX_BU_ 473 : APIM,APIM_CDC,APIM_CISM;
BO_TX_BU_ 474 : APIM,APIM_CDC,APIM_CIM,APIM_CISM;
BO_TX_BU_ 476 : APIM,APIM_CDC;
BO_TX_BU_ 477 : APIM,APIM_CDC,APIM_CIM,APIM_CISM;
BO_TX_BU_ 479 : APIM,APIM_CDC,APIM_CIM,APIM_CISM;
BO_TX_BU_ 482 : APIM,APIM_CDC,APIM_CISM;
BO_TX_BU_ 486 : ACM,APIM_CIM,APIM_CISM;
BO_TX_BU_ 487 : ACM,APIM_CISM;
BO_TX_BU_ 489 : ACM,APIM_CIM,APIM_CISM;
BO_TX_BU_ 490 : APIM,APIM_CDC;
BO_TX_BU_ 493 : APIM,APIM_CDC;
BO_TX_BU_ 494 : APIM_CDC,IPC;
BO_TX_BU_ 498 : APIM_CDC,IPC;
BO_TX_BU_ 500 : APIM,APIM_CDC;
BO_TX_BU_ 501 : APIM,APIM_CDC;
BO_TX_BU_ 502 : APIM,APIM_CDC;
BO_TX_BU_ 503 : APIM,APIM_CDC;
BO_TX_BU_ 504 : APIM_CDC,IPC;
BO_TX_BU_ 505 : APIM_CDC,IPC;
BO_TX_BU_ 506 : APIM_CDC,IPC;
BO_TX_BU_ 507 : APIM_CDC,IPC;
BO_TX_BU_ 508 : APIM_CDC,IPC;
BO_TX_BU_ 511 : APIM,APIM_CDC;
BO_TX_BU_ 529 : APIM,APIM_CDC,APIM_CIM,APIM_CISM;
BO_TX_BU_ 530 : APIM,APIM_CDC;
CM_ BO_ 382 "ECM, PCM Gas Only msg";
CM_ BO_ 401 "APIM Tx";
CM_ BO_ 402 "FCDIM,APIM Tx";
CM_ BO_ 486 "ACM Tx";
BA_DEF_ BO_  "E2EDataId" INT 0 65535;
BA_DEF_ BO_  "E2EDataLength" INT 0 512;
BA_DEF_ BO_  "E2EProfile" STRING ;
BA_DEF_ BO_  "GenMsgRoutingTimeoutTime" INT 0 5000;
BA_DEF_ BO_  "MessageGateway" ENUM  "No","Yes";
BA_DEF_ BO_  "VFrameFormat" ENUM  "StandardCAN","ExtendedCAN","reserved","reserved","reserved","reserved","reserved","reserved","reserved","reserved","reserved","reserved","reserved","reserved","StandardCAN_FD","ExtendedCAN_FD";
BA_DEF_ SG_  "ECGUsedRxSignal" ENUM  "No","Yes";
BA_DEF_ SG_  "ECGUsedTxSignal" ENUM  "No","Yes";
BA_DEF_ SG_  "GenSigInactiveValue" INT 0 100000;
BA_DEF_ SG_  "GenSigSendType" ENUM  "Cyclic","OnWrite","vector_leerstring","OnChange","vector_leerstring","IfActive","vector_leerstring","NoSigSendType";
BA_DEF_ BO_  "NetworkInitialization" ENUM  "No","Yes";
BA_DEF_ SG_  "GenSigStartValue" HEX 0 268435455;
BA_DEF_ BO_  "GenMsgStartDelayTime" INT 0 10000;
BA_DEF_ SG_  "WakeupSignal" ENUM  "No","Yes";
BA_DEF_ BO_  "GenMsgNrOfRepetition" INT 0 100;
BA_DEF_ BO_  "GenMsgDelayTime" INT 0 1000;
BA_DEF_ BO_  "GenMsgCycleTime" INT 0 100000;
BA_DEF_ BO_  "GenMsgSendType" ENUM  "FixedPeriodic","Event","EnabledPeriodic","NotUsed","NotUsed","EventPeriodic","NotUsed","NotUsed","NoMsgSendType";
BA_DEF_ BO_  "FrameRouting" STRING ;
BA_DEF_ BO_  "TpTxIndex" INT 0 536870911;
BA_DEF_ BO_  "OvtpPushApplication" ENUM  "FALSE","TRUE";
BA_DEF_ BO_  "SCP_FreshnessValueLength" INT 0 512;
BA_DEF_ BO_  "SCP_FreshnessValueTxLength" INT 0 512;
BA_DEF_ BO_  "SCP_AuthInfoTxLength" INT 0 512;
BA_DEF_ BO_  "NmAsrMessage" ENUM  "No","Yes";
BA_DEF_ BO_  "DiagState" ENUM  "No","Yes";
BA_DEF_ BO_  "DiagRequest" ENUM  "No","Yes";
BA_DEF_ BO_  "DiagResponse" ENUM  "No","Yes";
BA_DEF_ BO_  "GenMsgILSupport" ENUM  "No","Yes";
BA_DEF_ SG_  "SystemSignalLongSymbol" STRING ;
BA_DEF_ BO_  "SystemMessageLongSymbol" STRING ;
BA_DEF_DEF_  "E2EDataId" 1;
BA_DEF_DEF_  "E2EDataLength" 0;
BA_DEF_DEF_  "E2EProfile" "";
BA_DEF_DEF_  "GenMsgRoutingTimeoutTime" 0;
BA_DEF_DEF_  "MessageGateway" "No";
BA_DEF_DEF_  "VFrameFormat" "StandardCAN";
BA_DEF_DEF_  "ECGUsedRxSignal" "No";
BA_DEF_DEF_  "ECGUsedTxSignal" "No";
BA_DEF_DEF_  "GenSigInactiveValue" 0;
BA_DEF_DEF_  "GenSigSendType" "NoSigSendType";
BA_DEF_DEF_  "NetworkInitialization" "Yes";
BA_DEF_DEF_  "GenSigStartValue" 0;
BA_DEF_DEF_  "GenMsgStartDelayTime" 0;
BA_DEF_DEF_  "WakeupSignal" "No";
BA_DEF_DEF_  "GenMsgNrOfRepetition" 1;
BA_DEF_DEF_  "GenMsgDelayTime" 20;
BA_DEF_DEF_  "GenMsgCycleTime" 0;
BA_DEF_DEF_  "GenMsgSendType" "NoMsgSendType";
BA_DEF_DEF_  "FrameRouting" "";
BA_DEF_DEF_  "TpTxIndex" 0;
BA_DEF_DEF_  "OvtpPushApplication" "FALSE";
BA_DEF_DEF_  "SCP_FreshnessValueLength" 64;
BA_DEF_DEF_  "SCP_FreshnessValueTxLength" 11;
BA_DEF_DEF_  "SCP_AuthInfoTxLength" 53;
BA_DEF_DEF_  "NmAsrMessage" "No";
BA_DEF_DEF_  "DiagState" "No";
BA_DEF_DEF_  "DiagRequest" "No";
BA_DEF_DEF_  "DiagResponse" "No";
BA_DEF_DEF_  "GenMsgILSupport" "Yes";
BA_DEF_DEF_  "SystemSignalLongSymbol" "";
BA_DEF_DEF_  "SystemMessageLongSymbol" "";
BA_ "GenMsgSendType" BO_ 261 1;
BA_ "GenMsgSendType" BO_ 262 5;
BA_ "GenMsgCycleTime" BO_ 262 1000;
BA_ "GenMsgSendType" BO_ 266 5;
BA_ "GenMsgCycleTime" BO_ 266 1000;
BA_ "GenMsgDelayTime" BO_ 267 0;
BA_ "FrameRouting" BO_ 267 "FD1_CAN,0x10B;";
BA_ "GenMsgSendType" BO_ 270 5;
BA_ "GenMsgDelayTime" BO_ 270 0;
BA_ "GenMsgCycleTime" BO_ 270 1000;
BA_ "GenMsgSendType" BO_ 282 5;
BA_ "GenMsgCycleTime" BO_ 282 1000;
BA_ "GenMsgSendType" BO_ 290 1;
BA_ "NetworkInitialization" BO_ 291 0;
BA_ "GenMsgSendType" BO_ 291 1;
BA_ "FrameRouting" BO_ 293 "FD3_CAN,0x125;";
BA_ "GenMsgSendType" BO_ 298 5;
BA_ "GenMsgDelayTime" BO_ 298 0;
BA_ "GenMsgCycleTime" BO_ 298 1000;
BA_ "FrameRouting" BO_ 300 "FD1_CAN,0x12C;";
BA_ "FrameRouting" BO_ 303 "FD1_CAN,0x12F;";
BA_ "E2EProfile" BO_ 303 "P01";
BA_ "E2EDataLength" BO_ 303 64;
BA_ "E2EDataId" BO_ 303 303;
BA_ "GenMsgDelayTime" BO_ 307 10;
BA_ "FrameRouting" BO_ 307 "FD1_CAN,0x133;";
BA_ "FrameRouting" BO_ 310 "FD2_CAN,0x136;";
BA_ "GenMsgSendType" BO_ 317 0;
BA_ "GenMsgCycleTime" BO_ 317 1000;
BA_ "FrameRouting" BO_ 330 "FD1_CAN,0x14A;";
BA_ "FrameRouting" BO_ 331 "FD1_CAN,0x14B;";
BA_ "FrameRouting" BO_ 332 "FD1_CAN,0x14C;";
BA_ "FrameRouting" BO_ 333 "FD1_CAN,0x14D;";
BA_ "GenMsgSendType" BO_ 334 1;
BA_ "E2EProfile" BO_ 334 "P01";
BA_ "E2EDataLength" BO_ 334 64;
BA_ "E2EDataId" BO_ 334 334;
BA_ "FrameRouting" BO_ 342 "FD1_CAN,0x156;";
BA_ "FrameRouting" BO_ 355 "FD1_CAN,0x163;";
BA_ "GenMsgRoutingTimeoutTime" BO_ 357 60;
BA_ "FrameRouting" BO_ 357 "FD1_CAN,0x165;";
BA_ "FrameRouting" BO_ 358 "FD1_CAN,0x166;";
BA_ "GenMsgDelayTime" BO_ 359 0;
BA_ "FrameRouting" BO_ 359 "FD1_CAN,0x167;";
BA_ "FrameRouting" BO_ 360 "FD3_CAN,0x168;";
BA_ "GenMsgSendType" BO_ 366 5;
BA_ "GenMsgCycleTime" BO_ 366 1000;
BA_ "GenMsgSendType" BO_ 367 5;
BA_ "GenMsgCycleTime" BO_ 367 1000;
BA_ "GenMsgDelayTime" BO_ 369 15;
BA_ "FrameRouting" BO_ 369 "FD1_CAN,0x171;";
BA_ "GenMsgDelayTime" BO_ 373 10;
BA_ "FrameRouting" BO_ 373 "FD1_CAN,0x175;";
BA_ "FrameRouting" BO_ 374 "FD1_CAN,0x176;";
BA_ "FrameRouting" BO_ 376 "FD1_CAN,0x178;";
BA_ "FrameRouting" BO_ 377 "FD1_CAN,0x179;";
BA_ "FrameRouting" BO_ 380 "FD1_CAN,0x17C;";
BA_ "FrameRouting" BO_ 381 "FD1_CAN,0x17D;";
BA_ "FrameRouting" BO_ 382 "FD1_CAN,0x17E;";
BA_ "GenMsgSendType" BO_ 383 5;
BA_ "GenMsgCycleTime" BO_ 383 100;
BA_ "E2EProfile" BO_ 383 "P01";
BA_ "E2EDataLength" BO_ 383 64;
BA_ "E2EDataId" BO_ 383 383;
BA_ "FrameRouting" BO_ 385 "FD1_CAN,0x181;";
BA_ "GenMsgDelayTime" BO_ 386 0;
BA_ "FrameRouting" BO_ 386 "FD1_CAN,0x182;";
BA_ "FrameRouting" BO_ 387 "FD1_CAN,0x183;";
BA_ "FrameRouting" BO_ 389 "FD1_CAN,0x185;";
BA_ "GenMsgSendType" BO_ 391 1;
BA_ "FrameRouting" BO_ 394 "FD1_CAN,0x18A;FD3_CAN,0x18A;";
BA_ "GenMsgSendType" BO_ 395 5;
BA_ "GenMsgCycleTime" BO_ 395 1000;
BA_ "NetworkInitialization" BO_ 400 0;
BA_ "GenMsgSendType" BO_ 400 1;
BA_ "GenMsgSendType" BO_ 401 1;
BA_ "GenMsgSendType" BO_ 402 5;
BA_ "GenMsgCycleTime" BO_ 402 1000;
BA_ "NetworkInitialization" BO_ 403 0;
BA_ "GenMsgSendType" BO_ 403 1;
BA_ "GenMsgSendType" BO_ 404 1;
BA_ "NetworkInitialization" BO_ 405 0;
BA_ "GenMsgSendType" BO_ 405 1;
BA_ "GenMsgSendType" BO_ 410 5;
BA_ "GenMsgCycleTime" BO_ 410 1000;
BA_ "GenMsgSendType" BO_ 412 1;
BA_ "GenMsgSendType" BO_ 413 1;
BA_ "GenMsgSendType" BO_ 414 1;
BA_ "GenMsgSendType" BO_ 415 1;
BA_ "GenMsgSendType" BO_ 419 1;
BA_ "NetworkInitialization" BO_ 422 0;
BA_ "GenMsgSendType" BO_ 422 1;
BA_ "GenMsgDelayTime" BO_ 436 0;
BA_ "GenMsgDelayTime" BO_ 437 0;
BA_ "GenMsgDelayTime" BO_ 438 0;
BA_ "GenMsgDelayTime" BO_ 439 0;
BA_ "GenMsgDelayTime" BO_ 440 0;
BA_ "GenMsgDelayTime" BO_ 441 0;
BA_ "FrameRouting" BO_ 448 "FD3_CAN,0x1C0;";
BA_ "FrameRouting" BO_ 450 "FD3_CAN,0x1C2;";
BA_ "FrameRouting" BO_ 452 "FD3_CAN,0x1C4;";
BA_ "FrameRouting" BO_ 453 "FD3_CAN,0x1C5;";
BA_ "GenMsgSendType" BO_ 454 5;
BA_ "GenMsgCycleTime" BO_ 454 1000;
BA_ "GenMsgSendType" BO_ 455 5;
BA_ "GenMsgCycleTime" BO_ 455 1000;
BA_ "GenMsgSendType" BO_ 462 5;
BA_ "GenMsgCycleTime" BO_ 462 1000;
BA_ "GenMsgSendType" BO_ 464 1;
BA_ "GenMsgSendType" BO_ 467 5;
BA_ "GenMsgCycleTime" BO_ 467 1000;
BA_ "GenMsgSendType" BO_ 470 1;
BA_ "GenMsgDelayTime" BO_ 471 0;
BA_ "GenMsgDelayTime" BO_ 472 0;
BA_ "GenMsgSendType" BO_ 473 1;
BA_ "GenMsgSendType" BO_ 474 1;
BA_ "GenMsgSendType" BO_ 476 1;
BA_ "GenMsgSendType" BO_ 477 1;
BA_ "GenMsgDelayTime" BO_ 478 0;
BA_ "FrameRouting" BO_ 478 "FD2_CAN,0x1DE;";
BA_ "GenMsgSendType" BO_ 479 1;
BA_ "FrameRouting" BO_ 481 "FD1_CAN,0x1E1;";
BA_ "GenMsgSendType" BO_ 482 5;
BA_ "GenMsgCycleTime" BO_ 482 1000;
BA_ "GenMsgSendType" BO_ 486 1;
BA_ "GenMsgSendType" BO_ 487 1;
BA_ "GenMsgSendType" BO_ 488 5;
BA_ "GenMsgCycleTime" BO_ 488 1000;
BA_ "GenMsgSendType" BO_ 489 1;
BA_ "GenMsgSendType" BO_ 490 1;
BA_ "GenMsgSendType" BO_ 493 1;
BA_ "NetworkInitialization" BO_ 494 0;
BA_ "GenMsgSendType" BO_ 494 1;
BA_ "GenMsgSendType" BO_ 497 5;
BA_ "GenMsgCycleTime" BO_ 497 1000;
BA_ "NetworkInitialization" BO_ 498 0;
BA_ "GenMsgSendType" BO_ 498 1;
BA_ "GenMsgSendType" BO_ 500 1;
BA_ "GenMsgSendType" BO_ 501 1;
BA_ "GenMsgSendType" BO_ 502 1;
BA_ "GenMsgSendType" BO_ 503 1;
BA_ "NetworkInitialization" BO_ 504 0;
BA_ "GenMsgSendType" BO_ 504 1;
BA_ "NetworkInitialization" BO_ 505 0;
BA_ "GenMsgSendType" BO_ 505 1;
BA_ "NetworkInitialization" BO_ 506 0;
BA_ "GenMsgSendType" BO_ 506 1;
BA_ "NetworkInitialization" BO_ 507 0;
BA_ "GenMsgSendType" BO_ 507 1;
BA_ "NetworkInitialization" BO_ 508 0;
BA_ "GenMsgSendType" BO_ 508 1;
BA_ "GenMsgSendType" BO_ 509 5;
BA_ "GenMsgCycleTime" BO_ 509 500;
BA_ "GenMsgSendType" BO_ 511 1;
BA_ "FrameRouting" BO_ 512 "FD1_CAN,0x200;";
BA_ "FrameRouting" BO_ 513 "FD1_CAN,0x201;";
BA_ "GenMsgDelayTime" BO_ 514 10;
BA_ "FrameRouting" BO_ 514 "FD1_CAN,0x202;";
BA_ "FrameRouting" BO_ 515 "FD1_CAN,0x203;";
BA_ "GenMsgDelayTime" BO_ 516 0;
BA_ "FrameRouting" BO_ 516 "FD1_CAN,0x204;";
BA_ "FrameRouting" BO_ 523 "FD1_CAN,0x20B;";
BA_ "FrameRouting" BO_ 528 "FD1_CAN,0x210;";
BA_ "GenMsgSendType" BO_ 529 5;
BA_ "GenMsgCycleTime" BO_ 529 1000;
BA_ "GenMsgSendType" BO_ 530 1;
BA_ "GenSigSendType" SG_ 261 OffPeakTimeSetType_Rq 3;
BA_ "GenSigSendType" SG_ 261 OffPeakTimeSetHR_Rq 3;
BA_ "GenSigSendType" SG_ 261 OffPeakTimeSetMin_Rq 3;
BA_ "GenSigSendType" SG_ 261 NextUsageTimeToggle_Rq 3;
BA_ "GenSigSendType" SG_ 261 LongTermParking_Rq 3;
BA_ "GenSigSendType" SG_ 261 FactoryReset_Rq 3;
BA_ "ECGUsedRxSignal" SG_ 261 FactoryReset_Rq 1;
BA_ "GenSigSendType" SG_ 261 TCU_ESN_D_Rq 3;
BA_ "GenSigSendType" SG_ 261 StopStrtDrvMde_B_RqBtn3 3;
BA_ "GenSigSendType" SG_ 261 CbnCmrtPrefLstNmItm_Rq 3;
BA_ "GenSigSendType" SG_ 261 CbnCmrtPrefListIndx_Rq 3;
BA_ "GenSigSendType" SG_ 261 AudioToneTouch_D_Rq 3;
BA_ "GenSigSendType" SG_ 261 ModemReset_D_Rq 3;
BA_ "ECGUsedRxSignal" SG_ 261 ModemReset_D_Rq 1;
BA_ "GenSigStartValue" SG_ 261 ChrgStatDsply_D_Rq 1;
BA_ "GenSigSendType" SG_ 261 ChrgStatDsply_D_Rq 3;
BA_ "GenSigSendType" SG_ 261 AudioToneTouchX_D_Rq 3;
BA_ "GenSigSendType" SG_ 261 AudioToneTouchY_D_Rq 3;
BA_ "GenSigSendType" SG_ 262 OnbChrgGlblAcMx_I_Rq 3;
BA_ "GenSigSendType" SG_ 262 OnbChrgSetUpdate_B_Rq 3;
BA_ "ECGUsedRxSignal" SG_ 262 OnbChrgSetUpdate_B_Rq 1;
BA_ "GenSigStartValue" SG_ 262 OnbChrgGlblDcMx_Pw_Rq 127;
BA_ "GenSigSendType" SG_ 262 OnbChrgGlblDcMx_Pw_Rq 3;
BA_ "GenSigStartValue" SG_ 262 OnbChrgSocAcMx_Pc_Rq 100;
BA_ "GenSigSendType" SG_ 262 OnbChrgSocAcMx_Pc_Rq 3;
BA_ "GenSigStartValue" SG_ 262 OnbChrgSocDcMx_Pc_Rq 100;
BA_ "GenSigSendType" SG_ 262 OnbChrgSocDcMx_Pc_Rq 3;
BA_ "ECGUsedTxSignal" SG_ 266 UceStrtYr_No_Actl 1;
BA_ "GenSigSendType" SG_ 266 OfbChrgSetUpdate_B_Rq 3;
BA_ "ECGUsedTxSignal" SG_ 266 OfbChrgSetUpdate_B_Rq 1;
BA_ "ECGUsedTxSignal" SG_ 266 UceStrtHr_T_Actl 1;
BA_ "GenSigStartValue" SG_ 266 UceEndDay_No_Actl 31;
BA_ "ECGUsedTxSignal" SG_ 266 UceEndDay_No_Actl 1;
BA_ "GenSigStartValue" SG_ 266 UceEndMnth_No_Actl 15;
BA_ "ECGUsedTxSignal" SG_ 266 UceEndMnth_No_Actl 1;
BA_ "ECGUsedTxSignal" SG_ 266 UceEndYr_No_Actl 1;
BA_ "ECGUsedTxSignal" SG_ 266 UceEndMin_T_Actl 1;
BA_ "ECGUsedTxSignal" SG_ 266 UceEndHr_T_Actl 1;
BA_ "GenSigStartValue" SG_ 270 UceStrtDay_No_Actl 31;
BA_ "GenSigSendType" SG_ 270 UceStrtDay_No_Actl 3;
BA_ "ECGUsedTxSignal" SG_ 270 UceStrtDay_No_Actl 1;
BA_ "GenSigSendType" SG_ 270 UceStrtMin_T_Actl 3;
BA_ "ECGUsedTxSignal" SG_ 270 UceStrtMin_T_Actl 1;
BA_ "GenSigStartValue" SG_ 270 UceStrtMnth_No_Actl 15;
BA_ "GenSigSendType" SG_ 270 UceStrtMnth_No_Actl 3;
BA_ "ECGUsedTxSignal" SG_ 270 UceStrtMnth_No_Actl 1;
BA_ "GenSigSendType" SG_ 282 HudPersFeat_No_Rq 3;
BA_ "ECGUsedTxSignal" SG_ 282 HudPersFeat_No_Rq 1;
BA_ "GenSigSendType" SG_ 282 HudPersFeatVal_No_Rq 3;
BA_ "ECGUsedTxSignal" SG_ 282 HudPersFeatVal_No_Rq 1;
BA_ "GenSigSendType" SG_ 282 HudPersSrvc_D_Rq 3;
BA_ "ECGUsedTxSignal" SG_ 282 HudPersSrvc_D_Rq 1;
BA_ "GenSigStartValue" SG_ 282 HudPersIndx_No_Rq 4;
BA_ "GenSigSendType" SG_ 282 HudPersIndx_No_Rq 3;
BA_ "ECGUsedTxSignal" SG_ 282 HudPersIndx_No_Rq 1;
BA_ "GenSigSendType" SG_ 282 HudPersSrvcId_No_Rq 3;
BA_ "ECGUsedTxSignal" SG_ 282 HudPersSrvcId_No_Rq 1;
BA_ "GenSigSendType" SG_ 290 WifiHtsptMacAddr_B_Rq 3;
BA_ "GenSigSendType" SG_ 290 WifiHtsptEnbl_D_Rq 3;
BA_ "GenSigSendType" SG_ 290 WifiDevcList_D_Rq 3;
BA_ "GenSigSendType" SG_ 290 WifiDataUsage_D_Rq 3;
BA_ "GenSigSendType" SG_ 290 WifiCarrierInfo_B_Rq 3;
BA_ "GenSigStartValue" SG_ 290 WifiDevcListIndx_No_Rq 22;
BA_ "GenSigSendType" SG_ 290 WifiHtsptScrty_D_Rq 3;
BA_ "GenSigSendType" SG_ 290 WifiHtsptFqBand_D_Rq 3;
BA_ "GenSigSendType" SG_ 290 WifiHtsptTrial_D_RqDrv 3;
BA_ "GenSigSendType" SG_ 290 WifiRemoveDevc_D_Rq 3;
BA_ "GenSigSendType" SG_ 290 WifiHtsptVisbl_D_Rq 3;
BA_ "GenSigStartValue" SG_ 290 WifiRemoveIndx_No_Rq 20;
BA_ "GenSigSendType" SG_ 291 LangUpdate_Rsp 3;
BA_ "GenSigSendType" SG_ 298 SdarsSrvcId_No2_Actl2 3;
BA_ "GenSigStartValue" SG_ 303 CanMsg12F_UNUSED_1bit_1 1;
BA_ "GenSigInactiveValue" SG_ 303 CanMsg12F_UNUSED_1bit_1 1;
BA_ "WakeupSignal" SG_ 303 DrStatHood_D2_Actl 1;
BA_ "GenSigStartValue" SG_ 303 CanMsg12F_UNUSED_2bit_1 3;
BA_ "GenSigInactiveValue" SG_ 303 CanMsg12F_UNUSED_2bit_1 3;
BA_ "GenSigStartValue" SG_ 303 CanMsg12F_UNUSED_3bit_1 7;
BA_ "GenSigStartValue" SG_ 303 CanMsg12F_UNUSED_2bit_2 3;
BA_ "GenSigInactiveValue" SG_ 303 CanMsg12F_UNUSED_2bit_2 3;
BA_ "GenSigStartValue" SG_ 303 CanMsg12F_UNUSED_2bit_3 3;
BA_ "GenSigInactiveValue" SG_ 303 CanMsg12F_UNUSED_2bit_3 3;
BA_ "GenSigStartValue" SG_ 303 CanMsg12F_UNUSED_2bit_4 3;
BA_ "GenSigInactiveValue" SG_ 303 CanMsg12F_UNUSED_2bit_4 3;
BA_ "GenSigStartValue" SG_ 303 CanMsg12F_UNUSED_8bit_1 255;
BA_ "GenSigInactiveValue" SG_ 303 CanMsg12F_UNUSED_8bit_1 255;
BA_ "GenSigStartValue" SG_ 307 MobcVLimPrim_D_Stat 3;
BA_ "GenSigStartValue" SG_ 307 GearLvrPrim_D_Rq 7;
BA_ "GenSigStartValue" SG_ 307 PrplWhlTotPrim1_Tq_Rq 32768;
BA_ "GenSigStartValue" SG_ 310 SecondRowBucklePsngrMid2 1;
BA_ "GenSigStartValue" SG_ 310 SecondRowBuckleDrvMid2 1;
BA_ "GenSigStartValue" SG_ 310 ThirdRowBucklePsngrMid 1;
BA_ "GenSigStartValue" SG_ 310 ThirdRowBuckleDrvMid 1;
BA_ "GenSigStartValue" SG_ 310 FourthRowBucklePsngrMid 1;
BA_ "GenSigStartValue" SG_ 310 FourthRowBuckleDrvMid 1;
BA_ "GenSigStartValue" SG_ 310 FifthRowBuckleDrvMid 1;
BA_ "GenSigStartValue" SG_ 310 FifthRowBuckleDrv 1;
BA_ "GenSigStartValue" SG_ 310 FifthRowBucklePsngr 1;
BA_ "GenSigStartValue" SG_ 310 FifthRowBuckleMid 1;
BA_ "GenSigStartValue" SG_ 310 FifthRowBucklePsngrMid 1;
BA_ "ECGUsedRxSignal" SG_ 317 VehPtch_An_Actl 1;
BA_ "GenSigStartValue" SG_ 331 TrnAout2_W_ActlUnfilt 65534;
BA_ "GenSigStartValue" SG_ 334 CanMsg14E_UNUSED_2bit_2 3;
BA_ "GenSigInactiveValue" SG_ 334 CanMsg14E_UNUSED_2bit_2 3;
BA_ "GenSigStartValue" SG_ 334 CanMsg14E_UNUSED_2bit_1 3;
BA_ "GenSigInactiveValue" SG_ 334 CanMsg14E_UNUSED_2bit_1 3;
BA_ "GenSigStartValue" SG_ 334 CanMsg14E_UNUSED_2bit_3 3;
BA_ "GenSigInactiveValue" SG_ 334 CanMsg14E_UNUSED_2bit_3 3;
BA_ "WakeupSignal" SG_ 334 PdlAdj_D_Rq_1A 1;
BA_ "GenSigSendType" SG_ 334 PdlAdj_D_Rq_1A 3;
BA_ "WakeupSignal" SG_ 334 StewPosAdjTlt_D_Rq_1A 1;
BA_ "GenSigSendType" SG_ 334 StewPosAdjTlt_D_Rq_1A 3;
BA_ "WakeupSignal" SG_ 334 StewPosAdjTel_D_Rq_1A 1;
BA_ "GenSigSendType" SG_ 334 StewPosAdjTel_D_Rq_1A 3;
BA_ "GenSigStartValue" SG_ 334 CanMsg14E_UNUSED_8bit_1 255;
BA_ "GenSigInactiveValue" SG_ 334 CanMsg14E_UNUSED_8bit_1 255;
BA_ "GenSigStartValue" SG_ 334 CanMsg14E_UNUSED_8bit_2 255;
BA_ "GenSigInactiveValue" SG_ 334 CanMsg14E_UNUSED_8bit_2 255;
BA_ "GenSigStartValue" SG_ 334 CanMsg14E_UNUSED_8bit_3 255;
BA_ "GenSigInactiveValue" SG_ 334 CanMsg14E_UNUSED_8bit_3 255;
BA_ "GenSigStartValue" SG_ 334 CanMsg14E_UNUSED_8bit_4 255;
BA_ "GenSigInactiveValue" SG_ 334 CanMsg14E_UNUSED_8bit_4 255;
BA_ "GenSigStartValue" SG_ 334 CanMsg14E_UNUSED_8bit_5 255;
BA_ "GenSigInactiveValue" SG_ 334 CanMsg14E_UNUSED_8bit_5 255;
BA_ "GenSigStartValue" SG_ 357 BpedDrvAppl_D_Actl 1;
BA_ "GenSigStartValue" SG_ 357 BPedDrvAppl_D_Qf 1;
BA_ "GenSigStartValue" SG_ 359 PlgActvArb_B_Actl 1;
BA_ "WakeupSignal" SG_ 360 PrkBrkButtnDStat_No_Cs 1;
BA_ "WakeupSignal" SG_ 360 PrkBrkButtnDStat_No_Cnt 1;
BA_ "WakeupSignal" SG_ 360 PrkBrkButtn_D_Stat 1;
BA_ "GenSigSendType" SG_ 366 AprTvfTripId1_No_Actl 3;
BA_ "GenSigSendType" SG_ 367 AuthctnInfoId_No_Actl 3;
BA_ "ECGUsedTxSignal" SG_ 367 AuthctnInfoId_No_Actl 1;
BA_ "GenSigSendType" SG_ 367 AuthctnInfo_D_Stat 3;
BA_ "ECGUsedTxSignal" SG_ 367 AuthctnInfo_D_Stat 1;
BA_ "GenSigSendType" SG_ 367 AuthctnInfoIndx_No_Actl 3;
BA_ "ECGUsedTxSignal" SG_ 367 AuthctnInfoIndx_No_Actl 1;
BA_ "GenSigSendType" SG_ 367 AuthctnStat_D_Stat 3;
BA_ "ECGUsedTxSignal" SG_ 367 AuthctnStat_D_Stat 1;
BA_ "GenSigSendType" SG_ 367 AuthctnInfoLoc_D_Stat 3;
BA_ "ECGUsedTxSignal" SG_ 367 AuthctnInfoLoc_D_Stat 1;
BA_ "GenSigSendType" SG_ 367 AuthctnStatChnl_D_Stat 3;
BA_ "ECGUsedTxSignal" SG_ 367 AuthctnStatChnl_D_Stat 1;
BA_ "GenSigSendType" SG_ 367 AuthctnStatRtry_No_Actl 3;
BA_ "ECGUsedTxSignal" SG_ 367 AuthctnStatRtry_No_Actl 1;
BA_ "GenSigSendType" SG_ 367 AuthctnStatId_No_Actl 3;
BA_ "ECGUsedTxSignal" SG_ 367 AuthctnStatId_No_Actl 1;
BA_ "GenSigSendType" SG_ 367 ApnlPsswrdId_No_Actl 3;
BA_ "ECGUsedTxSignal" SG_ 367 ApnlPsswrdId_No_Actl 1;
BA_ "GenSigSendType" SG_ 367 ApnlPsswrdType_D_Stat 3;
BA_ "ECGUsedTxSignal" SG_ 367 ApnlPsswrdType_D_Stat 1;
BA_ "GenSigSendType" SG_ 367 AuthctnStatIndx_No_Actl 3;
BA_ "ECGUsedTxSignal" SG_ 367 AuthctnStatIndx_No_Actl 1;
BA_ "GenSigSendType" SG_ 367 ApnlPsswrdIndx_No_Actl 3;
BA_ "ECGUsedTxSignal" SG_ 367 ApnlPsswrdIndx_No_Actl 1;
BA_ "GenSigSendType" SG_ 367 HashId_No_Actl 3;
BA_ "ECGUsedTxSignal" SG_ 367 HashId_No_Actl 1;
BA_ "GenSigSendType" SG_ 367 HashIndx_D_Stat 3;
BA_ "ECGUsedTxSignal" SG_ 367 HashIndx_D_Stat 1;
BA_ "GenSigSendType" SG_ 367 HashIndx_No_Actl 3;
BA_ "ECGUsedTxSignal" SG_ 367 HashIndx_No_Actl 1;
BA_ "GenSigSendType" SG_ 367 HashSalt1_No_Res 3;
BA_ "ECGUsedTxSignal" SG_ 367 HashSalt1_No_Res 1;
BA_ "GenSigSendType" SG_ 367 HashSalt2_No_Res 3;
BA_ "ECGUsedTxSignal" SG_ 367 HashSalt2_No_Res 1;
BA_ "GenSigSendType" SG_ 367 HashNonce1_No_Res 3;
BA_ "ECGUsedTxSignal" SG_ 367 HashNonce1_No_Res 1;
BA_ "GenSigSendType" SG_ 367 HashNonce2_No_Res 3;
BA_ "ECGUsedTxSignal" SG_ 367 HashNonce2_No_Res 1;
BA_ "WakeupSignal" SG_ 369 TrnIpcDsplyMde_D_Stat 1;
BA_ "GenSigStartValue" SG_ 369 TrnIpcDsplyGear_D_Actl 15;
BA_ "WakeupSignal" SG_ 369 TrnIpcDsplyMde_D_Actl 1;
BA_ "GenSigStartValue" SG_ 369 PrplWhlPrim_Tq_Cmd 2048;
BA_ "GenSigStartValue" SG_ 369 TrnIpcDsplyRng2_D_Actl 15;
BA_ "GenSigStartValue" SG_ 369 PrplWhlScnd_Tq_Cmd 2048;
BA_ "GenSigStartValue" SG_ 374 GearPos_D_Actl 15;
BA_ "GenSigStartValue" SG_ 374 GearPos_D_Trg 15;
BA_ "GenSigStartValue" SG_ 374 TrnRng_D_Rq 14;
BA_ "GenSigStartValue" SG_ 376 AirAmbTe_D_Qf 1;
BA_ "GenSigStartValue" SG_ 380 GrdAsstAllw_D_DsplyPt 1;
BA_ "WakeupSignal" SG_ 380 EngOilLvlWarn_D_Rq1 1;
BA_ "GenSigStartValue" SG_ 382 EngInnrClnt_Te_Actl 126;
BA_ "GenSigStartValue" SG_ 382 EngMnfldChrg_Te_Actl 126;
BA_ "GenSigSendType" SG_ 383 Mnu_No_Crc 3;
BA_ "GenSigSendType" SG_ 383 Mnu_No_Cnt 3;
BA_ "GenSigStartValue" SG_ 383 Mnu_UNUSED_1bit 1;
BA_ "GenSigInactiveValue" SG_ 383 Mnu_UNUSED_1bit 1;
BA_ "GenSigSendType" SG_ 383 DrChildLckPw_No_RqMnu 3;
BA_ "GenSigStartValue" SG_ 383 Mnu_UNUSED_5bit_1 31;
BA_ "GenSigInactiveValue" SG_ 383 Mnu_UNUSED_5bit_1 31;
BA_ "GenSigSendType" SG_ 383 HeadLghtCtl_D_RqMnu 3;
BA_ "GenSigStartValue" SG_ 383 Mnu_UNUSED_8bit_2 255;
BA_ "GenSigInactiveValue" SG_ 383 Mnu_UNUSED_8bit_2 255;
BA_ "GenSigStartValue" SG_ 383 Mnu_UNUSED_8bit_3 255;
BA_ "GenSigInactiveValue" SG_ 383 Mnu_UNUSED_8bit_3 255;
BA_ "GenSigStartValue" SG_ 383 Mnu_UNUSED_8bit_4 255;
BA_ "GenSigInactiveValue" SG_ 383 Mnu_UNUSED_8bit_4 255;
BA_ "GenSigStartValue" SG_ 383 Mnu_UNUSED_8bit_5 255;
BA_ "GenSigInactiveValue" SG_ 383 Mnu_UNUSED_8bit_5 255;
BA_ "GenSigStartValue" SG_ 383 Mnu_UNUSED_8bit_6 255;
BA_ "GenSigInactiveValue" SG_ 383 Mnu_UNUSED_8bit_6 255;
BA_ "GenSigStartValue" SG_ 385 ChrgGlblAc_I_Mx 255;
BA_ "GenSigStartValue" SG_ 385 ChrgGlblDc_Pw_Mx 127;
BA_ "GenSigStartValue" SG_ 385 ChrgGlblSocAc_Pc_Mx 127;
BA_ "GenSigStartValue" SG_ 385 ChrgGlblSocDc_Pc_Mx 127;
BA_ "GenSigStartValue" SG_ 385 ChrgrInMx_Pw_Rq 8191;
BA_ "GenSigStartValue" SG_ 386 Chrg_I_Dsply 511;
BA_ "GenSigStartValue" SG_ 386 Chrg_U_Dsply 1023;
BA_ "GenSigStartValue" SG_ 387 ChrgGlblRcmd_I_Dsply 255;
BA_ "GenSigStartValue" SG_ 387 ChrgGlblAcRcmd_Pc_Dspl 127;
BA_ "GenSigStartValue" SG_ 387 ChrgGlblDcRcmd_Pc_Dspl 127;
BA_ "GenSigStartValue" SG_ 387 ChrgGlblRcmd_Pw_Dsply 127;
BA_ "GenSigStartValue" SG_ 387 DcMx_Pw_Dsply 127;
BA_ "GenSigSendType" SG_ 391 ACU_CtrlChimeChan_Rq 3;
BA_ "GenSigStartValue" SG_ 394 AccTGap_D_Dsply 3;
BA_ "GenSigStartValue" SG_ 394 AccMemEnbl_B_RqDrv 1;
BA_ "GenSigSendType" SG_ 395 HudLed8On_B_Rq 3;
BA_ "GenSigSendType" SG_ 395 HudLed7On_B_Rq 3;
BA_ "GenSigSendType" SG_ 395 HudLed6On_B_Rq 3;
BA_ "GenSigSendType" SG_ 395 HudLed5On_B_Rq 3;
BA_ "GenSigSendType" SG_ 395 HudLed4On_B_Rq 3;
BA_ "GenSigSendType" SG_ 395 HudLed3On_B_Rq 3;
BA_ "GenSigSendType" SG_ 395 HudLed2On_B_Rq 3;
BA_ "GenSigSendType" SG_ 395 HudLed1On_B_Rq 3;
BA_ "GenSigSendType" SG_ 395 HudLed16On_B_Rq 3;
BA_ "GenSigSendType" SG_ 395 HudLed15On_B_Rq 3;
BA_ "GenSigSendType" SG_ 395 HudLed14On_B_Rq 3;
BA_ "GenSigSendType" SG_ 395 HudLed13On_B_Rq 3;
BA_ "GenSigSendType" SG_ 395 HudLed12On_B_Rq 3;
BA_ "GenSigSendType" SG_ 395 HudLed11On_B_Rq 3;
BA_ "GenSigSendType" SG_ 395 HudLed10On_B_Rq 3;
BA_ "GenSigSendType" SG_ 395 HudLed9On_B_Rq 3;
BA_ "GenSigSendType" SG_ 395 HudLed17On_B_Rq 3;
BA_ "GenSigStartValue" SG_ 395 HudShifPoint_N_Rq 30;
BA_ "GenSigSendType" SG_ 395 HudLedMde_D_Rq 3;
BA_ "GenSigSendType" SG_ 395 SelDrvMdeCnfm_D_Stat 3;
BA_ "GenSigSendType" SG_ 395 HudMde_D_Rq 3;
BA_ "GenSigSendType" SG_ 395 HudLed18On_B_Rq 3;
BA_ "GenSigSendType" SG_ 400 Mc_PerTUPresetArea_Rq 3;
BA_ "GenSigSendType" SG_ 400 Mc_SetCurrentStatOp_Rq 3;
BA_ "GenSigStartValue" SG_ 401 Disp_VehUntTripCoUsrSel 3;
BA_ "GenSigSendType" SG_ 401 Disp_VehUntTripCoUsrSel 3;
BA_ "GenSigStartValue" SG_ 401 Disp_VehUnitTempUsrSel 3;
BA_ "GenSigSendType" SG_ 401 Disp_VehUnitTempUsrSel 3;
BA_ "WakeupSignal" SG_ 401 Bezel_Beeps_Rq 1;
BA_ "GenSigSendType" SG_ 401 Bezel_Beeps_Rq 3;
BA_ "GenSigSendType" SG_ 401 Disp_LangSel_Rq 3;
BA_ "GenSigSendType" SG_ 401 Disp_LangSel2_Rq 3;
BA_ "GenSigSendType" SG_ 402 ApaMdeStat_D_RqDrv 3;
BA_ "GenSigSendType" SG_ 402 CamraViewSplit_B_Rq 3;
BA_ "GenSigSendType" SG_ 402 CamraOvrlStat_D_Rq 3;
BA_ "GenSigSendType" SG_ 402 DistanceBarSetting 3;
BA_ "GenSigSendType" SG_ 402 CamAutoTowbarZoom 3;
BA_ "GenSigSendType" SG_ 402 CamraOvrlDyn_D_Rq 3;
BA_ "GenSigSendType" SG_ 402 CamraFrntBttn_D_Stat3 3;
BA_ "GenSigSendType" SG_ 402 ApaSwtch_D_RqMnu 3;
BA_ "GenSigSendType" SG_ 402 PrkAidSwtch_D_RqMnu 3;
BA_ "GenSigSendType" SG_ 402 TrayTbleManOvrrd_B_Rq 3;
BA_ "GenSigSendType" SG_ 402 CamraZoomMan_D_Rq 3;
BA_ "GenSigSendType" SG_ 402 ApaSlotTrgt_D_RqDrv 3;
BA_ "GenSigSendType" SG_ 402 ApaFeat_D_RqDrv 3;
BA_ "GenSigSendType" SG_ 402 ApaFeatChange_B_RqDrv 3;
BA_ "GenSigSendType" SG_ 402 SodChimeEnbl_D_Rq 3;
BA_ "GenSigSendType" SG_ 402 ApaSlotAlrtSet_D_RqDrv 3;
BA_ "GenSigSendType" SG_ 403 DealerCall_B_Rq 3;
BA_ "GenSigSendType" SG_ 403 Mc_PhMicrophoneMute_Rq 3;
BA_ "GenSigSendType" SG_ 403 Mc_CancelCurrWaypt_Rq 3;
BA_ "GenSigSendType" SG_ 403 McLangSel2_Rq 3;
BA_ "GenSigSendType" SG_ 403 Mc_LangSel_Rq 3;
BA_ "GenSigSendType" SG_ 403 Mc_BTInCallOptions_Rq 3;
BA_ "GenSigSendType" SG_ 403 Mc_TextMessage_Rq 3;
BA_ "GenSigSendType" SG_ 403 Mc_CancelRoute_Rq 3;
BA_ "GenSigSendType" SG_ 403 Mc_RepeatGuidance_Rq 3;
BA_ "GenSigSendType" SG_ 404 Dsp_LangUpdate_Rsp 3;
BA_ "GenSigSendType" SG_ 405 LBC1_ActiveListID 3;
BA_ "GenSigSendType" SG_ 405 LBC1_ItemIndex 3;
BA_ "GenSigSendType" SG_ 405 LBC1_NbrOfItems 3;
BA_ "GenSigSendType" SG_ 405 LBC1_Opcode 3;
BA_ "GenSigSendType" SG_ 405 LBC1_SetListServ 3;
BA_ "GenSigSendType" SG_ 405 LBC1_StartItemInd 3;
BA_ "GenSigSendType" SG_ 410 DoNotDisturbOveride_St 3;
BA_ "GenSigSendType" SG_ 410 MyKey_e911Override_St 3;
BA_ "GenSigSendType" SG_ 412 LBC2_Opcode 3;
BA_ "GenSigSendType" SG_ 413 LBS1_ListStatus 3;
BA_ "GenSigSendType" SG_ 414 LBS2_ListStatus 3;
BA_ "GenSigSendType" SG_ 415 LBC3_Opcode 3;
BA_ "GenSigSendType" SG_ 419 MK_DNDRestrictConf_Rq 3;
BA_ "GenSigSendType" SG_ 419 MK_CreateMyKey_Rq 3;
BA_ "GenSigSendType" SG_ 419 MK_AudioLimitConfig_Rq 3;
BA_ "GenSigSendType" SG_ 419 MK_ACSRestrictConf_Rq 3;
BA_ "GenSigSendType" SG_ 419 MK_ResetAllUserKeys_Rq 3;
BA_ "GenSigSendType" SG_ 419 MK_MyKeySystemInfo_Rq 3;
BA_ "GenSigSendType" SG_ 419 MK_ESCRestrictConf_Rq 3;
BA_ "GenSigSendType" SG_ 419 MK_ECalRestrictConf_Rq 3;
BA_ "GenSigSendType" SG_ 419 MK_SpeedSetting_Rq 3;
BA_ "GenSigSendType" SG_ 422 MK_UserMyKeyCount_Rsp 3;
BA_ "GenSigSendType" SG_ 422 MK_CreateMyKey_Rsp 3;
BA_ "GenSigSendType" SG_ 422 MK_AdminMyKeyCount_Rsp 3;
BA_ "GenSigSendType" SG_ 422 MK_MyKeyDrivenKm_Rsp 3;
BA_ "GenSigSendType" SG_ 438 AprPsswrd1_No_Rq 3;
BA_ "ECGUsedRxSignal" SG_ 438 AprPsswrd1_No_Rq 1;
BA_ "ECGUsedRxSignal" SG_ 439 AprPsswrd2_No_Rq 1;
BA_ "GenSigSendType" SG_ 440 AprPsswrd3_No_Rq 3;
BA_ "ECGUsedRxSignal" SG_ 440 AprPsswrd3_No_Rq 1;
BA_ "GenSigSendType" SG_ 441 AprPsswrd4_No_Rq 3;
BA_ "ECGUsedRxSignal" SG_ 441 AprPsswrd4_No_Rq 1;
BA_ "ECGUsedRxSignal" SG_ 452 SeatCshnRclCtlPsn_D_Rq 1;
BA_ "ECGUsedRxSignal" SG_ 452 SeatSlidDrv_D_Rq 1;
BA_ "ECGUsedRxSignal" SG_ 453 SeatCshnRclCtlPsn_D_Rq2 1;
BA_ "GenSigSendType" SG_ 454 SeatDevcSetDrv_D_Rq 3;
BA_ "GenSigSendType" SG_ 454 SeatCshnRclPsn_D_RqMnu 3;
BA_ "ECGUsedRxSignal" SG_ 454 SeatCshnRclPsn_D_RqMnu 1;
BA_ "GenSigSendType" SG_ 454 SeatDevcSetPsngr_D_Rq 3;
BA_ "GenSigSendType" SG_ 454 SeatHeadrstAdjPsn_D_Rq 3;
BA_ "GenSigSendType" SG_ 454 SeatSlidR2Psng_D_RqMnu 3;
BA_ "ECGUsedRxSignal" SG_ 454 SeatSlidR2Psng_D_RqMnu 1;
BA_ "GenSigSendType" SG_ 454 SeatSetMnuDrv_D_Rq 3;
BA_ "GenSigSendType" SG_ 454 SeatHeadrstAdjDrv_D_Rq 3;
BA_ "GenSigSendType" SG_ 454 StmsPsngr_D_RqMnu 3;
BA_ "GenSigSendType" SG_ 454 StmsDrv_D_RqMnu 3;
BA_ "GenSigSendType" SG_ 454 SeatDevcAdjDrv_D_Rq 3;
BA_ "GenSigSendType" SG_ 454 SeatDevcAdjPsngr_D_Rq 3;
BA_ "GenSigSendType" SG_ 454 DataTrnsfrMde_D_Rq 3;
BA_ "ECGUsedRxSignal" SG_ 454 DataTrnsfrMde_D_Rq 1;
BA_ "GenSigSendType" SG_ 454 SeatSetMnuPsngr_D_Rq 3;
BA_ "GenSigSendType" SG_ 454 SeatSlidR2Drv_D_RqMnu 3;
BA_ "ECGUsedRxSignal" SG_ 454 SeatSlidR2Drv_D_RqMnu 1;
BA_ "GenSigSendType" SG_ 454 StmsPsngr_D2_RqMnu 3;
BA_ "GenSigSendType" SG_ 454 StmsDrv_D2_RqMnu 3;
BA_ "GenSigSendType" SG_ 455 SeatDevcAdjR2Drv_D_Rq 3;
BA_ "GenSigSendType" SG_ 455 SeatSetMnuR2Psngr_D_Rq 3;
BA_ "GenSigSendType" SG_ 455 StmsR2Drv_D_RqMnu 3;
BA_ "GenSigSendType" SG_ 455 SeatCshnRclCtlPsn_D_Rq3 3;
BA_ "GenSigSendType" SG_ 455 SeatDevcSetR2Drv_D_Rq 3;
BA_ "GenSigSendType" SG_ 455 SeatDevcAdjR2Psng_D_Rq 3;
BA_ "GenSigSendType" SG_ 455 SeatDevcSetR2Psng_D_Rq 3;
BA_ "GenSigSendType" SG_ 455 StmsR2Psngr_D2_RqMnu 3;
BA_ "GenSigSendType" SG_ 455 StmsR2Drv_D2_RqMnu 3;
BA_ "GenSigSendType" SG_ 455 SeatSetMnuR2Drv_D_Rq 3;
BA_ "GenSigSendType" SG_ 462 AprIndx_No_Rq 3;
BA_ "GenSigSendType" SG_ 462 AprIdUnlck_B_Stat 3;
BA_ "GenSigSendType" SG_ 462 AprAuthntctn_B_Rq 3;
BA_ "GenSigSendType" SG_ 462 AprPsswrdBackup_B_Rq 3;
BA_ "GenSigSendType" SG_ 462 AprInfo_B_Rq 3;
BA_ "GenSigStartValue" SG_ 464 SDARS_DirectChannel_Rq 1023;
BA_ "GenSigSendType" SG_ 464 SdarsSampleRate_D_Rq 3;
BA_ "GenSigStartValue" SG_ 464 SdarsDirctChnl_No2_Rq 65535;
BA_ "GenSigSendType" SG_ 464 SdarsDirctChnl_No2_Rq 3;
BA_ "GenSigSendType" SG_ 467 RjvntActv_D_Stat 3;
BA_ "ECGUsedRxSignal" SG_ 467 RjvntActv_D_Stat 1;
BA_ "GenSigSendType" SG_ 467 RjvntSeatCool_B_Rq 3;
BA_ "GenSigSendType" SG_ 467 RjvntSeatHeat_B_Rq 3;
BA_ "GenSigSendType" SG_ 467 RjvntThemSel_D_Stat 3;
BA_ "ECGUsedRxSignal" SG_ 467 RjvntThemSel_D_Stat 1;
BA_ "GenSigSendType" SG_ 467 RjvntSeatSetSavDrv_B_Rq 3;
BA_ "GenSigSendType" SG_ 467 DgtlShadeAr1Front_D_Rq 3;
BA_ "GenSigSendType" SG_ 467 RjvntPhs_D_Stat 3;
BA_ "ECGUsedRxSignal" SG_ 467 RjvntPhs_D_Stat 1;
BA_ "GenSigSendType" SG_ 467 RjvntScent_B_Rq 3;
BA_ "GenSigSendType" SG_ 467 RjvntSeatMov_B_Rq 3;
BA_ "GenSigSendType" SG_ 467 DgtlShadeAr3Front_D_Rq 3;
BA_ "GenSigSendType" SG_ 467 DgtlShadeAr2Front_D_Rq 3;
BA_ "GenSigSendType" SG_ 467 DgtlShadeAr5Front_D_Rq 3;
BA_ "GenSigSendType" SG_ 467 DgtlShadeAr4Front_D_Rq 3;
BA_ "GenSigSendType" SG_ 467 DgtlShadeMdeFront_D_Rq 3;
BA_ "GenSigSendType" SG_ 467 DgtlShadeAr6Front_D_Rq 3;
BA_ "GenSigSendType" SG_ 470 VRM_SynchNavNameTag_Rsp 3;
BA_ "GenSigSendType" SG_ 470 VRM_PlayNametag_Rsp 3;
BA_ "GenSigSendType" SG_ 470 VRM_DeleteNameTag_Rsp 3;
BA_ "GenSigSendType" SG_ 470 VRM_SetDefaultPhone_Rsp 3;
BA_ "GenSigSendType" SG_ 470 VRM_BTEndTelService_Rsp 3;
BA_ "GenSigSendType" SG_ 470 VRM_BTSendDTMFTone_Rsp 3;
BA_ "GenSigSendType" SG_ 470 VRM_DebondPhone_Rsp 3;
BA_ "GenSigSendType" SG_ 470 VRM_BTIncomingCall_Rsp 3;
BA_ "GenSigSendType" SG_ 470 VRM_BTActFeatDevInd_Rsp 3;
BA_ "GenSigSendType" SG_ 470 VRM_BTDebondDevice_Rsp 3;
BA_ "GenSigSendType" SG_ 470 VR_StartPhoneVR_Rsp 3;
BA_ "ECGUsedTxSignal" SG_ 471 ApnlNameTxt09_No_Actl 1;
BA_ "ECGUsedTxSignal" SG_ 471 ApnlNameTxt10_No_Actl 1;
BA_ "ECGUsedTxSignal" SG_ 471 ApnlNameTxt11_No_Actl 1;
BA_ "ECGUsedTxSignal" SG_ 471 ApnlNameTxt12_No_Actl 1;
BA_ "ECGUsedTxSignal" SG_ 471 ApnlNameTxt13_No_Actl 1;
BA_ "ECGUsedTxSignal" SG_ 471 ApnlNameTxt14_No_Actl 1;
BA_ "ECGUsedTxSignal" SG_ 471 ApnlNameTxt15_No_Actl 1;
BA_ "ECGUsedTxSignal" SG_ 471 ApnlNameTxt16_No_Actl 1;
BA_ "ECGUsedTxSignal" SG_ 472 ApnlNameTxt17_No_Actl 1;
BA_ "ECGUsedTxSignal" SG_ 472 ApnlNameTxt18_No_Actl 1;
BA_ "GenSigSendType" SG_ 473 NAV_SetTAMode_Rq 3;
BA_ "GenSigSendType" SG_ 473 NAV_SetAFMode_Rq 3;
BA_ "GenSigSendType" SG_ 473 NAV_SetTUServiceLink_Rq 3;
BA_ "GenSigSendType" SG_ 473 NAV_CDSetShuffle_Rq 3;
BA_ "GenSigSendType" SG_ 473 NAV_StorePreset2_Rq 3;
BA_ "GenSigSendType" SG_ 473 NAV_SelectPTYCodeSet_Rq 3;
BA_ "GenSigSendType" SG_ 473 HMI_StorePreset2_Rq 3;
BA_ "GenSigSendType" SG_ 473 NAV_CDSetRepeat_Rq 3;
BA_ "GenSigSendType" SG_ 473 NAV_CDSetIntroScan_Rq 3;
BA_ "GenSigSendType" SG_ 473 NAV_StorePreset_Rq 3;
BA_ "GenSigSendType" SG_ 473 NAV_SetReg_Rq 3;
BA_ "GenSigSendType" SG_ 474 NAV_AROperationType_Rq 3;
BA_ "GenSigStartValue" SG_ 474 NAV_SetMid_Rq 15;
BA_ "GenSigSendType" SG_ 474 NAV_SetMid_Rq 3;
BA_ "GenSigSendType" SG_ 474 NAV_SetCurrentStatOp_Rq 3;
BA_ "GenSigSendType" SG_ 474 NAV_SetNEWSMode_Rq 3;
BA_ "GenSigSendType" SG_ 474 NAV_SetDSP_Rq 3;
BA_ "GenSigSendType" SG_ 476 NAV_SkipCatalouge_Rq 3;
BA_ "GenSigSendType" SG_ 476 NAV_SetDSPProgram_Rq 3;
BA_ "GenSigSendType" SG_ 476 NAV_SetOperationMode_Rq 3;
BA_ "GenSigStartValue" SG_ 476 Nav_SetAudioMixRatio_Rq 31;
BA_ "GenSigSendType" SG_ 476 Nav_SetAudioMixRatio_Rq 3;
BA_ "GenSigStartValue" SG_ 477 NAV_SetTreble_Rq 15;
BA_ "GenSigSendType" SG_ 477 NAV_SetTreble_Rq 3;
BA_ "GenSigStartValue" SG_ 477 NAV_SetBass_Rq 15;
BA_ "GenSigSendType" SG_ 477 NAV_SetBass_Rq 3;
BA_ "GenSigStartValue" SG_ 477 NAV_SetFader_Rq 15;
BA_ "GenSigSendType" SG_ 477 NAV_SetFader_Rq 3;
BA_ "GenSigStartValue" SG_ 477 NAV_SetBalance_Rq 15;
BA_ "GenSigSendType" SG_ 477 NAV_SetBalance_Rq 3;
BA_ "GenSigStartValue" SG_ 477 NAV_SetAVC_Rq 15;
BA_ "GenSigSendType" SG_ 477 NAV_SetAVC_Rq 3;
BA_ "GenSigSendType" SG_ 477 NAV_LoadEjectMode_Rq 3;
BA_ "GenSigSendType" SG_ 477 NAV_SecurtyPINUnlock_Rq 3;
BA_ "GenSigStartValue" SG_ 479 DISP_SetVolume_Rq 30;
BA_ "GenSigSendType" SG_ 479 DISP_SetVolume_Rq 3;
BA_ "GenSigSendType" SG_ 479 DISP_SetVol_Source_Rq 3;
BA_ "GenSigSendType" SG_ 479 DISP_Setshaker_Rq 3;
BA_ "GenSigStartValue" SG_ 481 PsCpbltyPrim_B_Stat 1;
BA_ "GenSigStartValue" SG_ 481 PsCpbltyScnd_B_Stat 1;
BA_ "GenSigStartValue" SG_ 481 DrStatAllSides_D_Actl 1;
BA_ "GenSigSendType" SG_ 482 SDARS_Antenna_Err2_St 3;
BA_ "GenSigSendType" SG_ 482 SDARS_Error_Conf2_St 3;
BA_ "GenSigSendType" SG_ 482 SDARS_Receive_Err2_St 3;
BA_ "GenSigSendType" SG_ 482 SDARS_Firm_Update2_St 3;
BA_ "GenSigSendType" SG_ 482 SDARS_Invalid_Chan2_St 3;
BA_ "GenSigSendType" SG_ 482 SDARS_Seek_Scan2_St 3;
BA_ "GenSigSendType" SG_ 482 SDARS_UnSubscrb2_St 3;
BA_ "GenSigSendType" SG_ 482 SDARS_Loss_Ant2_St 3;
BA_ "GenSigSendType" SG_ 482 SdarsCntntBlked_D_Stat 3;
BA_ "GenSigSendType" SG_ 482 SDARS_GCI_Update2_St 3;
BA_ "GenSigSendType" SG_ 482 SDARS_Subscription2_St 3;
BA_ "GenSigSendType" SG_ 482 SDARS_UnSubscrb_Chan2_St 3;
BA_ "GenSigSendType" SG_ 482 SdarsCnnctDisabl_D_St 3;
BA_ "GenSigSendType" SG_ 482 SdarsGeoRstrcCntnt_D_St 3;
BA_ "GenSigSendType" SG_ 482 SdarsActnRqd_D_Stat 3;
BA_ "GenSigSendType" SG_ 486 ResponseCode_No_Res 3;
BA_ "GenSigSendType" SG_ 486 ACU_ARResponse_Rsp 1;
BA_ "ECGUsedRxSignal" SG_ 486 ACU_RUResReqstStatus_St 1;
BA_ "ECGUsedRxSignal" SG_ 486 ACU_RUAudioSource_St 1;
BA_ "GenSigSendType" SG_ 487 Aioc_SetExtSrcOutpMd_Rq 3;
BA_ "GenSigStartValue" SG_ 488 AugRealtyMdule_B_Rq 1;
BA_ "GenSigSendType" SG_ 488 AugRealtyMdule_B_Rq 3;
BA_ "GenSigSendType" SG_ 489 ACU_CurrentPSName_St 3;
BA_ "GenSigSendType" SG_ 490 HMI_SetCompression_Rq 3;
BA_ "GenSigSendType" SG_ 490 HMI_SkipTrack_Rq 3;
BA_ "GenSigSendType" SG_ 493 Dsp_StationList_Rq 3;
BA_ "GenSigSendType" SG_ 493 Dsp_AFJump_Rq 3;
BA_ "GenSigSendType" SG_ 493 Dsp_StatLiScanCancel_Rq 3;
BA_ "GenSigSendType" SG_ 494 HEC_TUPresetArea_Rq 3;
BA_ "GenSigSendType" SG_ 494 HEC_SetCurrTUBand_Rq 3;
BA_ "GenSigSendType" SG_ 494 Mc_SetCurrPreset2_Rq 3;
BA_ "GenSigSendType" SG_ 497 McEvntNotfnChoice_D_Rq 3;
BA_ "GenSigSendType" SG_ 497 McEvntNotfnMsgId_D_Rq 3;
BA_ "GenSigSendType" SG_ 497 McEvntNotfnData1_D_Rq 3;
BA_ "GenSigSendType" SG_ 497 McEvntNotfnData2_D_Rq 3;
BA_ "GenSigSendType" SG_ 497 McEvntNotfnData3_D_Rq 3;
BA_ "GenSigSendType" SG_ 498 HEC_AROperationType_Rq 3;
BA_ "GenSigSendType" SG_ 500 Dsp_GetCDTOCDData_Rq 3;
BA_ "GenSigSendType" SG_ 500 Dsp_AudioSourceSel_Rq 3;
BA_ "GenSigSendType" SG_ 501 Dsp_SetCurrPreset2_Rq 3;
BA_ "GenSigSendType" SG_ 501 Dsp_SetCRadioBand_Rq 3;
BA_ "GenSigSendType" SG_ 501 Dsp_SetCurrFMSLPr_Rq 3;
BA_ "GenSigSendType" SG_ 501 Dsp_PresetArea_Rq 3;
BA_ "GenSigSendType" SG_ 501 Dsp_FreezeFMSL_Rq 3;
BA_ "GenSigSendType" SG_ 501 Dsp_SetRadSeekMode_Rq 3;
BA_ "GenSigSendType" SG_ 502 Dsp_AudioSourceSel2_Rq 3;
BA_ "GenSigSendType" SG_ 503 Dsp_AudioSourceSel3_Rq 3;
BA_ "GenSigSendType" SG_ 504 Mc_AudioSourceSel_Rq 3;
BA_ "GenSigSendType" SG_ 505 Mc_AudioSourceSel2_Rq 3;
BA_ "GenSigSendType" SG_ 506 Mc_AudioSourceSel3_Rq 3;
BA_ "GenSigSendType" SG_ 507 Mc_DB1SetTrkItmIndex_Rq 1;
BA_ "GenSigSendType" SG_ 508 Mc_DB1GetInfStartInd_Rq 1;
BA_ "GenSigSendType" SG_ 509 TrakAppl_D_Stat 3;
BA_ "GenSigSendType" SG_ 511 Dsp_TUPresetArea_Rq 3;
BA_ "GenSigSendType" SG_ 511 Dsp_SetCurrTUBand_Rq 3;
BA_ "GenSigSendType" SG_ 511 SdarsAudioRtng_D_Rq 3;
BA_ "GenSigSendType" SG_ 511 Dsp_SetCurrTUPreset_Rq 3;
BA_ "WakeupSignal" SG_ 513 ChrgStat_D3_Dsply 1;
BA_ "GenSigStartValue" SG_ 513 BptAllw_Pw_Dsply 1022;
BA_ "GenSigStartValue" SG_ 513 OnDmdCondDrv_T_Actl 2046;
BA_ "GenSigStartValue" SG_ 514 GearRvrse_D_Actl 7;
BA_ "GenSigStartValue" SG_ 515 PtIgnSwtch_D_Stat 2;
BA_ "GenSigStartValue" SG_ 516 ApedPosPcActl_D_Qf 1;
BA_ "GenSigStartValue" SG_ 516 EngAoutNActl_D_QF 1;
BA_ "GenSigStartValue" SG_ 523 UreaMxAdd_L2_Actl 510;
BA_ "GenSigStartValue" SG_ 528 TireFront_P_OffRoad1 255;
BA_ "GenSigStartValue" SG_ 528 TireFront_P_OffRoad2 255;
BA_ "GenSigStartValue" SG_ 528 TireRear_P_OffRoad1 255;
BA_ "GenSigStartValue" SG_ 528 TireRear_P_OffRoad2 255;
BA_ "GenSigSendType" SG_ 529 OnbChrgLocIdTrgt_No_Rq 3;
BA_ "GenSigSendType" SG_ 529 OnbChrgPrflUpdate_B_Rq 3;
BA_ "ECGUsedRxSignal" SG_ 529 OnbChrgPrflUpdate_B_Rq 1;
BA_ "GenSigSendType" SG_ 530 StationTypeSel_D_Rq 3;
VAL_ 261 OffPeakTimeSetType_Rq 0 "Inactive" 1 "WeekdayStart" 2 "WeekdayEnd" 3 "WeekendStart" 4 "WeekendEnd" ;
VAL_ 261 NextUsageTimeToggle_Rq 0 "Inactive" 1 "Enable" 2 "Disable" ;
VAL_ 261 LongTermParking_Rq 0 "Inactive" 1 "Off" 2 "On" ;
VAL_ 261 FactoryReset_Rq 0 "Inactive" 1 "ResetFactoryDefaults" ;
VAL_ 261 TCU_ESN_D_Rq 0 "Inactive" 1 "NoRequest" 2 "TCU_ESN_Request" 3 "NotUsed" ;
VAL_ 261 StopStrtDrvMde_B_RqBtn3 0 "Not_Pressed" 1 "Pressed" ;
VAL_ 261 AudioToneTouch_D_Rq 0 "Null" 1 "Disabled" 2 "Enabled" 3 "NotUsed" ;
VAL_ 261 ModemReset_D_Rq 0 "Null" 1 "WifiHotspotReset" 2 "PaakReset" 3 "OnlineTrafficReset" 4 "CcsReset" 5 "BrandConnectReset1" 6 "BrandConnectReset2" 7 "NotUsed_3" 8 "NotUsed_4" 9 "NotUsed_5" 10 "NotUsed_6" 11 "NotUsed_7" 12 "NotUsed_8" 13 "NotUsed_9" 14 "NotUsed_10" 15 "NotUsed_11" ;
VAL_ 261 ChrgStatDsply_D_Rq 0 "Off" 1 "On" 2 "NotUsed_1" 3 "NotUsed_2" ;
VAL_ 261 AudioToneTouchX_D_Rq 0 "Null" 1 "Value0" 2 "Value1_up_to_0xFE_Value253" 255 "Value254" ;
VAL_ 261 AudioToneTouchY_D_Rq 0 "Null" 1 "Value0" 2 "Value1_up_to_0xFE_Value253" 255 "Value254" ;
VAL_ 262 OnbChrgGlblAcMx_I_Rq 255 "Fault" ;
VAL_ 262 OnbChrgSetUpdate_B_Rq 0 "NoRequest" 1 "Request" ;
VAL_ 262 OnbChrgGlblDcMx_Pw_Rq 127 "Faulty" ;
VAL_ 266 OfbChrgSetUpdate_B_Rq 0 "NoRequest" 1 "Request" ;
VAL_ 266 UceStrtHr_T_Actl 30 "Unknown" 31 "Invalid" ;
VAL_ 266 UceEndDay_No_Actl 31 "Invalid" ;
VAL_ 266 UceEndMnth_No_Actl 15 "Invalid" ;
VAL_ 266 UceEndMin_T_Actl 62 "Unknown" 63 "Invalid" ;
VAL_ 266 UceEndHr_T_Actl 30 "Unknown" 31 "Invalid" ;
VAL_ 267 BattChrgIn_E_Actl 4094 "NoDataExists" 4095 "Faulty" ;
VAL_ 267 BattChrgOut_E_Actl 4094 "NoDataExists" 4095 "Faulty" ;
VAL_ 267 UceDchrg_E_Actl 4094 "NoDataExists" 4095 "Faulty" ;
VAL_ 267 GridSrvc02_D_Stat 0 "Off" 1 "BackupPower" 2 "NoData" 3 "ZeroExport" 4 "PositiveExport" 5 "UtilityExport" 6 "DC_Charging" 7 "AC_Charging" 8 "SolarCharge" 9 "NotUsed_1" 10 "NotUsed_2" 11 "NotUsed_3" 12 "NotUsed_4" 13 "NotUsed_5" 14 "NotUsed_6" 15 "NotUsed_7" ;
VAL_ 267 IpwEnbl_B_Stat 0 "Off" 1 "On" ;
VAL_ 270 UceStrtDay_No_Actl 31 "UNUSED" ;
VAL_ 270 UceStrtMin_T_Actl 62 "Unknown" 63 "Invalid" ;
VAL_ 270 UceStrtMnth_No_Actl 15 "Invalid" ;
VAL_ 282 HudPersSrvc_D_Rq 0 "Null" 1 "Query" 2 "Set" 3 "Upload" 4 "Restore" 5 "Copy" 6 "NotUsed_1" 7 "NotUsed_2" ;
VAL_ 282 HudPersIndx_No_Rq 0 "Pers_1" 1 "Pers_2" 2 "Pers_3" 3 "Pers_4" 4 "Vehicle" 5 "NotUsed_1" 6 "NotUsed_2" 7 "NotUsed_3" ;
VAL_ 290 WifiHtsptMacAddr_B_Rq 0 "No_request" 1 "Request" ;
VAL_ 290 WifiHtsptEnbl_D_Rq 0 "Null" 1 "Off" 2 "On" 3 "Not_used" ;
VAL_ 290 WifiDevcList_D_Rq 0 "Null" 1 "ConnectedList" 2 "BlockedList" 3 "NoEntry" ;
VAL_ 290 WifiDataUsage_D_Rq 0 "Null" 1 "CurrentData" 2 "RefreshData" 3 "RetriveDataFromBackend" ;
VAL_ 290 WifiCarrierInfo_B_Rq 0 "No_request" 1 "Request" ;
VAL_ 290 WifiHtsptScrty_D_Rq 0 "Null" 1 "Wpa2_Wpa" 2 "Wapi" 3 "NotUsed_1" ;
VAL_ 290 WifiHtsptFqBand_D_Rq 0 "Null" 1 "Band_1" 2 "Band_2" 3 "NotUsed_1" ;
VAL_ 290 WifiHtsptTrial_D_RqDrv 0 "Null" 1 "RemindMeLater" 2 "StopReminders" 3 "NotUsed_1" ;
VAL_ 290 WifiRemoveDevc_D_Rq 0 "Null" 1 "FromConnectedList" 2 "FromBlockedList" 3 "NotUsed_1" ;
VAL_ 290 WifiHtsptVisbl_D_Rq 0 "Null" 1 "Off" 2 "On" 3 "Not_used" ;
VAL_ 291 LangUpdate_Rsp 0 "Inactive" 1 "Language_Updated" 2 "Language_Not_Supported" ;
VAL_ 293 ClmtCtrlSeat_SetStat_Dvr 2 "Off" 4 "C1_Low_Cool" 8 "C2_Medium_Cool" 16 "C3_High_Cool_MAX" 32 "H1_Low_Heat" 64 "H2_Medium_Heat" 128 "H3_High_Heat_MAX" ;
VAL_ 293 ClmtCtrlSeat_SetStat_Psgr 2 "Off" 4 "C1_Low_Cool" 8 "C2_Medium_Cool" 16 "C3_High_Cool_MAX" 32 "H1_Low_Heat" 64 "H2_Medium_Heat" 128 "H3_High_Heat_MAX" ;
VAL_ 293 PdlAutoSav_D_Stat 0 "None" 1 "InProgress" 2 "Major" 3 "Minor" ;
VAL_ 293 SeatAutoSavDrv_D_Stat 0 "None" 1 "InProgress" 2 "Major" 3 "Minor" ;
VAL_ 293 SteAutoSav_D_Stat 0 "None" 1 "InProgress" 2 "Major" 3 "Minor" ;
VAL_ 300 VdsSftyDrv_D_Rq 0 "Null" 1 "False" 2 "True" 3 "NotUsed" ;
VAL_ 300 PwTest_B_Rdy 0 "No" 1 "Yes" ;
VAL_ 303 DrStatHood_D2_Actl 0 "NotDetermined" 1 "Closed" 2 "Ajar" 3 "Disabled" 4 "NotUsed_1" 5 "NotUsed_2" 6 "NotUsed_3" 7 "Faulty" ;
VAL_ 303 DrTgateAjar_D_Stat 0 "Closed" 1 "Ajar" 2 "NotUsed_1" 3 "Faulty" ;
VAL_ 307 BrkAbsPrim_B_Falt 0 "NoFault" 1 "Fault" ;
VAL_ 307 BrkDfaltPrim_B_Stat 0 "No" 1 "Yes" ;
VAL_ 307 BrkEbdPrim_B_Falt 0 "NoFault" 1 "Fault" ;
VAL_ 307 BrkEpbPrim_B_Falt 0 "NoFault" 1 "Fault" ;
VAL_ 307 BrkRedndncyPrim_B_Falt 0 "NoFault" 1 "Fault" ;
VAL_ 307 BrkStabCtlPrim_B_Falt 0 "NoFault" 1 "Fault" ;
VAL_ 307 BrkTracCtlPrim_B_Falt 0 "NoFault" 1 "Fault" ;
VAL_ 307 AvMtnCtlPrim_D_Stat 0 "Null" 1 "Off" 2 "VdsOnDeactivated" 3 "VdsOnActivated" 4 "MobcOnDeactivated" 5 "MobcOnActivated" 6 "NotUsed_1" 7 "NotUsed_2" ;
VAL_ 307 PrkPrim_B_Stat 0 "NotParked" 1 "Parked" ;
VAL_ 307 MobcVLimPrim_D_Stat 0 "NoLimit" 1 "Limit1" 2 "Limit2" 3 "Los" ;
VAL_ 307 LongCtlSrcPrim_D_Actl 0 "Default" 1 "VirtualDriver" 2 "HumanDriver" 3 "MobilityController" ;
VAL_ 307 GearLvrPrim_D_Rq 0 "Park" 1 "Reverse" 2 "Neutral" 3 "Drive" 4 "Low" 5 "NotUsed_1" 6 "NotUsed_2" 7 "Faulty" ;
VAL_ 310 SecondRowBucklePsngrMid2 0 "EmptyBelted" 1 "NotDetermined" 2 "BatteryLow" 3 "OccupiedUnbelted" 4 "EmptyUnbelted" 5 "SeatAbsent" 6 "OccupiedBelted" 7 "Faulty" ;
VAL_ 310 SecondRowBuckleDrvMid2 0 "EmptyBelted" 1 "NotDetermined" 2 "BatteryLow" 3 "OccupiedUnbelted" 4 "EmptyUnbelted" 5 "SeatAbsent" 6 "OccupiedBelted" 7 "Faulty" ;
VAL_ 310 ThirdRowBucklePsngrMid 0 "EmptyBelted" 1 "NotDetermined" 2 "BatteryLow" 3 "OccupiedUnbelted" 4 "EmptyUnbelted" 5 "SeatAbsent" 6 "OccupiedBelted" 7 "Faulty" ;
VAL_ 310 ThirdRowBuckleDrvMid 0 "EmptyBelted" 1 "NotDetermined" 2 "BatteryLow" 3 "OccupiedUnbelted" 4 "EmptyUnbelted" 5 "SeatAbsent" 6 "OccupiedBelted" 7 "Faulty" ;
VAL_ 310 FourthRowBucklePsngrMid 0 "EmptyBelted" 1 "NotDetermined" 2 "BatteryLow" 3 "OccupiedUnbelted" 4 "EmptyUnbelted" 5 "SeatAbsent" 6 "OccupiedBelted" 7 "Faulty" ;
VAL_ 310 FourthRowBuckleDrvMid 0 "EmptyBelted" 1 "NotDetermined" 2 "BatteryLow" 3 "OccupiedUnbelted" 4 "EmptyUnbelted" 5 "SeatAbsent" 6 "OccupiedBelted" 7 "Faulty" ;
VAL_ 310 FifthRowBuckleDrvMid 0 "EmptyBelted" 1 "NotDetermined" 2 "BatteryLow" 3 "OccupiedUnbelted" 4 "EmptyUnbelted" 5 "SeatAbsent" 6 "OccupiedBelted" 7 "Faulty" ;
VAL_ 310 FifthRowBuckleDrv 0 "EmptyBelted" 1 "NotDetermined" 2 "BatteryLow" 3 "OccupiedUnbelted" 4 "EmptyUnbelted" 5 "SeatAbsent" 6 "OccupiedBelted" 7 "Faulty" ;
VAL_ 310 FifthRowBucklePsngr 0 "EmptyBelted" 1 "NotDetermined" 2 "BatteryLow" 3 "OccupiedUnbelted" 4 "EmptyUnbelted" 5 "SeatAbsent" 6 "OccupiedBelted" 7 "Faulty" ;
VAL_ 310 FifthRowBuckleMid 0 "EmptyBelted" 1 "NotDetermined" 2 "BatteryLow" 3 "OccupiedUnbelted" 4 "EmptyUnbelted" 5 "SeatAbsent" 6 "OccupiedBelted" 7 "Faulty" ;
VAL_ 310 FifthRowBucklePsngrMid 0 "EmptyBelted" 1 "NotDetermined" 2 "BatteryLow" 3 "OccupiedUnbelted" 4 "EmptyUnbelted" 5 "SeatAbsent" 6 "OccupiedBelted" 7 "Faulty" ;
VAL_ 317 VehPtch_An_Actl 254 "NoDataExists" 255 "Faulty" ;
VAL_ 330 TrnFaltOpenClu_B_Stat 0 "Normal" 1 "MayOpenClutch" ;
VAL_ 330 TrnAout_W_ActlUnfilt 32766 "Unknown" 32767 "Fault" ;
VAL_ 331 TrnAout2_W_ActlUnfilt 65534 "NoDataExists" 65535 "Fault" ;
VAL_ 331 CmbbEngTqMn_B_ActlHtrn 0 "Inactive" 1 "Active" ;
VAL_ 331 CmbbDeny_B_ActlHtrn 0 "No" 1 "Yes" ;
VAL_ 332 UreaQltyFlg_B_RqDsply 0 "False" 1 "True" ;
VAL_ 332 UreaQltySys_D_RqDsply 0 "NoQualityProblem" 1 "CONTAMINATED_ExhFluid" 2 "YY_MPH_MAX_UPON_Restart" 3 "SPEED_LIMITED_to_YY_mph" 4 "Engine_Idle_Upon_Refuel" 5 "EngineIdled" 6 "ZZ_Overrides" 7 "Undefined" ;
VAL_ 332 UreaLvlTxt_D_RqDsply 0 "Exh_Fluid_Over_Half_Full" 1 "Exh_Fluid_Under_Half_Full" 2 "Exh_Fluid_Range_XX_Miles" 3 "ExFlRange_XXMiles_ScndWarn" 4 "SpdLimtd_YYmph_In_XXmiles" 5 "YYmph_Max_Upon_Restart" 6 "Speed_Limited_To_YY_mph" 7 "XXmph_Max_Upon_Restart" 8 "Speed_Limited_To_XX_mph" 9 "Engine_Idled_Upon_Refuel" 10 "Engine_Idled_See_Manual" 11 "System_Error" 12 "NotUsed_1" 13 "NotUsed_2" 14 "NotUsed_3" 15 "NotUsed_4" ;
VAL_ 332 UreaLvlQlty_D_RqDsply 0 "Off" 1 "On" 2 "FlashChime" 3 "NotUsed_1" 4 "NotUsed_2" 5 "NotUsed_3" 6 "NotUsed_4" 7 "NotUsed_5" ;
VAL_ 332 DieslPrtcWarn_D_Rq 0 "DPF_Normal_Operation" 1 "DPF_OverLoaded" 2 "Cleaning_Exhaust_Filter" 3 "ExhFilter_Drive_Completed" 4 "DPF_AtLimit" 5 "DPF_OverLimit" 6 "Exhaust_Filter_Full" 7 "RgnOff_Loaded" 8 "RgnOff_OverLoaded" 9 "RgnOff_AtLimit" 10 "OCR_ExhFilterCleaned" 11 "OCR_ExhFilterClean_Stopped" 12 "NotUsed_1" 13 "NotUsed_2" 14 "NotUsed_3" 15 "NotUsed_4" ;
VAL_ 332 UreaQltySysWarn_D_Rq 0 "NoQualityProblem" 1 "CONTAMINATED_ExhFluid" 2 "YY_MPH_MAX_UPON_Restart" 3 "SPEED_LIMITED_to_YY_mph" 4 "Engine_Idle_Upon_Refuel" 5 "EngineIdled" 6 "ZZ_Overrides" 7 "Undefined" ;
VAL_ 332 UreaLvlTxtWarn_D_Rq 0 "Exh_Fluid_Over_Half_Full" 1 "Exh_Fluid_Under_Half_Full" 2 "Exh_Fluid_Range_XX_Miles" 3 "ExFlRange_XXMiles_ScndWarn" 4 "SpdLimtd_YYmph_In_XXmiles" 5 "YYmph_Max_Upon_Restart" 6 "Speed_Limited_To_YY_mph" 7 "XXmph_Max_Upon_Restart" 8 "Speed_Limited_To_XX_mph" 9 "Engine_Idled_Upon_Refuel" 10 "Engine_Idled_See_Manual" 11 "System_Error" 12 "NotUsed_1" 13 "NotUsed_2" 14 "NotUsed_3" 15 "NotUsed_4" ;
VAL_ 333 VehElAvgTrip1_Eff2_Dsply 2046 "Nodataexists" 2047 "Faulty" ;
VAL_ 333 VehElAvgTrip2_Eff2_Dsply 2046 "Nodataexists" 2047 "Faulty" ;
VAL_ 333 VehElEffTrip_No2_Dsply 2046 "Nodataexists" 2047 "Faulty" ;
VAL_ 333 VehElEffAvg_No2_Dsply 2046 "Nodataexists" 2047 "Faulty" ;
VAL_ 334 PdlAdj_D_Rq_1A 0 "Null" 1 "Forward" 2 "Backward" 3 "NotUsed_1" ;
VAL_ 334 StewPosAdjTlt_D_Rq_1A 0 "Null" 1 "Up" 2 "Down" 3 "NotUsed" ;
VAL_ 334 StewPosAdjTel_D_Rq_1A 0 "Null" 1 "Out" 2 "In" 3 "NotUsed_1" ;
VAL_ 342 EngOil_Te_Actl 254 "Unknown" 255 "Fault" ;
VAL_ 342 EngTeColdPrtct_B_Rq 0 "Off" 1 "On" ;
VAL_ 342 EngOilLvlDsply_D_Rq 0 "No_Message" 1 "Dipstick_Maximum_Displayed" 2 "Dipstick_87_5_MinMaxRange" 3 "Dipstick_75_MinMaxRange" 4 "Dipstick_62_5_MinMaxRange" 5 "Dipstick_50_MinMaxRange" 6 "Dipstick_37_5_MinMaxRange" 7 "Dipstick_25_MinMaxRange" 8 "Dipstick_12_5_MinMaxRange" 9 "Dipstick_Minimum" 10 "Dipstick_Above_Maximum" 11 "Dipstick_Below_Minimum" 12 "Conditions_Unsuitable" 13 "Reserved_1" 14 "Reserved_2" 15 "EngOil_LevelSys_CheckFault" ;
VAL_ 342 TqmTerrMde_D_Actl 0 "Special_Operating_Mode_Off" 1 "Low_Mu_Mode" 2 "Undefined" 3 "Sand_Mode" 4 "Mud_Ruts_Mode" 5 "Rock_Crawl_Mode" 6 "Dynamic_Mode" 7 "Fail_Safe_Default" ;
VAL_ 342 EngClntTe_D_Qf 0 "Faulty" 1 "No_Data_Exists" 2 "Not_Within_Specifications" 3 "OK" ;
VAL_ 342 HtrLoop_B_Stat 0 "No_Fault" 1 "Fault" ;
VAL_ 342 EngOvrhtMitgActv_D_Ind 0 "Normal_Mode" 1 "Mode1" 2 "Mode2" 3 "Undefined" ;
VAL_ 342 TqmTerrMdeChng_D_Rdy 0 "Mode_Change_Available" 1 "Module_In_Initialization" 2 "ModeUnavailDynamicCond" 3 "SpOpModes_NotSupported" 4 "ModeUnavailDrInputRqd" 5 "Undefined_1" 6 "Undefined_2" 7 "Fault" ;
VAL_ 342 EngAcsyArcPmp_Tq_Actl 254 "Unknown" 255 "Fault" ;
VAL_ 355 ManRgenInhbt_L_RqDsply 65535 "Fault" ;
VAL_ 355 ManRgenInhbt_T_RqDsply 65535 "Fault" ;
VAL_ 355 AccFllwMdeActv_B_Actl 0 "Inactive" 1 "Active" ;
VAL_ 355 ManRgenSoot_Pc_RqDsply 127 "Fault" ;
VAL_ 355 ManRgenInhbt_Pc_Soot 127 "Fault" ;
VAL_ 355 AutoRgenTxt_B_RqDsply 0 "AutExhFilterCleanON" 1 "AutExhFilterCleanOFF" ;
VAL_ 355 ManRgenVeh_V_MinAllw 127 "Fault" ;
VAL_ 355 DieslMsgTxt_D_Rq 0 "NoMessage" 1 "ReducedEnginePower" 2 "NotUsed1" 3 "NotUsed2" ;
VAL_ 355 EngPtoMde_D_Actl 0 "Off" 1 "BCP" 2 "PTO_Stationary" 3 "Not_Used_1" 4 "PTO_Mobile" 5 "Not_Used_2" 6 "Split_Shaft_Stationary" 7 "Undefined" ;
VAL_ 355 ManRgenTxt_D_RqDsply 0 "Cleaning_Not_Allowed" 1 "Cleaning_Allowed" 2 "Cleaning_In_Progress" 3 "Cleaning_Completed" 4 "Cleaning_Aborted_Stopped" 5 "NotUsed1" 6 "NotUsed2" 7 "NotUsed3" ;
VAL_ 357 AccEngStat_D_Actl 0 "Normal_Operation" 1 "ACCStandby_due_Auto_Cancel" 2 "ACCNotAllowedToBeActivated" 3 "Shift_Up_Recommendation" 4 "Shift_Down_Recommendation" 5 "ACCSoonCancel_due_Low_Spd" 6 "Undefined_1" 7 "Undefined_2" ;
VAL_ 357 CmbbDeny_B_ActlPrpl 0 "No" 1 "Yes" ;
VAL_ 357 BpedDrvAppl_D_Actl 0 "_Not_Allowed" 1 "Driver_Not_Braking" 2 "Driver_Braking" 3 "Not_Allowed" ;
VAL_ 357 CcOvrrdActv_B_Actl 0 "Cruise_Req_Not_Overridden" 1 "Cruise_Overridden" ;
VAL_ 357 CmbbEngTqMn_B_Actl 0 "No" 1 "Yes" ;
VAL_ 357 CcStat_D_Actl 0 "Off" 1 "Denied" 2 "Standby_Denied" 3 "Standby" 4 "Active_Que_Assist" 5 "Active" 6 "Undefined_1" 7 "Undefined_2" ;
VAL_ 357 CcMde_D_Actl 0 "Not_Active" 1 "Keeping_Speed" 2 "Accelerating" 3 "Decelerating" 4 "Resuming_High" 5 "Resuming_Low" 6 "TapUpWaiting" 7 "TapDownWaiting" ;
VAL_ 357 BPedDrvAppl_D_Qf 0 "Faulty" 1 "No_Data_Exists" 2 "Not_Within_Specifications" 3 "OK" ;
VAL_ 357 Veh_V_DsplyCcSet 254 "Unknown" 255 "Fault" ;
VAL_ 357 AccStopMde_D_Rq 0 "Stop_Mode_Not_Active" 1 "Limit_Rolling_Speed" 2 "EPBApplyOrBrakeReleaseWarn" 3 "Stop_Mode_Active" ;
VAL_ 357 PrplTqMnSat_B_Actl 0 "No" 1 "Yes" ;
VAL_ 357 VehStrtStop_D_Rq 0 "NoRequest" 1 "Vehicle_Stop_Request" 2 "Vehicle_Start_Request" 3 "NotUsed" ;
VAL_ 358 AutoStopPtDelta_I_Est 255 "Fault" ;
VAL_ 358 StopStrtMsgTxt_D_Rq 0 "NoMessage" 1 "Message_1" 2 "Message_2" 3 "Message_3" 4 "Message_4" 5 "Message_5" 6 "Message_6" 7 "Message_7" 8 "Message_8" 9 "Message_9" 10 "Message_10" 11 "Message_11" 12 "Message_12" 13 "Message_13" 14 "Message_14" 15 "Message_15" ;
VAL_ 358 StopStrtDrvMde_D_Indic 0 "StopStart_Selected" 1 "StopStart_Deselected" 2 "StartStop_IndirectDeselect" 3 "NotUsed" ;
VAL_ 358 HiElPwInhbt_B_Stat 0 "No_Inibit" 1 "Inhibit" ;
VAL_ 358 StrtrMtrCtlMsgTxt_D3_Rq 0 "NoMessage" 1 "ToDrivePressBrkSelectGear" 2 "BrakeToStopOrD_RtoRestart" 3 "NotUsed_1" 4 "NotUsed_2" 5 "NotUsed_3" 6 "NotUsed_4" 7 "NotUsed_5" ;
VAL_ 358 OdoTripVerify_L_Actl 16777215 "Fault" ;
VAL_ 358 StopStrtIODTxt_D_Rq 0 "NoMessage" 1 "Message1" 2 "Message2" 3 "Message3" 4 "Message4" 5 "Message5" 6 "Message6" 7 "Message7" 8 "Message8" 9 "Message9" 10 "Message10" 11 "Message11" 12 "Message12" 13 "Message13" 14 "Message14" 15 "Message15" 16 "Message16" 17 "Message17" 18 "Message18" 19 "Message19" 20 "Message20" 21 "Message21" 22 "Message22" 23 "Message23" 24 "Message24" 25 "Message25" 26 "Message26" 27 "Message27" 28 "Message28" 29 "Message29" 30 "Message30" 31 "Message31" ;
VAL_ 358 StopStrtStdby_D_Indic 0 "Telltale_Off" 1 "Telltale_On_Green" 2 "Telltale_Flashing_Green" 3 "Telltale_On_Amber" 4 "Telltale_Flashing_Amber" 5 "Telltale_Struck_Out" 6 "Telltale_On_Grey" 7 "NotUsed3" ;
VAL_ 359 PlgActvArb_B_Actl 0 "Off" 1 "On" ;
VAL_ 359 ElPw_D_Stat 0 "Not_Supported" 1 "Supported" 2 "Not_Supported_Imminent" 3 "LV_Event_In_Progress" 4 "Fault_Limited" 5 "NotUsed_1" 6 "NotUsed_2" 7 "NotUsed_3" ;
VAL_ 359 PwPckTq_D_Stat 0 "PwPckOff_TqNotAvailable" 1 "PwPckOn_TqNotAvailable" 2 "StartInPrgrss_TqNotAvail" 3 "PwPckOn_TqAvailable" ;
VAL_ 359 Eng_D_Stat 0 "EngOff" 1 "EngOn" 2 "EngAutoStopped" 3 "NotUsed" ;
VAL_ 359 PrplWhlTot2_Tq_Actl 65534 "NoDataExists" 65535 "Fault" ;
VAL_ 359 PrplWhlRgenMn_Tq_Actl 8191 "Faulty" ;
VAL_ 359 LscmbbEngTqMn_B_Actl 0 "Engine_Braking_Off" 1 "Engine_Braking_Activated" ;
VAL_ 359 LscmbbDeny_B_ActlPrpl 0 "Allowed" 1 "Denied" ;
VAL_ 359 ElPw_D_StatStrtStop 0 "Not_Supported" 1 "Supported_All" 2 "Not_Supported_Imminent" 3 "LV_Event_in_Progress" 4 "Fault_Limited" 5 "Limited_Support" 6 "Supported_Level_1" 7 "Supported_Level_2" 8 "Supported_Level_3" 9 "Supported_Level_4" 10 "NotUsed1" 11 "NotUsed2" 12 "NotUsed3" 13 "NotUsed4" 14 "NotUsed5" 15 "NotUsed6" ;
VAL_ 359 TrnAinTq_D_Qf 0 "Faulty" 1 "No_Data_Exists" 2 "Not_Within_Specifications" 3 "OK" ;
VAL_ 360 TrnTrcmPwmSig_D_Actl 0 "No_Gear" 1 "Park" 2 "Reverse" 3 "Neutral" 4 "Drive" 5 "Manual" 6 "Car_Wash_Mode" 7 "Neutral_Tow" 8 "Default_To_Park" 9 "NotUsed1" 10 "NotUsed2" 11 "NotUsed3" 12 "NotUsed4" 13 "NotUsed5" 14 "NoDataExists" 15 "Faulty" ;
VAL_ 360 PrkBrkActv_D_RqGsmGear 0 "Null" 1 "NoRequest" 2 "RequestParkBrakeEngage" 3 "NotUsed" ;
VAL_ 360 GearButtnStuck_B_Actl 0 "No" 1 "Yes" ;
VAL_ 360 TrnGearPwmFalt_B_Actl 0 "No" 1 "Yes" ;
VAL_ 360 PrkBrkButtn_D_Stat 0 "NotPressed" 1 "Pressed" 2 "NotUsed" 3 "Faulty" ;
VAL_ 360 GsmSrvcRqd_B_Rq 0 "No" 1 "Yes" ;
VAL_ 367 AuthctnInfo_D_Stat 0 "Null" 1 "NotAuthenticated" 2 "AuthenticationFailed" 3 "Authenticated" ;
VAL_ 367 AuthctnStat_D_Stat 0 "Null" 1 "NotAuthenticated" 2 "AuthenticationFailed" 3 "Authenticated" ;
VAL_ 367 AuthctnInfoLoc_D_Stat 0 "Null" 1 "Interior" 2 "Driver" 3 "Passenger" 4 "RearExterior" 5 "RearInterior" 6 "Approach" 7 "NotUsed_1" ;
VAL_ 367 AuthctnStatChnl_D_Stat 0 "Null" 1 "Mobile" 2 "DAP_L" 3 "DAP_R" 4 "SDM_A" 5 "SDM_B" 6 "SDM_C" 7 "SDM_D" 8 "Sync" 9 "NotUsed_1" 10 "NotUsed_2" 11 "NotUsed_3" 12 "NotUsed_4" 13 "NotUsed_5" 14 "NotUsed_6" 15 "NotUsed_7" ;
VAL_ 367 ApnlPsswrdType_D_Stat 0 "Null" 1 "Rider" 2 "RiderBackup" 3 "Loader" 4 "LoaderBackup" 5 "Unloader" 6 "UnloaderBackup" 7 "Service" 8 "ServiceVehicleBackup" 9 "Driver" 10 "DriverVehicleBackup" 11 "Elevated" 12 "ElevatedVehicleBackup" 13 "NotUsed_1" 14 "NotUsed_2" 15 "NotUsed_3" ;
VAL_ 367 HashIndx_D_Stat 0 "Null" 1 "Failed" 2 "NotValid" 3 "Success" ;
VAL_ 369 TrnIpcDsplyGear_D_Stat 0 "Blank_No_Display" 1 "On" 2 "Flash" 3 "Reserved_Blank_No_Display" ;
VAL_ 369 TrnIpcDsplyMde_D_Stat 0 "Blank_No_Display" 1 "On" 2 "Flash" 3 "Reserved_Blank_No_Display" ;
VAL_ 369 TrnIpcDsplyGear_D_Actl 0 "Neutral" 1 "1st_Gear" 2 "2nd_Gear" 3 "3rd_Gear" 4 "4th_Gear" 5 "5th_Gear" 6 "6th_Gear" 7 "7th_Gear" 8 "8th_Gear" 9 "9th_Gear" 10 "10th_Gear" 11 "11th_Gear" 12 "12th_Gear" 13 "13th_Gear" 14 "14th_Gear" 15 "No_Gear_Selected" ;
VAL_ 369 TrnIpcDsplyRng_D_Stat 0 "Blank_No_Display" 1 "On" 2 "Flash" 3 "NotUsed" ;
VAL_ 369 DrvPerfMde_D_DsplyPt 0 "NoModeSelected" 1 "NotUsed" 2 "Normal" 3 "Sport" ;
VAL_ 369 SeatWorkSrfc_B_Falt 0 "Inactive" 1 "Active" ;
VAL_ 369 TrnIpcDsplyMde_D_Actl 0 "Park" 1 "Reverse" 2 "Neutral" 3 "Drive" 4 "Sport" 5 "Manual_1_Low" 6 "Manual_2" 7 "Manual_3" ;
VAL_ 369 TrnIpcDsplyRng2_D_Actl 0 "NotUsed" 1 "Range_1" 2 "Range_2" 3 "Range_3" 4 "Range_4" 5 "Range_5" 6 "Range_6" 7 "Range_7" 8 "Range_8" 9 "Range_9" 10 "Range_10" 11 "Range_11" 12 "Range_12" 13 "Range_13" 14 "Range_14" 15 "No_Range_Selected" ;
VAL_ 369 CrawlMdeActv_B_Stat 0 "Off" 1 "On" ;
VAL_ 373 EngTeColdPrtct_D_Stats 0 "Normal_Operation" 1 "Engine_Warm_PlsWait" 2 "OK_to_Drive" 3 "Engine_Warm_RdcPwr" ;
VAL_ 373 DieslPrtcRgen_D_Rq 0 "Normal_Mode_NoRegen" 1 "HeatUp_1" 2 "HeatUp_2" 3 "HeatUp_3" 4 "Full_Regen_1" 5 "Full_Regen_2" 6 "Unused_1" 7 "Unused_2" ;
VAL_ 373 EngPtoMde_D_Rq 0 "Off" 1 "BCP" 2 "PTO_Stationary" 3 "Not_Used_1" 4 "PTO_Mobile" 5 "Not_Used_2" 6 "Split_Shaft_Stationary" 7 "Undefined" ;
VAL_ 373 EngFuelCutFull_B_Allw 0 "No" 1 "Yes" ;
VAL_ 373 EngTurboMde_D_Actl 0 "Initializing" 1 "Two_Turbos_Active" 2 "One_Turbo_Active" 3 "Fault" ;
VAL_ 373 DieslPrtcRgen_D_Actl 0 "No_regen" 1 "Regen_Level_1" 2 "Regen_Level_2" 3 "Undefined" ;
VAL_ 373 EngExhOvrTe_B_RqDsply 0 "Inactive" 1 "Active" ;
VAL_ 373 DieslPrtc2_D_RqDsply 0 "DPF_Normal_Operation" 1 "DPF_Overloaded" 2 "Cleaning_Exhaust_Filter" 3 "ExhFilter_Drive_Completed" 4 "DPF_AtLimit" 5 "DPF_Overlimit" 6 "Exhaust_Filter_Full" 7 "RgnOff_Loaded" 8 "RgnOff_Overloaded" 9 "RgnOff_AtLimit" 10 "OCR_ExhFilterCleaned" 11 "OCR_ExhFilterClean_Stopped" 12 "NotUsed1" 13 "NotUsed2" 14 "NotUsed3" 15 "NotUsed4" ;
VAL_ 373 DieslPrtc_D_RqDsply 0 "DPF_OK_Normal_Operation" 1 "DPF_Soot_Level1_Overloaded" 2 "DPFRegen_CleanExhFilter" 3 "DPFRegen_ExhFilterComplete" 4 "DPFSootLvl2_SevereOverload" 5 "DPF_SOOT_Level3_Blocked" 6 "Unused_1" 7 "Unused_2" ;
VAL_ 374 GearPos_D_Actl 0 "Neutral" 1 "First" 2 "Second" 3 "Third" 4 "Fourth" 5 "Fifth" 6 "Sixth" 7 "Seventh" 8 "Eighth" 9 "Ninth" 10 "Tenth" 11 "Undefined_3" 12 "Undefined_4" 13 "Undefined_5" 14 "Reverse" 15 "Unknown" ;
VAL_ 374 GearLvr_D_ActlDrv 0 "Park" 1 "Reverse" 2 "Neutral" 3 "Drive" 4 "Sport_DriveSport_Mposition" 5 "Low" 6 "Range1_M1_L1" 7 "Range2_M2_L2" 8 "Range3_M3_L3" 9 "Range4" 10 "Range5" 11 "Range6" 12 "NotUsed_1" 13 "NotUsed_2" 14 "Unknown_Position" 15 "Fault" ;
VAL_ 374 GearPos_D_Trg 0 "Neutral" 1 "First" 2 "Second" 3 "Third" 4 "Fourth" 5 "Fifth" 6 "Sixth" 7 "Seventh" 8 "Eighth" 9 "Ninth" 10 "Tenth" 11 "Undefined_3" 12 "Undefined_4" 13 "Undefined_5" 14 "Reverse" 15 "Unknown" ;
VAL_ 374 TrnRng_D_Rq 0 "Park" 1 "Reverse" 2 "Neutral" 3 "Drive" 4 "Sport_DriveSport_Mposition" 5 "Low" 6 "Range1_M1_L1" 7 "Range2_M2_L2" 8 "Range3_M3_L3" 9 "Range4" 10 "Range5" 11 "Range6" 12 "NotUsed_1" 13 "NotUsed_2" 14 "Unknown_Position" 15 "Fault" ;
VAL_ 374 TrnPrkSys_D_Actl 0 "NotKnown" 1 "Park" 2 "TransitionCloseToPark" 3 "AtNoSpring" 4 "TransitionCloseToOutOfPark" 5 "OutOfPark" 6 "Override" 7 "OutOfRangeLow" 8 "OutOfRangeHigh" 9 "FrequencyError" 10 "NotUsed_1" 11 "NotUsed_2" 12 "NotUsed_3" 13 "NotUsed_4" 14 "NotUsed_5" 15 "Faulty" ;
VAL_ 374 TrnRngeSrc_D_Rq 0 "Null" 1 "Invalid" 2 "User" 3 "Internal" 4 "External" 5 "NotUsed_1" 6 "NotUsed_2" 7 "NotUsed_3" ;
VAL_ 374 GearEngag_D_Actl 0 "Park_Neutral" 1 "InitializeFwdClutchEngagmt" 2 "Engagement_in_Progress" 3 "Disengaged_to_Neutral_Park" 4 "Disengaged_to_Neutral_Idle" 5 "Neutral_Idle" 6 "Fwd_Clutch_Fully_Engaged" 7 "Undefined" ;
VAL_ 376 HvacHtrCore2_Te_Actl 1023 "Faulty" ;
VAL_ 376 AslIconDsply_D_Rq 0 "Off" 1 "On_Passive" 2 "On_Active" 3 "On_Passive_Overridden" ;
VAL_ 376 DynoMde_B_Cmd 0 "NormalOperation" 1 "DynomometerMode" ;
VAL_ 376 LnchCtlSys_D_Stat 0 "LC_OFF" 1 "On_LC_Active" 2 "On_LC_Available" 3 "On_LC_Unavailable" 4 "On_LC_Unavailable_TC_On" 5 "On_LC_Available_TC_Off" 6 "On_LC_Unavailable_TC_Off" 7 "NotUsed" ;
VAL_ 376 EcssLamp_D_RqDsply 0 "Off" 1 "On" 2 "Flash" 3 "Not_Used" ;
VAL_ 376 GasPrtc_D_RqDsply 0 "NormalOperation" 1 "GpfAtLimit" 2 "GpfOverLimit" 3 "NotUsed_1" 4 "NotUsed_2" 5 "NotUsed_3" 6 "NotUsed_4" 7 "NotUsed_5" ;
VAL_ 376 AirAmbTe_D_Qf 0 "Faulty" 1 "No_Data_Exists" 2 "Not_Within_Specifications" 3 "OK" ;
VAL_ 376 PtcHtr_D_Cmd 0 "NoDecision_Initializing" 1 "TurnOff" 2 "AutoMode" 3 "TurnOn" ;
VAL_ 376 AslChime_B_Rq 0 "No" 1 "Yes" ;
VAL_ 376 AirAmb_P_Actl 62 "NoDataExists" 63 "Fault" ;
VAL_ 377 EngAoutTqActl_D_Qf 0 "Faulty" 1 "No_Data_Exists" 2 "Not_Within_Specifications" 3 "OK" ;
VAL_ 377 TrnManShif_D_IndDrv 0 "No_Indication" 1 "Upshift_Fuel_Economy" 2 "Upshift_Performance" 3 "Upshift_Warning" 4 "Downshift_Recommendation" 5 "Shift_to_Neutral" 6 "Undefined_2" 7 "Undefined_3" ;
VAL_ 377 EngSrvcRqd_B_Rq 0 "No_engine_service_required" 1 "Engine_Service_Required" ;
VAL_ 377 TrnKickDown_B_RqDrv 0 "No" 1 "Yes" ;
VAL_ 377 EngDecelFuelCut_B_Allw 0 "No" 1 "Yes" ;
VAL_ 377 EngFuelCutFull_B_Inhbt 0 "Normal" 1 "Inhibit_DFSO" ;
VAL_ 377 HvacAirFullOut_B_Rq 0 "No" 1 "Yes" ;
VAL_ 377 FuelFillInlet_B_Dsply 0 "No" 1 "Yes" ;
VAL_ 377 OdoCount 255 "Invalid" ;
VAL_ 377 FuelFilterLamp_B_Dsply 0 "Off" 1 "On" ;
VAL_ 377 AirCondClutch_B_Stats 0 "No" 1 "Yes" ;
VAL_ 377 TrnManShifGear_D_IndDrv 0 "No_Indication" 1 "Indicate_Gear1" 2 "Indicate_Gear2" 3 "Indicate_Gear3" 4 "Indicate_Gear4" 5 "Indicate_Gear5" 6 "Indicate_Gear6" 7 "Indicate_Reverse_Gear" ;
VAL_ 377 AirCondRec_B_Rq 0 "No" 1 "Yes" ;
VAL_ 380 EngExhBrkAutoLamp_B_Rq 0 "Off" 1 "On" ;
VAL_ 380 EngExhBrkOnLamp_B_Rq 0 "Off" 1 "On" ;
VAL_ 380 EngExhBrkMde_D_Actl 0 "ExhBrkUnavailable_Error" 1 "ExhBrkNoRequest_OFF" 2 "ExhBrkRequest_ON" 3 "ExhBrkRequest_AUTO" 4 "ExhBrkActive_ON" 5 "ExhBrkActive_AUTO" 6 "ExhBrkDisable_NoError" ;
VAL_ 380 PwStep_D_DrvInhbt 0 "DriveNotInhibited" 1 "DriveInhibited" 2 "DriveInhibitMalfunction" 3 "NotUsed" ;
VAL_ 380 GrdAsstAllw_D_DsplyPt 0 "NoModeSelected" 1 "Off" 2 "On" 3 "NotUsed" ;
VAL_ 380 WhlRearDual_D_Stat 0 "NoDataExists" 1 "Single" 2 "Dual" 3 "NotUsed" ;
VAL_ 380 FuelMaintMde_D_Rq 0 "NoRequest" 1 "Fuel_Maint_Req_Soon" 2 "Fuel_Maint_Req_Now" 3 "Feature_Not_Present" ;
VAL_ 380 EngOilLvlWarn_D_Rq1 0 "No_Message" 1 "Engine_Oil_Low" 2 "Engine_Oil_Critical_Low" 3 "Engine_Oil_High" 4 "Engine_Oil_Critical_High" 5 "Engine_Oil_Monitor_Fault" 6 "Undefined_2" 7 "Undefined_3" ;
VAL_ 381 RunDryPrevent_B_Stat 0 "False" 1 "True" ;
VAL_ 381 GlowIndication 0 "Off" 1 "On" ;
VAL_ 381 WaterInFuel 0 "Off" 1 "On" ;
VAL_ 381 EngOilSrvcMsgTxt_D_Rq 0 "NoText" 1 "ChangeOilSoon" 2 "ChangeOilNow" 3 "ResetInProgress" 4 "ResetComplete" 5 "ResetFailed" 6 "OilMinderNotConfigured" 7 "NotUsed_1" ;
VAL_ 382 EngInnrClnt_Te_Actl 126 "NoDataExists" 127 "Faulty" ;
VAL_ 382 EngMnfldChrg_Te_Actl 126 "NoDataExists" 127 "Faulty" ;
VAL_ 382 DcacOut1_Pw2_Dsply 8190 "NoDataExists" 8191 "Faulty" ;
VAL_ 382 EngIdlShutDown_D2_Type 0 "Null" 1 "Keyed" 2 "Keyless" 3 "Fleet" ;
VAL_ 382 DcacOut2_Pw2_Dsply 8190 "NoDataExists" 8191 "Faulty" ;
VAL_ 383 HeadLghtCtl_D_RqMnu 0 "Null" 1 "Off" 2 "ParkLamp" 3 "AutoLamp" 4 "HeadLamp" 5 "NotUsed_1" 6 "NotUsed_2" 7 "Faulty" ;
VAL_ 385 ChrgGlblAc_I_Mx 255 "Faulty" ;
VAL_ 385 ChrgGlblDc_Pw_Mx 127 "Faulty" ;
VAL_ 386 Chrg_I_Dsply 511 "Faulty" ;
VAL_ 386 Chrg_U_Dsply 1023 "Faulty" ;
VAL_ 386 Chrg_V_Dsply 262143 "Faulty" ;
VAL_ 387 ChrgGlblRcmd_I_Dsply 255 "Fault" ;
VAL_ 387 AcMx_I_Dsply 255 "Fault" ;
VAL_ 387 ChrgGlblRcmd_Pw_Dsply 127 "Faulty" ;
VAL_ 387 DcMx_Pw_Dsply 127 "Faulty" ;
VAL_ 389 PtWakeupDeltaT_T_Rq 2046 "NoDataExists" 2047 "Fault" ;
VAL_ 389 HtrnSrvcRqd_B_Dsply 0 "Off" 1 "On" ;
VAL_ 389 HtrnOvrTeLamp_B_Dsply 0 "Off" 1 "On" ;
VAL_ 389 HtrnMil_D_Rq 0 "Off" 1 "On" 2 "Flash" 3 "Not_Used" ;
VAL_ 389 BattTrac_I_EstVsc 32766 "NoDataExists" 32767 "Fault" ;
VAL_ 389 HtrnHvilOpen_B_Actl 0 "Normal_Operation" 1 "HVIL_is_Open" ;
VAL_ 389 HtrnAin_UHi_Actl 1022 "Unknown" 1023 "Fault" ;
VAL_ 389 HtrnHvilState_D_Stat 0 "Normal_Operation" 1 "HVIL_Is_Open" 2 "NoDataExists" 3 "Faulty" ;
VAL_ 389 DrvCondTpRrDefrs_B_Rq 0 "Off" 1 "On" ;
VAL_ 389 PreCondActv_B_Actl 0 "Off" 1 "On" ;
VAL_ 391 ACU_CtrlChimeChan_Rq 0 "Inactive" 1 "Mute" 2 "Reserved1" 3 "Reserved2" ;
VAL_ 394 AccStopMde_B_Dsply 0 "No" 1 "Yes" ;
VAL_ 394 FcwMsgTxt_D_Rq 0 "No_Text" 1 "Off" 2 "Unavailable" 3 "Available" 4 "Unavailable_DueTo_LowSpeed" 5 "Low_Visibility" 6 "Undefined_2" 7 "Undefined_3" ;
VAL_ 394 FcwAudioWarn_B_Rq 0 "Off" 1 "On" ;
VAL_ 394 CmbbPostEvntRl_B_Dsply 0 "No" 1 "Yes" ;
VAL_ 394 FcwDeny_B_Dsply 0 "No" 1 "Yes" ;
VAL_ 394 CadsAlignIncplt_B_Actl 0 "No" 1 "Yes" ;
VAL_ 394 PcaVisblWarnRr_B_Rq 0 "No" 1 "Yes" ;
VAL_ 394 FcwMemStat_B_Actl 0 "Off" 1 "On" ;
VAL_ 394 PcaVisblWarnRl_B_Rq 0 "No" 1 "Yes" ;
VAL_ 394 CmbbPostEvnt_B_Dsply 0 "No" 1 "Yes" ;
VAL_ 394 AccFllwMde_B_Dsply 0 "No" 1 "Yes" ;
VAL_ 394 FcwMemSens_D_Actl 0 "Not_Used" 1 "FCW_Sensitivity_1" 2 "FCW_Sensitivity_2" 3 "FCW_Sensitivity_3" ;
VAL_ 394 PcaAudioWarnRear_B_Rq 0 "No" 1 "Yes" ;
VAL_ 394 CadsRadrBlck_B_Actl 0 "No" 1 "Yes" ;
VAL_ 394 CmbbPostEvntRr_B_Dsply 0 "No" 1 "Yes" ;
VAL_ 394 AccTrgDist2_D_Dsply 0 "DIST_OFF" 1 "DIST_STANDBY" 2 "DIST_ACTIVE_No_Target" 3 "DIST_ACTIVE_1_Closest" 4 "DIST_ACTIVE_2" 5 "DIST_ACTIVE_3" 6 "DIST_ACTIVE_4" 7 "DIST_ACTIVE_5" 8 "DIST_ACTIVE_6" 9 "DIST_ACTIVE_7" 10 "DIST_ACTIVE_8" 11 "DIST_ACTIVE_9" 12 "DIST_ACTIVE_10" 13 "DIST_ACTIVE_11" 14 "DIST_ACTIVE_12" 15 "DIST_ACTIVE_13_Farthest" ;
VAL_ 394 AccMsgTxt_D2_Rq 0 "No_Text" 1 "ACC_Unavailable" 2 "ACC_Cancelled" 3 "Brake_Capacity_Warning" 4 "ACC_Overridden" 5 "ACC_Selected" 6 "IACC_Unavailable" 7 "Shift_Down" 8 "TJA_Unavailable" 9 "Only_Following_In_Low_Spd" 10 "Press_Brake_To_Hold" 11 "IACC_Selected" 12 "ACC_TJA_Selected" 13 "IACC_TJA_Selected" 14 "NCC_Enabled_Warning" 15 "Brakes_Warm" ;
VAL_ 394 AccTGap_D_Dsply 0 "Not_Used" 1 "Time_Gap_1" 2 "Time_Gap_2" 3 "Time_Gap_3" 4 "Time_Gap_4" 5 "Time_Gap_5" 6 "Undefined_1" 7 "Undefined_2" ;
VAL_ 394 AccTGap_B_Dsply 0 "No" 1 "Yes" ;
VAL_ 394 AccMemEnbl_B_RqDrv 0 "Normal_Cruise" 1 "Adaptive_Cruise" ;
VAL_ 394 AccWarn_D_Dsply 0 "No_Warning" 1 "Cancel_Warning" 2 "Brake_Capacity_Warning" 3 "BrakeReleaseWarn_In_StopMd" ;
VAL_ 394 AccStopStat_D_Dsply 0 "NoDisplay" 1 "ResumeReady" 2 "Stopped" 3 "PressResume" ;
VAL_ 394 Tja_D_Stat 0 "Off" 1 "Standby" 2 "Active" 3 "ActiveInterventionLeft" 4 "ActiveInterventionRight" 5 "ActiveWarningLeft" 6 "ActiveWarningRight" 7 "ExtendedActive" ;
VAL_ 394 IaccLamp_D_Rq 0 "DoNotDisplayIaccIcon" 1 "DisplayIaccIcon" 2 "NotUsed_1" 3 "NotUsed_2" ;
VAL_ 394 FcwVisblWarn_B_Rq 0 "Off" 1 "On" ;
VAL_ 394 TjaWarn_D_Rq 0 "NoWarning" 1 "TrafficJamAssistCancel" 2 "HardTakeOverLevel1" 3 "HardTakeOverLevel2" 4 "HaLaneDeptWarningRight" 5 "HaLaneDeptWarningLeft" 6 "SoftTakeOverEyesOff" 7 "HardTakeOverEyesOff" ;
VAL_ 394 TjaMsgTxt_D_Dsply 0 "NoMessage" 1 "TrafficJamAssistUnavailabl" 2 "TrafficJamAssistSelected" 3 "TurnOnAdaptCruiseControl" 4 "HaUnavailable" 5 "HaSelected" 6 "SmartOffering" 7 "Disclaimer" ;
VAL_ 394 AccStopRes_B_Dsply 0 "No" 1 "Yes" ;
VAL_ 395 HudLed8On_B_Rq 0 "Off" 1 "On" ;
VAL_ 395 HudLed7On_B_Rq 0 "Off" 1 "On" ;
VAL_ 395 HudLed6On_B_Rq 0 "Off" 1 "On" ;
VAL_ 395 HudLed5On_B_Rq 0 "Off" 1 "On" ;
VAL_ 395 HudLed4On_B_Rq 0 "Off" 1 "On" ;
VAL_ 395 HudLed3On_B_Rq 0 "Off" 1 "On" ;
VAL_ 395 HudLed2On_B_Rq 0 "Off" 1 "On" ;
VAL_ 395 HudLed1On_B_Rq 0 "Off" 1 "On" ;
VAL_ 395 HudLed16On_B_Rq 0 "Off" 1 "On" ;
VAL_ 395 HudLed15On_B_Rq 0 "Off" 1 "On" ;
VAL_ 395 HudLed14On_B_Rq 0 "Off" 1 "On" ;
VAL_ 395 HudLed13On_B_Rq 0 "Off" 1 "On" ;
VAL_ 395 HudLed12On_B_Rq 0 "Off" 1 "On" ;
VAL_ 395 HudLed11On_B_Rq 0 "Off" 1 "On" ;
VAL_ 395 HudLed10On_B_Rq 0 "Off" 1 "On" ;
VAL_ 395 HudLed9On_B_Rq 0 "Off" 1 "On" ;
VAL_ 395 HudLed17On_B_Rq 0 "Off" 1 "On" ;
VAL_ 395 HudLedMde_D_Rq 0 "Off" 1 "On" 2 "Flash" 3 "Not_Used" ;
VAL_ 395 SelDrvMdeCnfm_D_Stat 0 "Null" 1 "NotAccepted" 2 "Accepted" 3 "NotUsed" ;
VAL_ 395 HudMde_D_Rq 0 "Off" 1 "Tach" 2 "RoadCourse" 3 "Drag" 4 "Manual" 5 "NotUsed1" 6 "NotUsed2" 7 "NotUsed3" ;
VAL_ 395 HudLed18On_B_Rq 0 "Off" 1 "On" ;
VAL_ 400 Mc_PerTUPresetArea_Rq 0 "Inactive" 1 "GetFm1PresetData" 2 "GetFm2PresetData" 3 "GetFm3PresetData" 4 "GetFmAstPresetData" 5 "GetAmAstPresetData" 6 "GetAmPresetData" 7 "GetDAB3PresetData" 8 "GetDAB1PresetData" 9 "GetDAB2PresetData" 10 "GetSAT1PresetData" 11 "GetSAT2PresetData" 12 "GetSAT3PresetData" 13 "reserved" 15 "reserved_last" ;
VAL_ 400 Mc_SetCurrStatMCCh_Rq 0 "Inactive" 1 "MCChannel1" 2 "MCChannel2" 3 "MCChannel3" 4 "MCChannel4" 5 "MCChannel5" 6 "MCChannel6" 7 "MCChannel7" ;
VAL_ 400 Mc_SetCurrentStatOp_Rq 0 "Inactive" 1 "SetCurrentFrequency" 2 "SetCurrentPiCode" 3 "SetCurrentStation" ;
VAL_ 401 Disp_VehUntTripCoUsrSel 0 "Metric" 1 "Imperial" 3 "Inactive" ;
VAL_ 401 Disp_VehUnitTempUsrSel 0 "Celsius" 1 "Fahrenheit" 3 "Inactive" ;
VAL_ 401 Bezel_Beeps_Rq 0 "Inactive" 1 "Enable" 2 "Disable" ;
VAL_ 401 Disp_LangSel_Rq 0 "Invalid" 1 "Unknown" 2 "UK_English" 3 "NA_English" 4 "German" 5 "Italian" 6 "EU_French" 7 "Cana_French" 8 "EU_Spanish" 9 "Mex_Spanish" 10 "Turkish" 11 "Russian" 12 "Dutch" 13 "Flemish" 14 "Polish" 15 "Czech" 16 "Greek" 17 "Hungarian" 18 "Swedish" 19 "Danish" 20 "Norwegian" 21 "Finish" 22 "EU_Portuguese" 23 "Braz_Portuguese" 24 "Japanese" 25 "AU_English" 26 "Korean" 27 "Mandarin_Chinese" 28 "Taiwanese" 29 "Arabic" 30 "Slovak" 31 "Thai" ;
VAL_ 401 Disp_LangSel2_Rq 0 "Invalid" 1 "Unknown" 2 "UK_English" 3 "NA_English" 4 "German" 5 "Italian" 6 "EU_French" 7 "Cana_French" 8 "EU_Spanish" 9 "Mex_Spanish" 10 "Turkish" 11 "Russian" 12 "Dutch" 13 "Flemish" 14 "Polish" 15 "Czech" 16 "Greek" 17 "Hungarian" 18 "Swedish" 19 "Danish" 20 "Norwegian" 21 "Finish" 22 "EU_Portuguese" 23 "Braz_Portuguese" 24 "Japanese" 25 "AU_English" 26 "Korean" 27 "Mandarin_Chinese" 28 "Taiwanese" 29 "Arabic" 30 "Slovak" 31 "Thai" 32 "Indian_English" 33 "Ukrainian" 34 "Romanian" ;
VAL_ 402 ApaMdeStat_D_RqDrv 0 "Inactive" 1 "SAPP" 2 "PPA" 3 "POA" 4 "NotUsed1" 5 "NotUsed2" 6 "Off" 7 "Faulty" ;
VAL_ 402 CamraViewSplit_B_Rq 0 "Off" 1 "On" ;
VAL_ 402 CamraOvrlStat_D_Rq 0 "Off" 1 "On" ;
VAL_ 402 DistanceBarSetting 0 "Off" 1 "On" ;
VAL_ 402 CamAutoTowbarZoom 0 "Off" 1 "On" ;
VAL_ 402 CamraOvrlDyn_D_Rq 0 "Off" 1 "On" ;
VAL_ 402 CamraFrntBttn_D_Stat3 0 "Not_Pressed" 1 "Pressed" ;
VAL_ 402 ApaSwtch_D_RqMnu 0 "Not_Pressed" 1 "Pressed" 2 "NotUsed1" 3 "NotUsed2" ;
VAL_ 402 PrkAidSwtch_D_RqMnu 0 "Not_Pressed" 1 "Pressed" ;
VAL_ 402 TrayTbleManOvrrd_B_Rq 0 "Null" 1 "Override" ;
VAL_ 402 CamraZoomMan_D_Rq 0 "Off" 1 "Zoom_Level_I" 2 "Zoom_Level_II" 3 "Zoom_Level_III" 4 "Zoom_Level_IV" 5 "Zoom_Level_V" 6 "Invalid" 7 "Unknown" ;
VAL_ 402 ApaSlotTrgt_D_RqDrv 0 "None" 1 "Left1" 2 "Left2" 3 "Left3" 4 "Right1" 5 "Right2" 6 "Right3" 7 "Rear" 8 "Front" 9 "NotUsed_1" 10 "NotUsed_2" 11 "NotUsed_3" 12 "NotUsed_4" 13 "NotUsed_5" 14 "NotUsed_6" 15 "NotUsed_7" ;
VAL_ 402 ApaFeat_D_RqDrv 0 "Inactive" 1 "SAPP" 2 "PPA" 3 "POA" 4 "ParkIn" 5 "RePA" 6 "Off" 7 "Faulty" ;
VAL_ 402 ApaFeatChange_B_RqDrv 0 "False" 1 "True" ;
VAL_ 402 SodChimeEnbl_D_Rq 0 "Null" 1 "Disable" 2 "Enable" 3 "NotUsed" ;
VAL_ 402 ApaSlotAlrtSet_D_RqDrv 0 "None" 1 "Enable" 2 "Disable" 3 "TemporarySuppression" ;
VAL_ 403 DealerCall_B_Rq 0 "Null" 1 "Yes" ;
VAL_ 403 Mc_PhMicrophoneMute_Rq 0 "Inactive" 1 "MicrophoneMute" 2 "MicrophoneUnmute" 3 "Reserved" ;
VAL_ 403 Mc_CancelCurrWaypt_Rq 0 "Inactive" 1 "Cancel" ;
VAL_ 403 McLangSel2_Rq 0 "Invalid" 1 "Unknown" 2 "UK_English" 3 "NA_English" 4 "German" 5 "Italian" 6 "EU_French" 7 "Cana_French" 8 "EU_Spanish" 9 "Mex_Spanish" 10 "Turkish" 11 "Russian" 12 "Dutch" 13 "Flemish" 14 "Polish" 15 "Czech" 16 "Greek" 17 "Hungarian" 18 "Swedish" 19 "Danish" 20 "Norwegian" 21 "Finish" 22 "EU_Portuguese" 23 "Braz_Portuguese" 24 "Japanese" 25 "AU_English" 26 "Korean" 27 "Mandarin_Chinese" 28 "Taiwanese" 29 "Arabic" 30 "Slovak" 31 "Thai" 32 "Indian_English" 33 "Ukrainian" 34 "Romanian" ;
VAL_ 403 Mc_LangSel_Rq 0 "Invalid" 1 "Unknown" 2 "UK_English" 3 "NA_English" 4 "German" 5 "Italian" 6 "EU_French" 7 "Cana_French" 8 "EU_Spanish" 9 "Mex_Spanish" 10 "Turkish" 11 "Russian" 12 "Dutch" 13 "Flemish" 14 "Polish" 15 "Czech" 16 "Greek" 17 "Hungarian" 18 "Swedish" 19 "Danish" 20 "Norwegian" 21 "Finish" 22 "EU_Portuguese" 23 "Braz_Portuguese" 24 "Japanese" 25 "AU_English" 26 "Korean" 27 "Mandarin_Chinese" 28 "Taiwanese" 29 "Arabic" 30 "Slovak" 31 "Thai" ;
VAL_ 403 Mc_BTInCallOptions_Rq 0 "Inactive" 1 "SwitchCalls" 2 "JoinCalls" 3 "GotoPrivacyMode" 4 "GotoHandsfreeMode" 5 "HoldCall" 6 "EndHoldCall" ;
VAL_ 403 Mc_TextMessage_Rq 0 "Invalid" 1 "Listen" 2 "Ignore" 3 "Cancel" ;
VAL_ 403 Mc_CancelRoute_Rq 0 "Inactive" 1 "Cancel" ;
VAL_ 403 Mc_RepeatGuidance_Rq 0 "Inactive" 1 "Active" ;
VAL_ 404 Dsp_LangUpdate_Rsp 0 "Inactive" 1 "Language_Updated" 2 "Language_Not_Supported" ;
VAL_ 410 DoNotDisturbOveride_St 0 "No_Data_Exists" 1 "Off" 2 "On" ;
VAL_ 410 MyKey_e911Override_St 0 "No_Data_Exists" 1 "Off" 2 "On" ;
VAL_ 413 LBS1_ListStatus 0 "Inactive" 1 "Valid" 2 "Updating" 3 "Reserved" ;
VAL_ 414 LBS2_ListStatus 0 "Inactive" 1 "Valid" 2 "Updating" 3 "Reserved" ;
VAL_ 415 LBC3_Opcode 0 "Inactive" 1 "GetItemInfo_Rq" 2 "SetItemIfno_Rq" 3 "NotUsed" ;
VAL_ 419 MK_DNDRestrictConf_Rq 0 "Inactive" 1 "Off" 2 "On" ;
VAL_ 419 MK_CreateMyKey_Rq 0 "Inactive" 1 "Create" ;
VAL_ 419 MK_AudioLimitConfig_Rq 0 "Inactive" 1 "Off" 2 "On" ;
VAL_ 419 MK_ACSRestrictConf_Rq 0 "Inactive" 1 "Off" 2 "On" ;
VAL_ 419 MK_ResetAllUserKeys_Rq 0 "Inactive" 1 "ResetAllKeys" ;
VAL_ 419 MK_MyKeySystemInfo_Rq 0 "Inactive" 1 "GetData" ;
VAL_ 419 MK_ESCRestrictConf_Rq 0 "Inactive" 1 "Off" 2 "On" ;
VAL_ 419 MK_ECalRestrictConf_Rq 0 "Inactive" 1 "Off" 2 "On" ;
VAL_ 419 MK_SpeedSetting_Rq 0 "Inactive" 1 "SpeedLimit" 2 "SpeedMinder" 3 "Reserved" 15 "Reserved_last" ;
VAL_ 419 MK_SpeedValue_Rq 0 "Off" 1 "kmh70" 2 "kmh75" 3 "kmh80" 4 "kmh85" 5 "kmh90" 6 "kmh95" 7 "Kmh100" 8 "Kmh105" 9 "Kmh110" 10 "Kmh115" 11 "Kmh120" 12 "Kmh125" 13 "Kmh130" 14 "Kmh135" 15 "Kmh140" 16 "Kmh145" 17 "Kmh150" 18 "Kmh155" 19 "Kmh160" 20 "Kmh165" 21 "mph40" 22 "mph45" 23 "mph50" 24 "mph55" 25 "mph60" 26 "mph65" 27 "mph70" 28 "mph75" 29 "mph80" 30 "mph85" 31 "mph90" ;
VAL_ 422 MK_UserMyKeyCount_Rsp 0 "Zero" 1 "One" 2 "Two" 3 "Three" 4 "Four" 5 "Five" 6 "Six" 7 "Seven" 8 "Eight" 9 "Nine" 10 "Ten" 11 "Eleven" 12 "Twelve" 13 "Thirteen" 14 "Unlimited" 15 "Inactive" ;
VAL_ 422 MK_CreateMyKey_Rsp 0 "Inactive" 1 "KeyInSlotAlreadyMyKey" 2 "NoKeyInSlot" 3 "GenericFailure" 4 "Success" 5 "NotUsed_1" 6 "NotUsed_2" 7 "NotUsed_3" ;
VAL_ 422 MK_AdminMyKeyCount_Rsp 0 "Zero" 1 "One" 2 "Two" 3 "Three" 4 "Four" 5 "Five" 6 "Six" 7 "Seven" 8 "Eight" 9 "Nine" 10 "Ten" 11 "Eleven" 12 "Twelve" 13 "Thirteen" 14 "Unlimited" 15 "Inactive" ;
VAL_ 448 SeatThghLExtnDrv_Pc_Act 15 "Faulty" ;
VAL_ 448 SeatSetNotfnDrv_D_Rq 0 "Inactive" 1 "Pop_1" 2 "Pop_2" 3 "NotUsed_1" ;
VAL_ 448 StmsDrv_D_Stat 0 "Null" 1 "Low" 2 "Medium" 3 "High" ;
VAL_ 448 SeatSetMnuDrv_D_Stat 0 "Inactive" 1 "Massage_Menu" 2 "Seat_Back_Menu" 3 "Seat_Cushion_Menu" 4 "Headrestraint_Menu" 5 "NotUsed_1" 6 "NotUsed_2" 7 "NotUsed_3" ;
VAL_ 448 SeatDevcSetDrv_D_Stat 0 "Inactive" 1 "Upper_Thoracic" 2 "Left_Thigh_Extension" 3 "Right_Thigh_Extension" 4 "Calf_Raise_Extension" 5 "Upper_Lumbar" 6 "Mid_Lumbar" 7 "Lower_Lumbar" 8 "Back_Bolsters" 9 "Cushion_Bolsters" 10 "Headrest" 11 "Lumbar" 12 "Pattern_1" 13 "Pattern_2" 14 "Pattern_3" 15 "Pattern_4" 16 "Pattern_5" 17 "Pattern_6" 18 "Pattern_7" 19 "Pattern_8" 20 "Pattern_9" 21 "Pattern_10" 22 "NotUsed_1" 23 "NotUsed_2" 24 "NotUsed_3" 25 "NotUsed_4" 26 "NotUsed_5" 27 "NotUsed_6" 28 "NotUsed_7" 29 "NotUsed_8" 30 "NotUsed_9" 31 "NotUsed_10" ;
VAL_ 448 StmsDrv_D2_Stat 0 "Null" 1 "Off" 2 "Low" 3 "Medium" 4 "High" 5 "NotUsed_1" 6 "NotUsed_2" 7 "NotUsed_3" ;
VAL_ 448 SeatThghRExtnDrv_Pc_Act 15 "Faulty" ;
VAL_ 448 SeatCalfRaisDrv_Pc_Act 126 "NoDataExists" 127 "Faulty" ;
VAL_ 448 SeatLmbrPosDrv_Pc_Actl 126 "NoDataExists" 127 "Faulty" ;
VAL_ 448 SeatDevcAdjDrv_D_Stat 0 "Inactive" 1 "Increase" 2 "Decrease" 3 "Not Used" ;
VAL_ 448 SeatThrcAdjDrv_Pc_Act 15 "Faulty" ;
VAL_ 450 SeatThghRExtnPsn_Pc_Act 15 "Faulty" ;
VAL_ 450 SeatCalfRaisPsn_Pc_Actl 126 "No Data Exists" 127 "Faulty" ;
VAL_ 450 SeatLmbrPosPsng_Pc_Act 126 "No Data Exists" 127 "Faulty" ;
VAL_ 450 SeatDevcSetPsngr_D_St 0 "Inactive" 1 "Upper_Thoracic" 2 "Left_Thigh_Extension" 3 "Right_Thigh_Extension" 4 "Calf_Raise_Extension" 5 "Upper_Lumbar" 6 "Mid_Lumbar" 7 "Lower_Lumbar" 8 "Back_Bolsters" 9 "Cushion_Bolsters" 10 "Headrest" 11 "Lumbar" 12 "Pattern_1" 13 "Pattern_2" 14 "Pattern_3" 15 "Pattern_4" 16 "Pattern_5" 17 "Pattern_6" 18 "Pattern_7" 19 "Pattern_8" 20 "Pattern_9" 21 "Pattern_10" 22 "NotUsed_1" 23 "NotUsed_2" 24 "NotUsed_3" 25 "NotUsed_4" 26 "NotUsed_5" 27 "NotUsed_6" 28 "NotUsed_7" 29 "NotUsed_8" 30 "NotUsed_9" 31 "NotUsed_10" ;
VAL_ 450 StmsPsngr_D_Stat 0 "Null" 1 "Low" 2 "Medium" 3 "High" ;
VAL_ 450 SeatSetMnuPsngr_D_Stat 0 "Inactive" 1 "Massage_Menu" 2 "Seat_Back_Menu" 3 "Seat_Cushion_Menu" 4 "Headrestraint_Menu" 5 "NotUsed_1" 6 "NotUsed_2" 7 "NotUsed_3" ;
VAL_ 450 SeatThrcAdjPsng_Pc_Act 15 "Faulty" ;
VAL_ 450 SeatDevcAdjPsngr_D_St 0 "Inactive" 1 "Increase" 2 "Decrease" 3 "Not Used" ;
VAL_ 450 SeatThghLExtnPsn_Pc_Act 15 "Faulty" ;
VAL_ 450 SeatSetNotfnPsngr_D_Rq 0 "Inactive" 1 "Pop_1" 2 "Pop_2" 3 "NotUsed_1" ;
VAL_ 450 StmsPsngr_D2_Stat 0 "Null" 1 "Off" 2 "Low" 3 "Medium" 4 "High" 5 "NotUsed_1" 6 "NotUsed_2" 7 "NotUsed_3" ;
VAL_ 452 SeatSetNotfnR2Drv_D_Rq 0 "Inactive" 1 "Pop_1" 2 "Pop_2" 3 "NotUsed_1" ;
VAL_ 452 SeatSetMnuR2Drv_D_Stat 0 "Inactive" 1 "Massage_Menu" 2 "Seat_Cushion_Menu" 3 "Chauffeur_Switch" ;
VAL_ 452 SeatCshnRclCtlPsn_D_Rq 0 "Inactive" 1 "Cushion_Forward" 2 "Cushion_Backward" 3 "Recliner_Forward" 4 "Recliner_Backward" 5 "NotUsed_1" 6 "NotUsed_2" 7 "NotUsed_3" ;
VAL_ 452 SeatDevcSetR2Drv_D_St 0 "Inactive" 1 "Upper_Thoracic" 2 "Left_Thigh_Extension" 3 "Right_Thigh_Extension" 4 "Calf_Raise_Extension" 5 "ChauffeurSwitch_Cushion" 6 "ChauffeurSwitch_Recliner" 7 "Upper_Lumbar" 8 "Mid_Lumbar" 9 "Lower_Lumbar" 10 "Back_Bolsters" 11 "Cushion_Bolsters" 12 "HeadRest" 13 "Lumbar" 14 "Pattern_1" 15 "Pattern_2" 16 "Pattern_3" 17 "Pattern_4" 18 "Pattern_5" 19 "Pattern_6" 20 "Pattern_7" 21 "Pattern_8" 22 "Pattern_9" 23 "Pattern_10" 24 "NotUsed_1" 25 "NotUsed_2" 26 "NotUsed_3" 27 "NotUsed_4" 28 "NotUsed_5" 29 "NotUsed_6" 30 "NotUsed_7" 31 "NotUsed_8" ;
VAL_ 452 SeatThgRExtnR2Drv_Pc_Act 15 "Faulty" ;
VAL_ 452 SeatThgLExtnR2Drv_Pc_Act 15 "Faulty" ;
VAL_ 452 SeatCalfRaisR2Drv_Pc_Act 126 "No Data Exists" 127 "Faulty" ;
VAL_ 452 StmsR2Drv_D_Stat 0 "Inactive" 1 "Enabling" 2 "Pitching" 3 "Pitched" 4 "Returning" 5 "Stopped" 6 "NotUsed_1" 7 "NotUsed_2" ;
VAL_ 452 SeatLatcWarnR2Drv_D_Rq 0 "Inactive" 1 "Warning_1" 2 "Warning_2" 3 "Warning_3" ;
VAL_ 452 SeatSlidDrv_D_Rq 0 "Inactive" 1 "Enabling" 2 "Pitching" 3 "Pitched" 4 "Returning" 5 "Stopped" 6 "NotUsed_1" 7 "NotUsed_2" ;
VAL_ 452 SeatDevcAdjR2Drv_D_St 0 "Inactive" 1 "Increase" 2 "Decrease" 3 "Not Used" ;
VAL_ 452 StmsR2Drv_D2_Stat 0 "Null" 1 "Off" 2 "Low" 3 "Medium" 4 "High" 5 "NotUsed_1" 6 "NotUsed_2" 7 "NotUsed_3" ;
VAL_ 453 SeatLatcWarnR2Psn_D_Rq 0 "Inactive" 1 "Warning_1" 2 "Warning_2" 3 "Warning_3" ;
VAL_ 453 SeatThgRExtnR2Psn_Pc_Act 15 "Faulty" ;
VAL_ 453 SeatDevcAdjR2Psng_D_St 0 "Inactive" 1 "Increase" 2 "Decrease" 3 "Not Used" ;
VAL_ 453 SeatCshnRclCtlPsn_D_Rq2 0 "Inactive" 1 "Cushion_forward" 2 "Cushion_Backward" 3 "Recliner_Forward" 4 "Recliner_Backward" 5 "NotUsed_1" 6 "NotUsed_2" 7 "NotUsed_3" ;
VAL_ 453 SeatSlidPsngr_D_Rq 0 "Inactive" 1 "Enabling" 2 "Pitching" 3 "Pitched" 4 "Returning" 5 "Stopped" 6 "NotUsed_1" 7 "NotUsed_2" ;
VAL_ 453 SeatSetMnuR2Psngr_D_St 0 "Inactive" 1 "Massage_Menu" 2 "Seat_Cushion_Menu" 3 "Chauffeur_Switch" ;
VAL_ 453 SeatCalfRaisR2Psn_Pc_Act 126 "NoDataExists" 127 "Faulty" ;
VAL_ 453 SeatSetNotfnR2Psn_D_Rq 0 "Inactive" 1 "Pop_1" 2 "Pop_2" 3 "NotUsed_1" ;
VAL_ 453 SeatDevcSetR2Psng_D_St 0 "Inactive" 1 "Upper_Thoracic" 2 "Left_Thigh_Extension" 3 "Right_Thigh_Extension" 4 "Calf_Raise_Extension" 5 "ChauffeurSwitch_Cushion" 6 "ChauffeurSwitch_Recliner" 7 "Upper_Lumbar" 8 "Mid_Lumbar" 9 "Lower_Lumbar" 10 "Back_Bolsters" 11 "Cushion_Bolsters" 12 "Headrest" 13 "Lumbar" 14 "Pattern_1" 15 "Pattern_2" 16 "Pattern_3" 17 "Pattern_4" 18 "Pattern_5" 19 "Pattern_6" 20 "Pattern_7" 21 "Pattern_8" 22 "Pattern_9" 23 "Pattern_10" 24 "NotUsed_1" 25 "NotUsed_2" 26 "NotUsed_3" 27 "NotUsed_4" 28 "NotUsed_5" 29 "NotUsed_6" 30 "NotUsed_7" 31 "NotUsed_8" ;
VAL_ 453 SeatThgLExtnR2Psn_Pc_Act 15 "Faulty" ;
VAL_ 453 StmsR2Psngr_D2_Stat 0 "Null" 1 "Off" 2 "Low" 3 "Medium" 4 "High" 5 "NotUsed_1" 6 "NotUsed_2" 7 "NotUsed_3" ;
VAL_ 454 SeatDevcSetDrv_D_Rq 0 "Inactive" 1 "Upper_Thoracic" 2 "Left_Thigh_Extension" 3 "Right_Thigh_Extension" 4 "Calf_Raise_Extension" 5 "Upper_Lumbar" 6 "Mid_Lumbar" 7 "Lower_Lumbar" 8 "Back_Bolsters" 9 "Cushion_Bolsters" 10 "Headrest" 11 "Lumbar" 12 "Pattern_1" 13 "Pattern_2" 14 "Pattern_3" 15 "Pattern_4" 16 "Pattern_5" 17 "Pattern_6" 18 "Pattern_7" 19 "Pattern_8" 20 "Pattern_9" 21 "Pattern_10" 22 "NotUsed_1" 23 "NotUsed_2" 24 "NotUsed_3" 25 "NotUsed_4" 26 "NotUsed_5" 27 "NotUsed_6" 28 "NotUsed_7" 29 "NotUsed_8" 30 "NotUsed_9" 31 "NotUsed_10" ;
VAL_ 454 SeatCshnRclPsn_D_RqMnu 0 "Inactive" 1 "Cushion_Forward" 2 "Cushion_Backward" 3 "Recliner_Forward" 4 "Recliner_Bakward" 5 "NotUsed_1" 6 "NotUsed_2" 7 "NotUsed_3" ;
VAL_ 454 SeatDevcSetPsngr_D_Rq 0 "Inactive" 1 "Upper_Thoracic" 2 "Left_Thigh_Extension" 3 "Right_Thigh_Extension" 4 "Calf_Raise_Extension" 5 "Upper_Lumbar" 6 "Mid_Lumbar" 7 "Lower_Lumbar" 8 "Back_Bolsters" 9 "Cushion_Bolsters" 10 "Headrest" 11 "Lumbar" 12 "Pattern_1" 13 "Pattern_2" 14 "Pattern_3" 15 "Pattern_4" 16 "Pattern_5" 17 "Pattern_6" 18 "Pattern_7" 19 "Pattern_8" 20 "Pattern_9" 21 "Pattern_10" 22 "NotUsed_1" 23 "NotUsed_2" 24 "NotUsed_3" 25 "NotUsed_4" 26 "NotUsed_5" 27 "NotUsed_6" 28 "NotUsed_7" 29 "NotUsed_8" 30 "NotUsed_9" 31 "NotUsed_10" ;
VAL_ 454 SeatHeadrstAdjPsn_D_Rq 0 "Inactive" 1 "Forward" 2 "Backward" 3 "Up" 4 "Down" 5 "NotUsed_1" 6 "NotUsed_2" 7 "NotUsed_3" ;
VAL_ 454 SeatSlidR2Psng_D_RqMnu 0 "Inactive" 1 "Pitch" 2 "Return" 3 "Stop" ;
VAL_ 454 SeatSetMnuDrv_D_Rq 0 "Inactive" 1 "Massage_Menu" 2 "Seat_Back_Menu" 3 "Seat_Cushion_Menu" 4 "Headrestraint_Menu" 5 "NotUsed_1" 6 "NotUsed_2" 7 "NotUsed_3" ;
VAL_ 454 SeatHeadrstAdjDrv_D_Rq 0 "Inactive" 1 "Forward" 2 "Backward" 3 "Up" 4 "Down" 5 "NotUsed_1" 6 "NotUsed_2" 7 "NotUsed_3" ;
VAL_ 454 StmsPsngr_D_RqMnu 0 "Null" 1 "Low" 2 "Medium" 3 "High" ;
VAL_ 454 StmsDrv_D_RqMnu 0 "Null" 1 "Low" 2 "Medium" 3 "High" ;
VAL_ 454 SeatDevcAdjDrv_D_Rq 0 "Inactive" 1 "Increase" 2 "Decrease" 3 "NotUsed" ;
VAL_ 454 SeatDevcAdjPsngr_D_Rq 0 "Inactive" 1 "Increase" 2 "Decrease" 3 "NotUsed" ;
VAL_ 454 DataTrnsfrMde_D_Rq 0 "Default" 1 "Exit_DTM" 2 "Enter_LmtdDTM" 3 "Enter_ExtndDTM" 4 "NotUsed_1" 5 "NotUsed_2" 6 "NotUsed_3" 7 "NotUsed_4" ;
VAL_ 454 SeatSetMnuPsngr_D_Rq 0 "Inactive" 1 "Massage_Menu" 2 "Seat_Back_Menu" 3 "Seat_Cushion_Menu" 4 "Headrestraint_Menu" 5 "NotUsed_1" 6 "NotUsed_2" 7 "NotUsed_3" ;
VAL_ 454 SeatSlidR2Drv_D_RqMnu 0 "Inactive" 1 "Pitch" 2 "Return" 3 "Stop" ;
VAL_ 454 StmsPsngr_D2_RqMnu 0 "Null" 1 "Off" 2 "Low" 3 "Medium" 4 "High" 5 "NotUsed_1" 6 "NotUsed_2" 7 "NotUsed_3" ;
VAL_ 454 StmsDrv_D2_RqMnu 0 "Null" 1 "Off" 2 "Low" 3 "Medium" 4 "High" 5 "NotUsed_1" 6 "NotUsed_2" 7 "NotUsed_3" ;
VAL_ 455 SeatDevcAdjR2Drv_D_Rq 0 "Inactive" 1 "Increase" 2 "Decrease" 3 "NotUsed" ;
VAL_ 455 SeatSetMnuR2Psngr_D_Rq 0 "Inactive" 1 "Massage_Menu" 2 "Seat_Cushion_Menu" 3 "Chauffeur_Switch" ;
VAL_ 455 StmsR2Drv_D_RqMnu 0 "Null" 1 "Low" 2 "Medium" 3 "High" ;
VAL_ 455 SeatCshnRclCtlPsn_D_Rq3 0 "Inactive" 1 "Cushion_Forward" 2 "Cushion_Backward" 3 "Recliner_Forward" 4 "Recliner_Backward" 5 "NotUsed_1" 6 "NotUsed_2" 7 "NotUsed_3" ;
VAL_ 455 SeatDevcSetR2Drv_D_Rq 0 "Inactive" 1 "Upper_Thoracic" 2 "Left_Thigh_Extension" 3 "Right_Thigh_Extension" 4 "Calf_Raise_Extension" 5 "ChauffeurSwitch_Cushion" 6 "ChauffeurSwitch_Recliner" 7 "Upper_Lumbar" 8 "Mid_Lumbar" 9 "Lower_Lumbar" 10 "Back_Bolsters" 11 "Cushion_Bolsters" 12 "HeadRest" 13 "Lumbar" 14 "Pattern_1" 15 "Pattern_2" 16 "Pattern_3" 17 "Pattern_4" 18 "Pattern_5" 19 "Pattern_6" 20 "Pattern_7" 21 "Pattern_8" 22 "Pattern_9" 23 "Pattern_10" 24 "NotUsed_1" 25 "NotUsed_2" 26 "NotUsed_3" 27 "NotUsed_4" 28 "NotUsed_5" 29 "NotUsed_6" 30 "NotUsed_7" 31 "NotUsed_8" ;
VAL_ 455 SeatDevcAdjR2Psng_D_Rq 0 "Inactive" 1 "Increase" 2 "Decrease" 3 "NotUsed" ;
VAL_ 455 SeatDevcSetR2Psng_D_Rq 0 "Inactive" 1 "Upper_Thoracic" 2 "Left_Thigh_Extension" 3 "Right_Thigh_Extension" 4 "Calf_Raise_Extension" 5 "ChauffeurSwitch_Cushion" 6 "ChauffeurSwitch_Recliner" 7 "Upper_Lumbar" 8 "Mid_Lumbar" 9 "Lower_Lumbar" 10 "Back_Bolsters" 11 "Cushion_Bolsters" 12 "Headrest" 13 "Lumbar" 14 "Pattern_1" 15 "Pattern_2" 16 "Pattern_3" 17 "Pattern_4" 18 "Pattern_5" 19 "Pattern_6" 20 "Pattern_7" 21 "Pattern_8" 22 "Pattern_9" 23 "Pattern_10" 24 "NotUsed_1" 25 "NotUsed_2" 26 "NotUsed_3" 27 "NotUsed_4" 28 "NotUsed_5" 29 "NotUsed_6" 30 "NotUsed_7" 31 "NotUsed_8" ;
VAL_ 455 StmsR2Psngr_D2_RqMnu 0 "Null" 1 "Off" 2 "Low" 3 "Medium" 4 "High" 5 "NotUsed_1" 6 "NotUsed_2" 7 "NotUsed_3" ;
VAL_ 455 StmsR2Drv_D2_RqMnu 0 "Null" 1 "Off" 2 "Low" 3 "Medium" 4 "High" 5 "NotUsed_1" 6 "NotUsed_2" 7 "NotUsed_3" ;
VAL_ 455 SeatSetMnuR2Drv_D_Rq 0 "Inactive" 1 "Massage_Menu" 2 "Seat_Cushion_Menu" 3 "Chauffeur_Switch" ;
VAL_ 462 AprIdUnlck_B_Stat 0 "FALSE" 1 "TRUE" ;
VAL_ 462 AprAuthntctn_B_Rq 0 "FALSE" 1 "TRUE" ;
VAL_ 462 AprPsswrdBackup_B_Rq 0 "Null" 1 "Rider" 2 "RiderBackup" 3 "Loader" 4 "LoaderBackup" 5 "Unloader" 6 "UnloaderBackup" 7 "Service" 8 "ServiceVehicleBackup" 9 "Driver" 10 "DriverVehicleBackup" 11 "Elevated" 12 "ElevatedVehicleBackup" 13 "NotUsed_1" 14 "NotUsed_2" 15 "NotUsed_3" ;
VAL_ 462 AprInfo_B_Rq 0 "FALSE" 1 "TRUE" ;
VAL_ 464 SdarsSampleRate_D_Rq 0 "Null" 1 "SampleRate_44100Hz" 2 "SampleRate_48000Hz" 3 "NotUsed" ;
VAL_ 467 RjvntActv_D_Stat 0 "Inactive" 1 "Active" 2 "NotUsed" 3 "Faulty" ;
VAL_ 467 RjvntSeatCool_B_Rq 0 "Off" 1 "On" ;
VAL_ 467 RjvntSeatHeat_B_Rq 0 "Off" 1 "On" ;
VAL_ 467 RjvntThemSel_D_Stat 0 "Null" 1 "Theme1" 2 "Theme2" 3 "Theme3" 4 "Theme4" 5 "Theme5" 6 "Theme6" 7 "Theme7" 8 "Theme8" 9 "Theme9" 10 "Theme10" 11 "Theme11" 12 "Theme12" 13 "Theme13" 14 "Theme14" 15 "Theme15" ;
VAL_ 467 RjvntSeatSetSavDrv_B_Rq 0 "No" 1 "Yes" ;
VAL_ 467 DgtlShadeAr1Front_D_Rq 0 "Null" 1 "OnClear" 2 "OffShade" 3 "Auto" 4 "NotUsed_1" 5 "NotUsed_2" 6 "NotUsed_3" 7 "NotUsed_4" ;
VAL_ 467 RjvntPhs_D_Stat 0 "Inactive" 1 "Relax" 2 "Invigorate" 3 "Exit" 4 "Abort" 5 "NotUsed_1" 6 "NotUsed_2" 7 "NotUsed_3" ;
VAL_ 467 RjvntScent_B_Rq 0 "Off" 1 "On" ;
VAL_ 467 RjvntSeatMov_B_Rq 0 "Off" 1 "On" ;
VAL_ 467 DgtlShadeAr3Front_D_Rq 0 "Null" 1 "OnClear" 2 "OffShade" 3 "Auto" 4 "NotUsed_1" 5 "NotUsed_2" 6 "NotUsed_3" 7 "NotUsed_4" ;
VAL_ 467 DgtlShadeAr2Front_D_Rq 0 "Null" 1 "OnClear" 2 "OffShade" 3 "Auto" 4 "NotUsed_1" 5 "NotUsed_2" 6 "NotUsed_3" 7 "NotUsed_4" ;
VAL_ 467 DgtlShadeAr5Front_D_Rq 0 "Null" 1 "OnClear" 2 "OffShade" 3 "Auto" 4 "NotUsed_1" 5 "NotUsed_2" 6 "NotUsed_3" 7 "NotUsed_4" ;
VAL_ 467 DgtlShadeAr4Front_D_Rq 0 "Null" 1 "OnClear" 2 "OffShade" 3 "Auto" 4 "NotUsed_1" 5 "NotUsed_2" 6 "NotUsed_3" 7 "NotUsed_4" ;
VAL_ 467 DgtlShadeMdeFront_D_Rq 0 "Null" 1 "AllOnClear" 2 "AllOffShade" 3 "Pattern" 4 "Auto" 5 "ManualMode" 6 "NotUsed_1" 7 "NotUsed_2" ;
VAL_ 467 DgtlShadeAr6Front_D_Rq 0 "Null" 1 "OnClear" 2 "OffShade" 3 "Auto" 4 "NotUsed_1" 5 "NotUsed_2" 6 "NotUsed_3" 7 "NotUsed_4" ;
VAL_ 470 VRM_PlayNametag_Rsp 0 "Inactive" 1 "NametagUnknown" ;
VAL_ 470 VRM_SetDefaultPhone_Rsp 0 "Inactive" 1 "PhoneIndex1" 2 "PhoneIndex2" 3 "PhoneIndex3" 4 "PhoneIndex4" 5 "PhoneIndex5" 6 "PhoneIndex6" 7 "NoPhoneAssocWithThisIndex" 8 "NotAbleToCreateLinkToPhone" 9 "IntermediateResult" ;
VAL_ 470 VRM_BTEndTelService_Rsp 0 "Inactive" 1 "IntermediateResult" 2 "FinalResult" 3 "Error" ;
VAL_ 470 VRM_BTSendDTMFTone_Rsp 0 "Inactive" 1 "FinalResult" 2 "IntermediateResult" 3 "Error" ;
VAL_ 470 VRM_DebondPhone_Rsp 0 "Inactive" 1 "PhoneIndex1Debonded" 2 "PhoneIndex2Debonded" 3 "PhoneIndex3Debonded" 4 "PhoneIndex4Debonded" 5 "PhoneIndex5Debonded" 6 "PhoneIndex6Debonded" 7 "NoPhoneAssocWithThisIndex" ;
VAL_ 470 VRM_BTIncomingCall_Rsp 0 "Inactive" 1 "Accepted" 2 "Declined" 3 "Failed" ;
VAL_ 470 VRM_BTActFeatDevInd_Rsp 0 "Inactive" 1 "BTDeviceIndex1" 2 "BTDeviceIndex2" 3 "BTDeviceIndex3" 4 "BTDeviceIndex4" 5 "BTDeviceIndex5" 6 "BTDeviceIndex6" 7 "BTDeviceIndex7" 8 "BTDeviceIndex8" 9 "BTDeviceIndex9" 10 "BTDeviceIndex10" 11 "BTDeviceIndex11" 12 "BTDeviceIndex12" 13 "BTDeviceIndex13" 14 "BTDeviceIndex14" 15 "BTDeviceIndex15" 28 "Failure" 29 "Failure_ItemMissing" 30 "FailureConEnvOrDevNotReact" 31 "IntermediateResult" ;
VAL_ 470 VRM_BTDebondDevice_Rsp 0 "Inactive" 1 "BTDeviceIndex1Debonded" 2 "BTDeviceIndex2Debonded" 3 "BTDeviceIndex3Debonded" 4 "BTDeviceIndex4Debonded" 5 "BTDeviceIndex5Debonded" 6 "BTDeviceIndex6Debonded" 7 "BTDeviceIndex7Debonded" 8 "BTDeviceIndex8Debonded" 9 "BTDeviceIndex9Debonded" 10 "BTDeviceIndex10Debonded" 11 "BTDeviceIndex11Debonded" 12 "BTDeviceIndex12Debonded" 13 "BTDeviceIndex13Debonded" 14 "BTDeviceIndex14Debonded" 15 "BTDeviceIndex15Debonded" ;
VAL_ 470 VR_StartPhoneVR_Rsp 0 "Inactive" 1 "Idle" 2 "Recognized" 3 "NotAllowed" ;
VAL_ 470 VRM_BTActFeatGroup_Rsp 0 "ALL" 1 "Radio" 2 "MP" 3 "Nav" 4 "MobileCom" 5 "Voice" 6 "Video" 7 "Office" 8 "Reserved" 15 "Reserved_last" ;
VAL_ 473 NAV_SetTAMode_Rq 0 "Inactive" 1 "TaLocalOn" 2 "TaDistantOn" 3 "TaOff" ;
VAL_ 473 NAV_SetAFMode_Rq 0 "Inactive" 1 "AfOn" 2 "AfOff" 3 "Auto" ;
VAL_ 473 NAV_SetTUServiceLink_Rq 0 "Invalid" 1 "Active" 2 "Inactive" 3 "reserved" ;
VAL_ 473 NAV_CDSetShuffle_Rq 0 "Inactive" 1 "On" 2 "Off" 3 "OnFolder" ;
VAL_ 473 NAV_StorePreset2_Rq 0 "Inactive" 1 "Preset1" 2 "Preset2" 3 "Preset3" 4 "Preset4" 5 "Preset5" 6 "Preset6" 7 "Preset7" 8 "Preset8" 9 "Preset9" 10 "Preset10" 11 "Preset11" 12 "Preset12" 13 "Preset13" 14 "Preset14" 15 "Preset15" 16 "Preset16" 17 "Preset17" 18 "Preset18" 19 "Preset19" 20 "Preset20" 21 "Preset21" 22 "Preset22" 23 "Preset23" 24 "Preset24" 25 "Preset25" 26 "Preset26" 27 "Preset27" 28 "Preset28" 29 "Preset29" 30 "Preset30" 31 "Reserved" ;
VAL_ 473 NAV_SelectPTYCodeSet_Rq 0 "Inactive" 1 "SetCode" ;
VAL_ 473 HMI_StorePreset2_Rq 0 "Inactive" 1 "Preset1" 2 "Preset2" 3 "Preset3" 4 "Preset4" 5 "Preset5" 6 "Preset6" 7 "Preset7" 8 "Preset8" 9 "Preset9" 10 "Preset10" 11 "Preset11" 12 "Preset12" 13 "Preset13" 14 "Preset14" 15 "Preset15" 16 "Preset16" 17 "Preset17" 18 "Preset18" 19 "Preset19" 20 "Preset20" 21 "Preset21" 22 "Preset22" 23 "Preset23" 24 "Preset24" 25 "Preset25" 26 "Preset26" 27 "Preset27" 28 "Preset28" 29 "Preset29" 30 "Preset30" 31 "Reserved" ;
VAL_ 473 NAV_CDSetRepeat_Rq 0 "Inactive" 1 "RepeatOnTrack" 2 "Off" 3 "OnFolder" ;
VAL_ 473 NAV_CDSetIntroScan_Rq 0 "Inactive" 1 "On" 2 "Off" 3 "OnFolder" ;
VAL_ 473 NAV_StorePreset_Rq 0 "Inactive" 1 "Preset1" 2 "Preset2" 3 "Preset3" 4 "Preset4" 5 "Preset5" 6 "Preset6" 7 "Preset7" 8 "Preset8" 9 "Preset9" 10 "Preset10" ;
VAL_ 473 NAV_SetReg_Rq 0 "Inactive" 1 "Off" 2 "On" ;
VAL_ 474 NAV_ARAudioSource_Rq 0 "AmfmRadio" 1 "FrontDisc" 2 "SDARS_DAB" 3 "InDashCdChanger" 4 "VoiceRecogniser" 5 "TelematicUnit" 6 "BluetoothPhone" 7 "RearDisc" 8 "APIM" 9 "FrontAuxInput" 10 "Navigation" 11 "RearAux" 12 "NotReq" 13 "BTAudio" 14 "USB" 15 "iPod" ;
VAL_ 474 NAV_ARReqstrSystem_Rq 0 "FrontRequester" 1 "RearRequester" ;
VAL_ 474 NAV_AROperationType_Rq 0 "Inactive" 1 "Requestaudioresource" 2 "Releaseaudioresource" 3 "Releaseallaudioresouces" 4 "Getresourceupdate" 5 "Getallresourceupdates" ;
VAL_ 474 NAV_ARReqstrPriority_Rq 0 "EmergencyServ" 1 "TelService" 2 "AutoAnswer" 3 "Ta" 4 "PttMutevoice" 5 "NavUserVoiceCmd" 6 "NavSysVoiceCmd" 7 "Radio" 8 "Disc" 9 "Alarm" 10 "Ptynews" 11 "Aux_ExtSource" 12 "BT_BTNavAndTelMute" 13 "ManualAudioMute" 14 "NotReq" ;
VAL_ 474 NAV_SetCurrentStatOp_Rq 0 "Inactive" 1 "SetCurrentFrequency" 2 "SetCurrentPiCode" 3 "SetCurrentStation" ;
VAL_ 474 Nav_SetCurrStatMCCh_Rq 0 "Inactive" 1 "MCChannel1" 2 "MCChannel2" 3 "MCChannel3" 4 "MCChannel4" 5 "MCChannel5" 6 "MCChannel6" 7 "MCChannel7" ;
VAL_ 474 NAV_SetNEWSMode_Rq 0 "Inactive" 1 "NewsOn" 2 "NewsOff" ;
VAL_ 474 NAV_SetDSP_Rq 0 "Inactive" 1 "All" 2 "Driver" 3 "Passenger" 4 "Reserved1" 5 "Reserved2" 6 "Reserved3" 7 "FrontSeats" 8 "RearSeats" 9 "Convertible" 15 "Reserved" ;
VAL_ 476 NAV_SkipCatalouge_Rq 0 "Inactive" 1 "NextCatalouge" 2 "PerviousCatalouge" ;
VAL_ 476 NAV_SetDSPProgram_Rq 0 "Inactive" 1 "Normal" 2 "Pop" 3 "Classical" 4 "Rock" 5 "Voice" 6 "Reserved1" 7 "Reserved2" ;
VAL_ 476 NAV_SetOperationMode_Rq 0 "Inactive" 1 "Stop" 2 "Play" 3 "Pause" 4 "FastForward10" 5 "FastForward20" 6 "FastRewind10" 7 "FastRewind20" ;
VAL_ 476 Nav_SetAudioMixRatio_Rq 31 "Inactive" ;
VAL_ 477 NAV_LoadEjectDisc_Rq 0 "Inactive" 1 "Disc1" 2 "Disc2" 3 "Disc3" 4 "Disc4" 5 "Disc5" 6 "Disc6" 7 "All" ;
VAL_ 477 NAV_LoadEjectMode_Rq 0 "Inactive" 1 "Load" 2 "Eject" 3 "EndloadMode" ;
VAL_ 479 DISP_SetVol_Source_Rq 0 "Inactive" 1 "SetTAVolume" 2 "SetPromptVolume" 3 "SetPhoneVolume" 4 "SetVRvolume" 5 "SetAudioVolume" ;
VAL_ 479 DISP_Setshaker_Rq 0 "Inactive" 1 "Off" 2 "On" ;
VAL_ 481 PsPrim_D_Stat 0 "NotDetermined" 1 "WarmUpDisChrg" 2 "WarmUpChrg" 3 "PreDrvDisChrg" 4 "PreDrvPwrTest" 5 "PreDrvChrg" 6 "ActDrvDisChrg" 7 "ActDrvReChrg" 8 "FullCpblty" 9 "LimtdCpblty" 10 "NoCpblty" 11 "PreDrvNeeded" 12 "NotUsed_1" 13 "NotUsed_2" 14 "NotUsed_3" 15 "NotUsed_4" ;
VAL_ 481 PsDiagPrim_B_Falt 0 "Inactive" 1 "Active" ;
VAL_ 481 PsCpbltyPrim_B_Stat 0 "Degraded" 1 "Ok" ;
VAL_ 481 PsMainPrim_B_Falt 0 "NoFault" 1 "Fault" ;
VAL_ 481 PsSftyPrim_B_Falt 0 "NoFault" 1 "Fault" ;
VAL_ 481 PsShedPrim_B_Rq 0 "False" 1 "True" ;
VAL_ 481 TurnLghtSwtch_D_Stat4 0 "Off" 1 "Left" 2 "Right" 3 "NotUsed" ;
VAL_ 481 PsSftyPrim_B_Stat 0 "Inactive" 1 "Active" ;
VAL_ 481 PsScnd_D_Stat 0 "NotDetermined" 1 "WarmUpDisChrg" 2 "WarmUpChrg" 3 "PreDrvDisChrg" 4 "PreDrvPwrTest" 5 "PreDrvChrg" 6 "ActDrvDisChrg" 7 "ActDrvReChrg" 8 "FullCpblty" 9 "LimtdCpblty" 10 "NoCpblty" 11 "PreDrvNeeded" 12 "NotUsed_1" 13 "NotUsed_2" 14 "NotUsed_3" 15 "NotUsed_4" ;
VAL_ 481 PsCpbltyScnd_B_Stat 0 "Degraded" 1 "Ok" ;
VAL_ 481 PsDiagScnd_B_Falt 0 "Inactive" 1 "Active" ;
VAL_ 481 PsMainScnd_B_Falt 0 "NoFault" 1 "Fault" ;
VAL_ 481 PsSftyScnd_B_Falt 0 "NoFault" 1 "Fault" ;
VAL_ 481 PsShedScnd_B_Rq 0 "False" 1 "True" ;
VAL_ 481 AvTrgtPreAuthrz_B_Stat 0 "Disable" 1 "Enable" ;
VAL_ 481 CakActvtn_D_Rq 0 "Null" 1 "Activated" 2 "Deactivated" 3 "DeactivatedAll" ;
VAL_ 481 PesSwtchA_D_Stat 0 "NotPressed" 1 "Pressed" 2 "SwtchFalted" 3 "NotUsed_1" ;
VAL_ 481 DrStatAllSides_D_Actl 0 "Closed" 1 "Ajar" 2 "NotUsed_1" 3 "Faulty" ;
VAL_ 481 VehOnOff_D_RqArb 0 "Null" 1 "IgnitionRun" 2 "Manual_IgnitionRun" 3 "NonMotive" 4 "ManualMotive" 5 "ServiceManual" 6 "ValetManual" 7 "AV" 8 "Shutdown" 9 "NotUsed_1" 10 "NotUsed_2" 11 "NotUsed_3" 12 "NotUsed_4" 13 "NotUsed_5" 14 "NotUsed_6" 15 "NotUsed_7" ;
VAL_ 481 StopExcptnl_D_Rq 0 "Inactive" 1 "PsngrEmgcyStopSinglePress" 2 "ConveniencePullOver" 3 "CldLawEnforcementPullOver" 4 "CldStopUnoccupied" 5 "CldStopOccupied" 6 "PsngrEmgcyStop" 7 "Faulty" ;
VAL_ 481 PsMainPrim_B_Stat 0 "Inactive" 1 "Active" ;
VAL_ 481 DcdcUHiPrim_I_Actl 255 "Faulty" ;
VAL_ 481 DcdcULoPrim_U_Actl 255 "Faulty" ;
VAL_ 481 PsULoPrim_I_Actl 255 "Faulty" ;
VAL_ 481 PsULoPrim_I_Mx 255 "Faulty" ;
VAL_ 481 DcdcUHiPrim_U_Actl 1022 "NoDataExists" 1023 "Faulty" ;
VAL_ 481 PsULoOvrTeScnd_B_Stat 0 "No" 1 "Yes" ;
VAL_ 481 PsULoOnScnd_B_Stat 0 "Not_Operating_" 1 "Operating" ;
VAL_ 481 PsULoDcnntScnd_B_Stat 0 "Connected" 1 "Loose_or_Disconnected" ;
VAL_ 481 PsULoOvrTePrim_B_Stat 0 "No" 1 "Yes" ;
VAL_ 481 PsULoOnPrim_B_Stat 0 "Not_Operating_" 1 "Operating" ;
VAL_ 481 PsULoDcnntPrim_B_Stat 0 "Connected" 1 "Loose_or_Disconnected" ;
VAL_ 481 DcdcUHiScnd_I_Actl 255 "Faulty" ;
VAL_ 481 DcdcULoScnd_U_Actl 255 "Faulty" ;
VAL_ 481 PsULoScnd_I_Actl 255 "Faulty" ;
VAL_ 481 PsULoScnd_I_Mx 255 "Faulty" ;
VAL_ 481 DcdcUHiScnd_U_Actl 1022 "NoDataExists" 1023 "Faulty" ;
VAL_ 481 CoolFanDcdc_D_RqScnd 0 "Off" 1 "Low" 2 "Medium" 3 "High" ;
VAL_ 481 DcdcClntFlw_D_RqScnd 0 "Off" 1 "Low" 2 "Medium" 3 "High" ;
VAL_ 481 CoolFanDcdc_D_RqPrim 0 "Off" 1 "Low" 2 "Medium" 3 "High" ;
VAL_ 481 DcdcClntFlw_D_RqPrim 0 "Off" 1 "Low" 2 "Medium" 3 "High" ;
VAL_ 481 CldRecvry_B_Rq 0 "False" 1 "True" ;
VAL_ 481 TvfSndShrt_D_Rq 0 "INACTIVE" 1 "LINGER_TIME_EXCEEDED" 2 "LINGER_TIME_ADDED" 3 "MAXIMUM_LINGER_TIME_ADDED" 4 "LINGER_TIME_EXPIRING" 5 "LINGER_EXP_NOT_IN_SEAT_ONB" 6 "LINGER_EXP_NO_ACTIVITY_OFB" 7 "GO_BUTTON_ENABLED" 8 "GO_BUTTON_REMINDER" 9 "GO_BUTTON_PRESSED" 10 "CANCEL_TRIP_ON_ONBOARDING" 11 "ARRIVING_SOON_AT_DESTINATI" 12 "SDS_ARRIVAL_DESTINATION" 13 "AV_DISMISSED" 14 "DROPOFF_LOCATION_CHANGED" 15 "NotUsed_1" ;
VAL_ 481 ScanInProgress_B_Stat 0 "No" 1 "Yes" ;
VAL_ 481 AvDcdcWake_B_Rq 0 "Off" 1 "On" ;
VAL_ 481 VdsScndWake_B_Rq 0 "Off" 1 "On" ;
VAL_ 481 FmesSndShrt_D_Rq 0 "NoSnd" 1 "Snd_1" 2 "Snd_2" 3 "Snd_3" 4 "Snd_4" 5 "Snd_5" 6 "Snd_6" 7 "Snd_7" 8 "Snd_8" 9 "Snd_9" 10 "Snd_10" 11 "Snd_11" 12 "Snd_12" 13 "Snd_13" 14 "Snd_14" 15 "Snd_15" 16 "Snd_16" 17 "Snd_17" 18 "Snd_18" 19 "Snd_19" 20 "Snd_20" 21 "Snd_21" 22 "Snd_22" 23 "Snd_23" 24 "Snd_24" 25 "Snd_25" 26 "Snd_26" 27 "Snd_27" 28 "Snd_28" 29 "Snd_29" 30 "Snd_30" 31 "Snd_31" 32 "Snd_32" 33 "Snd_33" 34 "Snd_34" 35 "Snd_35" 36 "Snd_36" 37 "Snd_37" 38 "Snd_38" 39 "Snd_39" 40 "Snd_40" 41 "Snd_41" 42 "Snd_42" 43 "Snd_43" 44 "Snd_44" 45 "Snd_45" 46 "Snd_46" 47 "Snd_47" 48 "Snd_48" 49 "Snd_49" 50 "Snd_50" 51 "Snd_51" 52 "Snd_52" 53 "Snd_53" 54 "Snd_54" 55 "Snd_55" 56 "Snd_56" 57 "Snd_57" 58 "Snd_58" 59 "Snd_59" 60 "Snd_60" 61 "Snd_61" 62 "Snd_62" 63 "Snd_63" ;
VAL_ 481 VdsPrimWake_B_Rq 0 "Off" 1 "On" ;
VAL_ 481 RefuelCtlPw_B_Rq 0 "Inactive" 1 "Active" ;
VAL_ 481 DataCtlPw_B_Rq 0 "Inactive" 1 "Active" ;
VAL_ 481 VehOnOff_D_Stat 0 "Null" 1 "StandupInProgree" 2 "IgnRunStandupComplete" 3 "NonMotiveStandupComplete" 4 "PreDriveTestComplete" 5 "ServiceManStandupComplete" 6 "ValetManStandupComplete" 7 "AvStandupComplete" 8 "ManMotiveStandupComplete" 9 "LimitedManStandupComplete" 10 "SusdRequestFailed" 11 "ShutdownInProgress" 12 "ShutdownComplete" 13 "NotUsed_1" 14 "NotUsed_2" 15 "NotUsed_3" ;
VAL_ 481 PostCtlPw_B_Rq 0 "Inactive" 1 "Active" ;
VAL_ 481 AVPIM_PwrOFF_B_Rq 0 "No_Inhibit" 1 "Inhibit" ;
VAL_ 481 AvDcdcIntgtyChk_B_Stat 0 "Closed" 1 "Open" ;
VAL_ 481 PesSwtchB_D_Stat 0 "NotPressed" 1 "Pressed" 2 "SwtchFalted" 3 "NotUsed_1" ;
VAL_ 482 SDARS_Antenna_Err2_St 0 "Invalid" 1 "Inactive" 2 "Active" ;
VAL_ 482 SDARS_Error_Conf2_St 0 "Invalid" 1 "SDARS_ON" 2 "SDARS_OFF" ;
VAL_ 482 SDARS_Receive_Err2_St 0 "Invalid" 1 "Inactive" 2 "Active" ;
VAL_ 482 SDARS_Firm_Update2_St 0 "Invalid" 1 "Inactive" 2 "Active" ;
VAL_ 482 SDARS_Invalid_Chan2_St 0 "Invalid" 1 "Inactive" 2 "Active" ;
VAL_ 482 SDARS_Seek_Scan2_St 0 "Invalid" 1 "NoChannelsAvailable" ;
VAL_ 482 SDARS_UnSubscrb2_St 0 "Invalid" 1 "Inactive" 2 "Active" ;
VAL_ 482 SDARS_Loss_Ant2_St 0 "Invalid" 1 "Inactive" 2 "Active" ;
VAL_ 482 SdarsCntntBlked_D_Stat 0 "Invalid" 1 "Inactive" 2 "Active" 3 "UNUSED" ;
VAL_ 482 SDARS_GCI_Update2_St 0 "Invalid" 1 "Inactive" 2 "Active" ;
VAL_ 482 SDARS_Subscription2_St 0 "Invalid" 1 "Inactive" 2 "Active" ;
VAL_ 482 SDARS_UnSubscrb_Chan2_St 0 "Invalid" 1 "Inactive" 2 "Active" ;
VAL_ 482 SdarsCnnctDisabl_D_St 0 "Invalid" 1 "Inactive" 2 "Active" 3 "UNUSED" ;
VAL_ 482 SdarsGeoRstrcCntnt_D_St 0 "Invalid" 1 "Inactive" 2 "Active" 3 "UNUSED" ;
VAL_ 482 SdarsActnRqd_D_Stat 0 "Invalid" 1 "Inactive" 2 "Active" 3 "UNUSED" ;
VAL_ 486 ResponseCode_No_Res 0 "Null" 1 "NotAccepted" 2 "Accepted" 3 "NotUsed" ;
VAL_ 486 ACU_AROperationType_Rsp 0 "Inactive" 1 "Requestaudioresource" 2 "Releaseaudioresource" 3 "Releaseallaudioresouces" 4 "Getresourceupdate" 5 "Getallresourceupdates" ;
VAL_ 486 ACU_ARResponse_Rsp 0 "Inactive" 1 "RequestAccepted" 2 "RequestAcceptedWoCtrl" 3 "RequestDenied" 4 "RessourceUpdateStatus" ;
VAL_ 486 ACU_ARAudioSource_Rsp 0 "AmfmRadio" 1 "FrontDisc" 2 "SDARS_DAB" 3 "InDashCdChanger" 4 "VoiceRecogniser" 5 "TelematicUnit" 6 "BluetoothPhone" 7 "RearDisc" 8 "APIM" 9 "FrontAuxInput" 10 "Navigation" 11 "RearAux" 12 "NotReq" 13 "BTAudio" 14 "USB" 15 "iPod" ;
VAL_ 486 ACU_ARReqstrSystem_Rsp 0 "FrontRequester" 1 "RearRequester" ;
VAL_ 486 CabnOnliveActv_B_Stat 0 "Off" 1 "On" ;
VAL_ 486 ACU_RUReqstrSystem_St 0 "FrontRequester" 1 "RearRequester" ;
VAL_ 486 ACU_RUResReqstStatus_St 0 "NoResourceupdate" 1 "Deallocated" 2 "Allocated" 3 "Stacked" 4 "Granted" 5 "GrantedNoControlOfAudioSrc" ;
VAL_ 486 ACU_ARReqstrPriority_Rp 0 "EmergencyServ" 1 "TelService" 2 "AutoAnswer" 3 "Ta" 4 "PttMutevoice" 5 "NavUserVoiceCmd" 6 "NavSysVoiceCmd" 7 "Radio" 8 "Disc" 9 "Alarm" 10 "Ptynews" 11 "Aux_ExtSource" 12 "MobileNavAndTelMute" 13 "ManualAudioMute" 14 "NotReq" ;
VAL_ 486 ACU_RUReqstrPriority_St 0 "EmergencyServ" 1 "TelService" 2 "AutoAnswer" 3 "Ta" 4 "PttMutevoice" 5 "NavUserVoiceCmd" 6 "NavSysVoiceCmd" 7 "Radio" 8 "Disc" 9 "Alarm" 10 "Ptynews" 11 "Aux_ExtSource" 12 "MobileNavAndTelMute" 13 "ManualAudioMute" 14 "NotReq" ;
VAL_ 486 ACU_RUAudioSource_St 0 "AmfmRadio" 1 "FrontDisc" 2 "SDARS_DAB" 3 "InDashCdChanger" 4 "VoiceRecogniser" 5 "TelematicUnit" 6 "BluetoothPhone" 7 "RearDisc" 8 "APIM" 9 "FrontAuxInput" 10 "Navigation" 11 "RearAux" 12 "NotReq" 13 "BTAudio" 14 "USB" 15 "iPod" ;
VAL_ 487 Aioc_SetExtSrcOutpMd_Rq 0 "Inactive" 1 "AllocateVrAudioToOutput" 2 "AllocateBtPhoneToOutput" 3 "AllocateBtNavigationToOut" 4 "AllocateBtAudioToOutput" 5 "AllocateUSBToOutput" 6 "AllocateiPodToOutput" 7 "AllocateAUX3" 8 "DeallocateOutput" ;
VAL_ 488 AugRealtyMdule_B_Rq 0 "Off" 1 "On" ;
VAL_ 490 HMI_SetCompression_Rq 0 "Inactive" 1 "Off" 2 "On" 3 "NotUsed" ;
VAL_ 490 HMI_SkipTrack_Rq 0 "Inactive" 1 "Increment" 2 "Decrement" 3 "NotUsed" ;
VAL_ 493 Dsp_StationList_Rq 0 "Inactive" 1 "Analog_AM_List" 2 "Analog_FM_List" 3 "HD_FM_List" 4 "Analog_and_HD_FM_List" 5 "Analog_FM_PTY_List" 6 "DAB_Ensemble_Service_List" 7 "DAB_Service_List" 8 "reserved" 15 "reserved_last" ;
VAL_ 493 Dsp_AFJump_Rq 0 "Inactive" 1 "Inhibit" 2 "Enable" ;
VAL_ 493 Dsp_RefreshFlag 0 "False" 1 "True" ;
VAL_ 493 Dsp_StatLiScanCancel_Rq 0 "Inactive" 1 "Cancel" ;
VAL_ 494 HEC_TUPresetArea_Rq 0 "Inactive" 1 "GetFm1PresetData" 2 "GetFm2PresetData" 3 "GetFm3PresetData" 4 "GetFmAstPresetData" 5 "GetAmAstPresetData" 6 "GetAmPresetData" 7 "Reserved1" 8 "GetDAB1PresetData" 9 "GetDAB2PresetData" 10 "GetSAT1PresetData" 11 "GetSAT2PresetData" 12 "GetSAT3PresetData" 13 "reserved" 15 "reserved_last" ;
VAL_ 494 HEC_SetCurrTUBand_Rq 0 "Inactive" 1 "Fm1" 2 "Fm2" 3 "Fm3" 4 "FmAst" 5 "Am" 6 "AmAst" 7 "DAB1" 8 "DAB2" 9 "SAT1" 10 "SAT2" 11 "SAT3" 12 "reserved" 15 "reserved_last" ;
VAL_ 497 McEvntNotfnChoice_D_Rq 0 "Ok" 1 "Choice1" 2 "Choice2" 3 "Choice3" 4 "Choice4" 5 "Choice5" 6 "Choice6" 7 "Choice7" ;
VAL_ 497 McEvntNotfnMsgId_D_Rq 0 "Invalid" 1 "Activate" 2 "Update" 3 "Deactivate" ;
VAL_ 498 HEC_ARAudioSource_Rq 0 "AmfmRadio" 1 "FrontDisc" 2 "SDARS_DAB" 3 "InDashCdChanger" 4 "VoiceRecogniser" 5 "TelematicUnit" 6 "BluetoothPhone" 7 "RearDisc" 8 "APIM" 9 "FrontAuxInput" 10 "Navigation" 11 "RearAux" 12 "NotReq" 13 "BTAudio" 14 "USB" 15 "iPod" ;
VAL_ 498 HEC_ARReqstrSystem_Rq 0 "FrontRequester" 1 "RearRequester" ;
VAL_ 498 HEC_AROperationType_Rq 0 "Inactive" 1 "Requestaudioresource" 2 "Releaseaudioresource" 3 "Releaseallaudioresouces" 4 "Getresourceupdate" 5 "Getallresourceupdates" ;
VAL_ 498 HEC_ARReqstrPriority_Rq 0 "EmergencyServ" 1 "TelService" 2 "AutoAnswer" 3 "Ta" 4 "PttMutevoice" 5 "NavUserVoiceCmd" 6 "NavSysVoiceCmd" 7 "Radio" 8 "Disc" 9 "Alarm" 10 "Ptynews" 11 "Aux_ExtSource" 12 "BT_BTNavAndTelMute" 13 "ManualAudioMute" 14 "NotReq" ;
VAL_ 500 Dsp_GetCDTOCDData_Rq 0 "Inactive" 1 "TOC" 2 "Off" ;
VAL_ 500 Dsp_AudioSourceSel_Rq 0 "Inactive" 1 "CD" 2 "BTAudio" 3 "USB" 4 "Reserved" 5 "SDCard" ;
VAL_ 500 Dsp_CutItem_Rq 0 "Beginning" 1 "End" 2 "ThreeQuarterFromTheBeginn" 3 "Inactive" ;
VAL_ 501 Dsp_SetCRadioBand_Rq 0 "Inactive" 1 "Fm1" 2 "Fm2" 3 "Fm3" 4 "FmAst" 5 "Am" 6 "AmAst" ;
VAL_ 501 Dsp_PresetArea_Rq 0 "Inactive" 1 "GetFm1PresetData" 2 "GetFm2PresetData" 3 "GetFm3PresetData" 4 "GetFmAstPresetData" 5 "GetAmAstPresetData" 6 "GetAmPresetData" 7 "GetFmStationListPresetData" ;
VAL_ 501 Dsp_FreezeFMSL_Rq 0 "Inactive" 1 "False" 2 "True" 3 "NotUsed" ;
VAL_ 501 Dsp_SetRadSeekMode_Rq 0 "Inactive" 1 "SeekOff" 2 "AutoUp" 3 "AutoDown" 4 "ManSingleStepUp" 5 "ManSingleStepDown" 6 "ContManualUp" 7 "ContManualDown" 8 "ScanUp" 9 "ScanDown" 10 "PtySeekUp" 11 "PtySeekDown" 12 "Autostore" 13 "ContAutoUp" 14 "ContAutoDown" 15 "Reseved" ;
VAL_ 502 Dsp_FolderContent_Rq 0 "RequestContentFromParamet" 1 "RequestContentFromParentF" 2 "Inactive" ;
VAL_ 502 Dsp_CutItem2_Rq 0 "Beginning" 1 "End" 2 "ThreeQuarterFromTheBeginn" 3 "Inactive" ;
VAL_ 502 Dsp_AudioSourceSel2_Rq 0 "Inactive" 1 "CD" 2 "BTAudio" 3 "USB" 4 "Reserved" ;
VAL_ 503 Dsp_AudioSourceSel3_Rq 0 "Inactive" 1 "CD" 2 "BTAudio" 3 "USB" ;
VAL_ 504 Mc_AudioSourceSel_Rq 0 "Inactive" 1 "CD" 2 "BTAudio" 3 "USB" 4 "Reserved" 5 "SDcard" ;
VAL_ 504 Mc_CutItem_Rq 0 "Beginning" 1 "End" 2 "ThreeQuarterFromBeginOneQ" 3 "Inactive" ;
VAL_ 505 Mc_FolderContent_Rq 0 "ReqContentParameterFolder" 1 "ReqContentParentFolderOf" 2 "Inactive" ;
VAL_ 505 Mc_CutItem2_Rq 0 "Beginning" 1 "End" 2 "ThreeQuarterFromBeginOneQ" 3 "Inactive" ;
VAL_ 505 Mc_AudioSourceSel2_Rq 0 "Inactive" 1 "CD" 2 "BTAudio" 3 "USB" 4 "Reserved" 5 "SDcard" ;
VAL_ 506 Mc_AudioSourceSel3_Rq 0 "Inactive" 1 "CD" 2 "BTAudio" 3 "USB" 4 "Reserved" 5 "SDcard" ;
VAL_ 507 Mc_DB1SetTrkSetFilt1_Rq 0 "NotEngaged" 1 "SIIndex_1" 65534 "SIIndex_65534" 65535 "All" ;
VAL_ 507 Mc_DB1SetTrkSetFilt2_Rq 0 "NotEngaged" 1 "SIIndex_1" 65534 "SIIndex_65534" 65535 "All" ;
VAL_ 507 Mc_DB1SetTrkSetFilt3_Rq 0 "NotEngaged" 1 "SIIndex_1" 1022 "SIIndex_1022" 1023 "All" ;
VAL_ 507 Mc_DB1SetTrkSetConf_Rq 0 "Root" 1 "Playlist" 2 "Artist" 3 "Album" 4 "Genre" 5 "Track" 6 "Composer" 7 "Audiobook" 8 "Podcast" 9 "Reserved" 30 "Reserved_last" 31 "UnknownActive" ;
VAL_ 508 Mc_DB1GetInfSetFilt1_Rq 0 "NotEngaged" 1 "SIIndex_1" 65534 "SIIndex_65534" 65535 "All" ;
VAL_ 508 Mc_DB1GetInfSetFilt2_Rq 0 "NotEngaged" 1 "SIIndex_1" 65534 "SIIndex_65534" 65535 "All" ;
VAL_ 508 Mc_DB1GetInfSetFilt3_Rq 0 "NotEngaged" 1 "SIIndex_1" 1022 "SIIndex_1022" 1023 "All" ;
VAL_ 508 Mc_DB1GetInfSetConf_Rq 0 "Root" 1 "Playlist" 2 "Artist" 3 "Album" 4 "Genre" 5 "Track" 6 "Composer" 7 "Audiobook" 8 "Podcast" 9 "Reserved" 30 "Reserved_last" 31 "UnknownActive" ;
VAL_ 508 Mc_DB1GtInfNbrOfItms_Rq 0 "Standard" 1 "OneItem" ;
VAL_ 509 TrakAppl_D_Stat 0 "Null" 1 "Cancelled" 2 "Deactivated" 3 "NotUsed_1" 4 "NotUsed_2" 5 "NotUsed_3" 6 "NotUsed_4" 7 "NotUsed_5" ;
VAL_ 511 Dsp_TUPresetArea_Rq 0 "Inactive" 1 "GetFm1PresetData" 2 "GetFm2PresetData" 3 "GetFm3PresetData" 4 "GetFmAstPresetData" 5 "GetAmAstPresetData" 6 "GetAmPresetData" 7 "GetDAB3PresetData" 8 "GetDAB1PresetData" 9 "GetDAB2PresetData" 10 "GetSAT1PresetData" 11 "GetSAT2PresetData" 12 "GetSAT3PresetData" 13 "reserved" 15 "reserved_last" ;
VAL_ 511 Dsp_SetCurrTUBand_Rq 0 "Inactive" 1 "Fm1" 2 "Fm2" 3 "Fm3" 4 "FmAst" 5 "Am" 6 "AmAst" 7 "DAB1" 8 "DAB2" 9 "SAT1" 10 "SAT2" 11 "SAT3" 12 "DAB3" 13 "reserved1" 15 "reserved_last" ;
VAL_ 511 SdarsAudioRtng_D_Rq 0 "Null" 1 "X40l2SStereoOut" 2 "APIMStereoOut" 3 "NotUsed" ;
VAL_ 512 PtDrvMde_D_Stat 0 "Normal" 1 "Sport" 2 "SnowWet" 3 "TowHaulGradeAssist" 4 "Sand" 5 "Baja" 6 "Rock" 7 "Drag" 8 "Track" 9 "NotUsed6" 10 "NotUsed7" 11 "NotUsed8" 12 "NotUsed9" 13 "NotUsed10" 14 "NotUsed11" 15 "Faulty" ;
VAL_ 513 GridSrvc01_B_Stat 0 "Off" 1 "On" ;
VAL_ 513 BptSustn_B_Rq 0 "Inactive" 1 "Active" ;
VAL_ 513 Bpt_D_StatHtrn 0 "NotReady" 1 "Initialization" 2 "BptReady" 3 "Precharge" 4 "BptActive" 5 "EvseFault" 6 "VehicleFault" 7 "NotUsed_1" 8 "NotUsed_2" 9 "NotUsed_3" 10 "NotUsed_4" 11 "NotUsed_5" 12 "NotUsed_6" 13 "NotUsed_7" 14 "NotUsed_8" 15 "Faulty" ;
VAL_ 513 MtrTracTeColr_D_Dsply 0 "ColorForNormal" 1 "ColorForLimited" 2 "ColorForSeverlyLimited" 3 "NotUsed" ;
VAL_ 513 BattTracTeColr_D_Dsply 0 "ColorForNormal" 1 "ColorForLimited" 2 "ColorForSeverlyLimited" 3 "NotUsed" ;
VAL_ 513 BptMde_D_Stat 0 "Null" 1 "Off" 2 "Manual" 3 "Automatic" 4 "NotUsed_1" 5 "NotUsed_2" 6 "NotUsed_3" 7 "NotUsed_4" ;
VAL_ 513 ChrgStat_D3_Dsply 0 "NotReady" 1 "FaultInsideCar" 2 "FaultOutsideCar" 3 "EvseNotCompatible" 4 "EvseNotDetected" 5 "EvsePaused" 6 "ChargeScheduled" 7 "ChargingAC" 8 "ChargingDCFastCharge" 9 "ChargingInductive" 10 "ChargingSystemMaintain" 11 "CabinPreconditioning" 12 "DriveConditioning" 13 "ChargeTargetReached" 14 "ChargeStartCommanded" 15 "ChargeStopCommanded" 16 "GridChargeStartCommanded" 17 "GridChargeStopCommanded" 18 "Discharging" 19 "NotUsed_1" 20 "NotUsed_2" 21 "NotUsed_3" 22 "NotUsed_4" 23 "NotUsed_5" 24 "NotUsed_6" 25 "NotUsed_7" 26 "NotUsed_8" 27 "NotUsed_9" 28 "NotUsed_10" 29 "NotUsed_11" 30 "NotUsed_12" 31 "NotUsed_13" ;
VAL_ 513 BptRngeRsrvMet_B_Stat 0 "No" 1 "Yes" ;
VAL_ 513 BptPwOut_B_Dsply 0 "No" 1 "Yes" ;
VAL_ 513 BptStrtStop_D_Stat 0 "NoRequest" 1 "Stop" 2 "Start" 3 "NotUsed_1" ;
VAL_ 513 BptComm_D_RqHtrn 0 "NoDigitalCommunication" 1 "AttemptDgtlCommunication" 2 "VehicleReadyToToggle" 3 "ConfirmConnection" 4 "VehicleEnergyTransferWait" 5 "VehiclePreChargeReady" 6 "VehicleEnergyTransferReady" 7 "VehicleEnergyTransferActv" 8 "EnergyTransferEnd" 9 "EnergyTransferFault" 10 "NotUsed_1" 11 "NotUsed_2" 12 "NotUsed_3" 13 "NotUsed_4" 14 "NotUsed_5" 15 "NotUsed_6" ;
VAL_ 513 BptAllw_Pw_Dsply 1022 "NoDataExists" 1023 "Fault" ;
VAL_ 513 OnDmdCondDrv_T_Actl 2046 "NoDataExists" 2047 "Faulty" ;
VAL_ 514 StrtrMtrCtlMsgTxt_D2_Rq 0 "NoRequestBcmStartingMsgCtl" 1 "ShiftToParkToStart" 2 "ShiftToNeutralToStart" 3 "NoRequestPcmStartingMsgCtl" ;
VAL_ 514 GearRvrse_D_Actl 0 "Inactive_not_confirmed" 1 "Inactive_confirmed" 2 "Active_not_confirmed" 3 "Active_confirmed" 4 "NotUsed_1" 5 "NotUsed_2" 6 "NotUsed_3" 7 "Fault" ;
VAL_ 514 StrtrMtrCtlMsgTxt_D_Rq 0 "No_Display" 1 "Press_Clutch_To_Start" 2 "Press_Clutch_and_Brake" 3 "Press_Brk_and_Shift_to_P_N" 4 "Cranking_Limit_Exceeded" 5 "Start_Pending_Please_Wait" 6 "Pending_Start_Cancelled" 7 "Start_In_Gear_Allowed" ;
VAL_ 514 VehVTrlrAid_B_Avail 0 "No" 1 "Yes" ;
VAL_ 514 VehVActlEng_D_Qf 0 "Faulty" 1 "No_Data_Exists" 2 "Not_Within_Specifications" 3 "OK" ;
VAL_ 514 StrtrMtrDlyStrt_B_Stat 0 "No" 1 "Yes" ;
VAL_ 515 PtIgnSwtch_D_Stat 0 "Off" 1 "On" 2 "No_Data_Exists" 3 "Faulty" ;
VAL_ 515 ExtndPwDelvr_D_Stat 0 "NULL" 1 "Inactive" 2 "Active" 3 "Faulty" ;
VAL_ 516 ApedPosPcActl_D_Qf 0 "Faulty" 1 "No_Data_Exists" 2 "Not_Within_Specifications" 3 "OK" ;
VAL_ 516 ApedPos_PcRate_ActlArb 254 "Unknown" 255 "Fault" ;
VAL_ 516 EngAoutNActl_D_QF 0 "Faulty" 1 "No_Data_Exists" 2 "Not_Within_Specifications" 3 "OK" ;
VAL_ 516 EngAout3_N_Actl 65535 "Invalid" ;
VAL_ 523 EngAirFiltMsgTxt_D_Rq 0 "NoMessage" 1 "ReplaceSoon" 2 "ReplaceNow" 3 "Clogged" 4 "ResetComplete" 5 "EngineAirFilterMonitorFalt" 6 "ReducedEngPwCheckAirFilter" 7 "NotUsed_2" ;
VAL_ 523 WaterInFuel_B_Falt 0 "NoFault" 1 "Fault" ;
VAL_ 523 UreaMnAdd_L2_Actl 255 "Faulty" ;
VAL_ 523 UreaMxAdd_L2_Actl 511 "Faulty" ;
VAL_ 528 HazrdLghtMde_D_Stat 0 "Null" 1 "Off" 2 "On" 3 "NotUsed" ;
VAL_ 528 WndwCabnMde_D_Stat 0 "Null" 1 "Off" 2 "On" 3 "NotUsed" ;
VAL_ 528 OffRoadMde_D_Stat 0 "On_Road" 1 "Off_Road1" 2 "Off_Road2" 3 "NotUsed_1" 4 "NotUsed_2" 5 "NotUsed_3" 6 "NotUsed_4" 7 "NotUsed_5" ;
VAL_ 528 TireInflateMsgTxt_B_Rq 0 "No" 1 "Yes" ;
VAL_ 528 SilentMde_B_Stat 0 "Off" 1 "On" ;
VAL_ 528 VehNotConfgd_D_Rq 0 "Null" 1 "Off" 2 "On" 3 "NotUsed" ;
VAL_ 528 CrashCrtsy_B_Rq 0 "Off" 1 "On" ;
VAL_ 528 DelvrAsstButtn_D_Stat 0 "Null" 1 "OnDemand" 2 "MultipleStops" 3 "NotUsed_1" ;
VAL_ 528 DelvrAsstLckMde_D_Stat 0 "Null" 1 "Off" 2 "On" 3 "NotUsed" ;
VAL_ 528 KeylessIdlSrc_D_Stat 0 "Inactive" 1 "ProPowerOnboard" 2 "UpfitterInterface" 3 "ComfortPet" 4 "NotUsed_1" 5 "NotUsed_2" 6 "NotUsed_3" 7 "Faulty" ;
VAL_ 528 KeylessIdl_D_Stat 0 "Inactive" 1 "Armed" 2 "Active" 3 "Faulty" ;
VAL_ 528 PrmtrAlrmCrtsy_D_Rq 0 "Null" 1 "Off" 2 "On" 3 "NotUsed" ;
VAL_ 528 BodyCtlFeatReset_D_St 0 "Null" 1 "Fail" 2 "Success" 3 "NotUsed_1" 4 "NotUsed_2" 5 "NotUsed_3" 6 "NotUsed_4" 7 "NotUsed_5" 8 "NotUsed_6" 9 "NotUsed_7" 10 "NotUsed_8" 11 "NotUsed_9" 12 "NotUsed_10" 13 "NotUsed_11" 14 "NotUsed_12" 15 "NotUsed_13" 16 "NotUsed_14" 17 "NotUsed_15" 18 "NotUsed_16" 19 "NotUsed_17" 20 "NotUsed_18" 21 "NotUsed_19" 22 "NotUsed_20" 23 "NotUsed_21" 24 "NotUsed_22" 25 "NotUsed_23" 26 "NotUsed_24" 27 "NotUsed_25" 28 "NotUsed_26" 29 "NotUsed_27" 30 "NotUsed_28" 31 "NotUsed_29" 32 "NotUsed_30" 33 "NotUsed_31" 34 "NotUsed_32" 35 "NotUsed_33" 36 "NotUsed_34" 37 "NotUsed_35" 38 "NotUsed_36" 39 "NotUsed_37" 40 "NotUsed_38" 41 "NotUsed_39" 42 "NotUsed_40" 43 "NotUsed_41" 44 "NotUsed_42" 45 "NotUsed_43" 46 "NotUsed_44" 47 "NotUsed_45" 48 "NotUsed_46" 49 "NotUsed_47" 50 "NotUsed_48" 51 "NotUsed_49" 52 "NotUsed_50" 53 "NotUsed_51" 54 "NotUsed_52" 55 "NotUsed_53" 56 "NotUsed_54" 57 "NotUsed_55" 58 "NotUsed_56" 59 "NotUsed_57" 60 "NotUsed_58" 61 "NotUsed_59" 62 "NotUsed_60" 63 "NotUsed_61" 64 "NotUsed_62" 65 "NotUsed_63" 66 "NotUsed_64" 67 "NotUsed_65" 68 "NotUsed_66" 69 "NotUsed_67" 70 "NotUsed_68" 71 "NotUsed_69" 72 "NotUsed_70" 73 "NotUsed_71" 74 "NotUsed_72" 75 "NotUsed_73" 76 "NotUsed_74" 77 "NotUsed_75" 78 "NotUsed_76" 79 "NotUsed_77" 80 "NotUsed_78" 81 "NotUsed_79" 82 "NotUsed_80" 83 "NotUsed_81" 84 "NotUsed_82" 85 "NotUsed_83" 86 "NotUsed_84" 87 "NotUsed_85" 88 "NotUsed_86" 89 "NotUsed_87" 90 "NotUsed_88" 91 "NotUsed_89" 92 "NotUsed_90" 93 "NotUsed_91" 94 "NotUsed_92" 95 "NotUsed_93" 96 "NotUsed_94" 97 "NotUsed_95" 98 "NotUsed_96" 99 "NotUsed_97" 100 "NotUsed_98" 101 "NotUsed_99" 102 "NotUsed_100" 103 "NotUsed_101" 104 "NotUsed_102" 105 "NotUsed_103" 106 "NotUsed_104" 107 "NotUsed_105" 108 "NotUsed_106" 109 "NotUsed_107" 110 "NotUsed_108" 111 "NotUsed_109" 112 "NotUsed_110" 113 "NotUsed_111" 114 "NotUsed_112" 115 "NotUsed_113" 116 "NotUsed_114" 117 "NotUsed_115" 118 "NotUsed_116" 119 "NotUsed_117" 120 "NotUsed_118" 121 "NotUsed_119" 122 "NotUsed_120" 123 "NotUsed_121" 124 "NotUsed_122" 125 "NotUsed_123" 126 "NotUsed_124" 127 "NotUsed_125" 128 "NotUsed_126" 129 "NotUsed_127" 130 "NotUsed_128" 131 "NotUsed_129" 132 "NotUsed_130" 133 "NotUsed_131" 134 "NotUsed_132" 135 "NotUsed_133" 136 "NotUsed_134" 137 "NotUsed_135" 138 "NotUsed_136" 139 "NotUsed_137" 140 "NotUsed_138" 141 "NotUsed_139" 142 "NotUsed_140" 143 "NotUsed_141" 144 "NotUsed_142" 145 "NotUsed_143" 146 "NotUsed_144" 147 "NotUsed_145" 148 "NotUsed_146" 149 "NotUsed_147" 150 "NotUsed_148" 151 "NotUsed_149" 152 "NotUsed_150" 153 "NotUsed_151" 154 "NotUsed_152" 155 "NotUsed_153" 156 "NotUsed_154" 157 "NotUsed_155" 158 "NotUsed_156" 159 "NotUsed_157" 160 "NotUsed_158" 161 "NotUsed_159" 162 "NotUsed_160" 163 "NotUsed_161" 164 "NotUsed_162" 165 "NotUsed_163" 166 "NotUsed_164" 167 "NotUsed_165" 168 "NotUsed_166" 169 "NotUsed_167" 170 "NotUsed_168" 171 "NotUsed_169" 172 "NotUsed_170" 173 "NotUsed_171" 174 "NotUsed_172" 175 "NotUsed_173" 176 "NotUsed_174" 177 "NotUsed_175" 178 "NotUsed_176" 179 "NotUsed_177" 180 "NotUsed_178" 181 "NotUsed_179" 182 "NotUsed_180" 183 "NotUsed_181" 184 "NotUsed_182" 185 "NotUsed_183" 186 "NotUsed_184" 187 "NotUsed_185" 188 "NotUsed_186" 189 "NotUsed_187" 190 "NotUsed_188" 191 "NotUsed_189" 192 "NotUsed_190" 193 "NotUsed_191" 194 "NotUsed_192" 195 "NotUsed_193" 196 "NotUsed_194" 197 "NotUsed_195" 198 "NotUsed_196" 199 "NotUsed_197" 200 "NotUsed_198" 201 "NotUsed_199" 202 "NotUsed_200" 203 "NotUsed_201" 204 "NotUsed_202" 205 "NotUsed_203" 206 "NotUsed_204" 207 "NotUsed_205" 208 "NotUsed_206" 209 "NotUsed_207" 210 "NotUsed_208" 211 "NotUsed_209" 212 "NotUsed_210" 213 "NotUsed_211" 214 "NotUsed_212" 215 "NotUsed_213" 216 "NotUsed_214" 217 "NotUsed_215" 218 "NotUsed_216" 219 "NotUsed_217" 220 "NotUsed_218" 221 "NotUsed_219" 222 "NotUsed_220" 223 "NotUsed_221" 224 "NotUsed_222" 225 "NotUsed_223" 226 "NotUsed_224" 227 "NotUsed_225" 228 "NotUsed_226" 229 "NotUsed_227" 230 "NotUsed_228" 231 "NotUsed_229" 232 "NotUsed_230" 233 "NotUsed_231" 234 "NotUsed_232" 235 "NotUsed_233" 236 "NotUsed_234" 237 "NotUsed_235" 238 "NotUsed_236" 239 "NotUsed_237" 240 "NotUsed_238" 241 "NotUsed_239" 242 "NotUsed_240" 243 "NotUsed_241" 244 "NotUsed_242" 245 "NotUsed_243" 246 "NotUsed_244" 247 "NotUsed_245" 248 "NotUsed_246" 249 "NotUsed_247" 250 "NotUsed_248" 251 "NotUsed_249" 252 "NotUsed_250" 253 "NotUsed_251" 254 "NotUsed_252" 255 "NotUsed_253" ;
VAL_ 529 OnbChrgToPcWknd_D_Actl 0 "Percent_100" 1 "Percent_95" 2 "Percent_90" 3 "Percent_85" 4 "Percent_80" 5 "Percent_70" 6 "Percent_60" 7 "Percent_50" ;
VAL_ 529 OnbChrgSetDelete_B_Rq 0 "NoRequest" 1 "Request" ;
VAL_ 529 OnbChrgPrflUpdate_B_Rq 0 "NoRequest" 1 "Request" ;
VAL_ 529 OnbChrgLocIdUns_B_Rq 0 "NoRequest" 1 "Request" ;
VAL_ 529 OnbChrgToPcWkdy_D_Actl 0 "Percent_100" 1 "Percent_95" 2 "Percent_90" 3 "Percent_85" 4 "Percent_80" 5 "Percent_70" 6 "Percent_60" 7 "Percent_50" ;
VAL_ 529 OnbChrgSetNow_D_Rq 0 "Null" 1 "Off" 2 "On" 3 "NotUsed" ;
VAL_ 530 StationTypeSel_D_Rq 0 "Inactive" 1 "PI_Code" 2 "SCIDI_SID_ECC" 3 "NotUsed_1" ;
SIG_GROUP_ 303 SG_Profile1A_SigGroup_12F 1 : CanMsg12F_No_Cnt CanMsg12F_No_Crc CanMsg12F_UNUSED_1bit_1 CanMsg12F_UNUSED_2bit_1 CanMsg12F_UNUSED_2bit_2 CanMsg12F_UNUSED_2bit_3 CanMsg12F_UNUSED_2bit_4 CanMsg12F_UNUSED_3bit_1 CanMsg12F_UNUSED_8bit_1 DrChildLckPw_No_Actl DrStatHood_D2_Actl DrSwtchExtFl_No_Actl DrSwtchExtFr_No_Actl DrSwtchExtRl_No_Actl DrSwtchExtRr_No_Actl DrSwtchInnrFl_No_Actl DrSwtchInnrFr_No_Actl DrSwtchInnrRl_No_Actl DrSwtchInnrRr_No_Actl DrTgateAjar_D_Stat;
SIG_GROUP_ 334 SG_Profile1A_SigGroup_14E 1 : CanMsg14E_UNUSED_2bit_1 CanMsg14E_UNUSED_2bit_2 CanMsg14E_UNUSED_2bit_3 CanMsg14E_UNUSED_8bit_1 CanMsg14E_UNUSED_8bit_2 CanMsg14E_UNUSED_8bit_3 CanMsg14E_UNUSED_8bit_4 CanMsg14E_UNUSED_8bit_5 PdlAdj_D_Rq_1A StewPosAdjTel_D_Rq_1A StewPosAdjTlt_D_Rq_1A StewPosAdj_No_Cnt StewPosAdj_No_Crc;
SIG_GROUP_ 383 SG_Mnu_E2E_P01A 1 : DrChildLckPw_No_RqMnu HeadLghtCtl_D_RqMnu Mnu_No_Cnt Mnu_No_Crc Mnu_UNUSED_1bit Mnu_UNUSED_5bit_1 Mnu_UNUSED_8bit_2 Mnu_UNUSED_8bit_3 Mnu_UNUSED_8bit_4 Mnu_UNUSED_8bit_5 Mnu_UNUSED_8bit_6;
